VERSION ""

NS_ :

BS_:

BU_: EBOOST_CE TRCM_CE CGM_CE EPS_JR_CE MSB1_CE MSB2_CE ARS_CE SDM_CE EBCM_OBD_CE HCP_T_CE LCMS_CE APA_CE HCP_CE EOCM_F_CE MCP_C_CE MCP_B_CE MCP_A_CE FCM_CE ICCM_CE Dummy_CE TestTool_CE ACC_CE RDCM_CE EBCM_CE SADS_CE IMU_CE SAS_CE EPS_CE

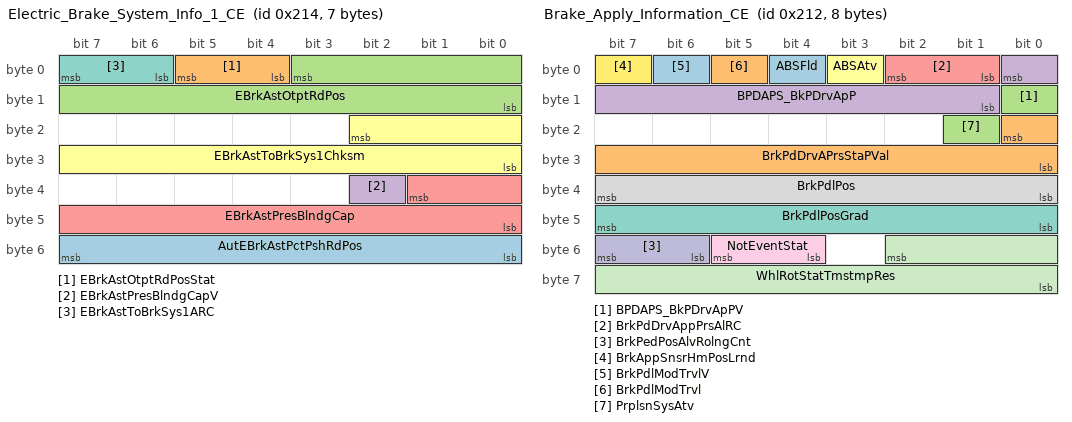
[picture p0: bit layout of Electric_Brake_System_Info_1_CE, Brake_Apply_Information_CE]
BO_ 532 Electric_Brake_System_Info_1_CE: 7 EBOOST_CE
 SG_ AutEBrkAstPctPshRdPos : 55|8@0+ (0.392157,0) [0|100.000035] "% full"  EBCM_OBD_CE,EBCM_CE
 SG_ EBrkAstOtptRdPosStat : 5|2@0+ (1,0) [0|3] ""  EBCM_OBD_CE,EBCM_CE
 SG_ EBrkAstOtptRdPos : 3|12@0+ (0.015625,-5) [-5|58.984375] "mm"  EBCM_OBD_CE,EBCM_CE
 SG_ EBrkAstPresBlndgCapV : 34|1@0+ (1,0) [0|1] ""  EBCM_OBD_CE,EBCM_CE
 SG_ EBrkAstPresBlndgCap : 33|10@0+ (0.25,0) [0|255.75] "bar"  EBCM_OBD_CE,EBCM_CE
 SG_ EBrkAstToBrkSys1Chksm : 18|11@0+ (1,0) [0|2047] ""  EBCM_OBD_CE,EBCM_CE
 SG_ EBrkAstToBrkSys1ARC : 7|2@0+ (1,0) [0|3] ""  EBCM_OBD_CE,EBCM_CE

BO_ 530 Brake_Apply_Information_CE: 8 EBCM_CE
 SG_ ABSFld : 4|1@0+ (1,0) [0|1] ""  SDM_CE,EPS_JR_CE
 SG_ BrkPdDrvAPrsStaPVal : 16|9@0+ (1,0) [0|511] ""  SADS_CE,MSB1_CE,MSB2_CE
 SG_ BPDAPS_BkPDrvApPV : 8|1@0+ (1,0) [0|1] ""  SADS_CE,MSB1_CE,MSB2_CE
 SG_ BPDAPS_BkPDrvApP : 0|8@0+ (75,0) [0|19125] "kPa"  SADS_CE,MSB1_CE,MSB2_CE
 SG_ BrkPdDrvAppPrsAlRC : 2|2@0+ (1,0) [0|3] ""  SADS_CE,MSB1_CE,MSB2_CE
 SG_ ABSAtv : 3|1@0+ (1,0) [0|1] ""  RDCM_CE,SDM_CE,MSB1_CE,MSB2_CE,EPS_JR_CE,EPS_CE
 SG_ BrkPdlPosGrad : 47|8@0- (40,0) [-5120|5080] "%/s"  EPS_JR_CE,MSB1_CE,MSB2_CE
 SG_ BrkPdlPos : 39|8@0+ (0.392157,0) [0|100.000035] "% full"  EPS_JR_CE,MSB1_CE,MSB2_CE
 SG_ NotEventStat : 53|2@0+ (1,0) [0|3] ""  EPS_JR_CE
 SG_ BrkPedPosAlvRolngCnt : 55|2@0+ (1,0) [0|3] ""  EPS_JR_CE
 SG_ WhlRotStatTmstmpRes : 50|11@0+ (0.002,0) [0|4.094] "uSec"  ARS_CE,APA_CE,RDCM_CE,EPS_JR_CE,EBOOST_CE
 SG_ BrkAppSnsrHmPosLrnd : 7|1@0+ (1,0) [0|1] ""  EPS_JR_CE
 SG_ BrkPdlModTrvlV : 6|1@0+ (1,0) [0|1] ""  EPS_JR_CE,MSB1_CE,MSB2_CE
 SG_ BrkPdlModTrvl : 5|1@0+ (1,0) [0|1] ""  EPS_JR_CE,MSB1_CE,MSB2_CE
 SG_ PrplsnSysAtv : 17|1@0+ (1,0) [0|1] ""  EBOOST_CE

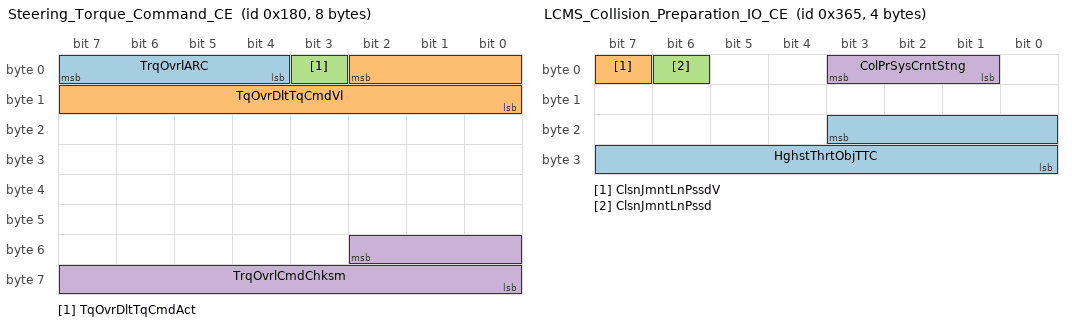
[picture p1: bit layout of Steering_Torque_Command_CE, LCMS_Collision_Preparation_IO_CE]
BO_ 384 Steering_Torque_Command_CE: 8 EBCM_CE
 SG_ TrqOvrlARC : 7|4@0+ (1,0) [0|15] "counts"  EPS_CE,EPS_JR_CE
 SG_ TqOvrDltTqCmdVl : 2|11@0- (0.01,0) [-10.24|10.23] "Nm"  EPS_CE,EPS_JR_CE
 SG_ TqOvrDltTqCmdAct : 3|1@0+ (1,0) [0|1] ""  EPS_CE,EPS_JR_CE
 SG_ TrqOvrlCmdChksm : 50|11@0+ (1,0) [0|2047] ""  EPS_CE,EPS_JR_CE

BO_ 869 LCMS_Collision_Preparation_IO_CE: 4 ACC_CE
 SG_ HghstThrtObjTTC : 19|12@0+ (2,0) [0|8190] "ms"  MSB1_CE,MSB2_CE
 SG_ ClsnJmntLnPssdV : 7|1@0+ (1,0) [0|1] ""  MSB1_CE,MSB2_CE
 SG_ ClsnJmntLnPssd : 6|1@0+ (1,0) [0|1] ""  MSB1_CE,MSB2_CE
 SG_ ColPrSysCrntStng : 3|3@0+ (1,0) [0|7] ""  MSB1_CE,MSB2_CE

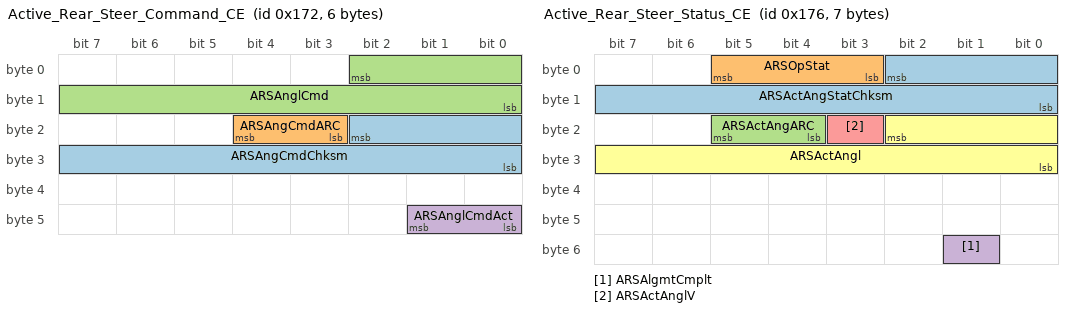
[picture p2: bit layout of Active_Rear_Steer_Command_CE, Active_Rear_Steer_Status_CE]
BO_ 370 Active_Rear_Steer_Command_CE: 6 EBCM_CE
 SG_ ARSAngCmdChksm : 18|11@0+ (1,0) [0|2047] ""  ARS_CE
 SG_ ARSAngCmdARC : 20|2@0+ (1,0) [0|3] ""  ARS_CE
 SG_ ARSAnglCmd : 2|11@0- (0.01,0) [-10.24|10.23] "deg"  ARS_CE
 SG_ ARSAnglCmdAct : 41|2@0+ (1,0) [0|3] ""  ARS_CE

BO_ 374 Active_Rear_Steer_Status_CE: 7 ARS_CE
 SG_ ARSActAngStatChksm : 2|11@0+ (1,0) [0|2047] ""  EOCM_F_CE,MSB2_CE,MSB1_CE,APA_CE,EBCM_OBD_CE,EBCM_CE
 SG_ ARSOpStat : 5|3@0+ (1,0) [0|7] ""  EOCM_F_CE,MSB2_CE,MSB1_CE,APA_CE,EBCM_OBD_CE,EBCM_CE
 SG_ ARSActAngARC : 21|2@0+ (1,0) [0|3] ""  MSB1_CE,EOCM_F_CE,MSB2_CE,APA_CE,EBCM_OBD_CE,EBCM_CE
 SG_ ARSAlgmtCmplt : 49|1@0+ (1,0) [0|1] ""  EOCM_F_CE,MSB2_CE,MSB1_CE,APA_CE,EBCM_OBD_CE,EBCM_CE
 SG_ ARSActAnglV : 19|1@0+ (1,0) [0|1] ""  MSB1_CE,EOCM_F_CE,MSB2_CE,APA_CE,EBCM_OBD_CE,EBCM_CE
 SG_ ARSActAngl : 18|11@0- (0.01,0) [-10.24|10.23] "deg"  EOCM_F_CE,MSB2_CE,MSB1_CE,APA_CE,EBCM_OBD_CE,EBCM_CE

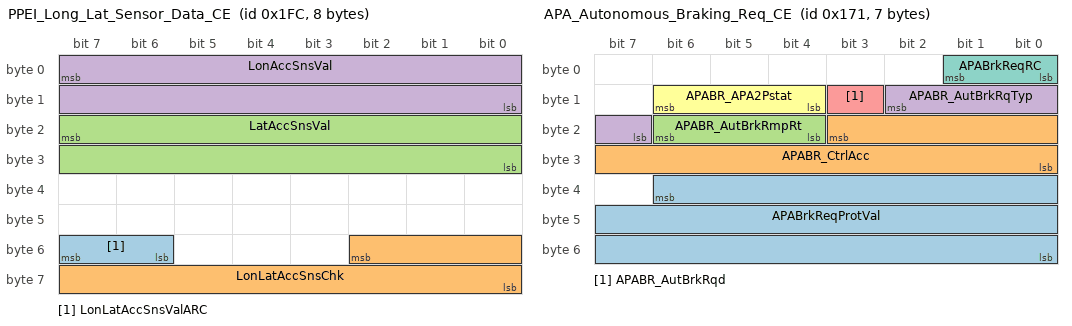
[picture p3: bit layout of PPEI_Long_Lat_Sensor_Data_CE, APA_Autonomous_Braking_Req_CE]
BO_ 508 PPEI_Long_Lat_Sensor_Data_CE: 8 IMU_CE
 SG_ LonLatAccSnsValARC : 55|2@0+ (1,0) [0|3] ""  EBCM_OBD_CE,EBCM_CE
 SG_ LonLatAccSnsChk : 50|11@0+ (1,0) [0|2047] ""  EBCM_OBD_CE,EBCM_CE
 SG_ LatAccSnsVal : 23|16@0- (0.00012207,0) [-3.99998976|3.99986769] "g's"  EBCM_OBD_CE,EBCM_CE
 SG_ LonAccSnsVal : 7|16@0- (0.00012207,0) [-3.99998976|3.99986769] "g's"  EBCM_OBD_CE,EBCM_CE

BO_ 2029 USDT_Resp_From_OBD_Device5_CE: 8 EBCM_OBD_CE
 SG_ DgnInf : 7|64@0+ (1,0) [0|1.84467440737096E+019] ""  TestTool_CE

BO_ 1517 UUDT_Resp_From_OBD_Device5_CE: 8 EBCM_OBD_CE
 SG_ DgnInf : 7|64@0+ (1,0) [0|1.84467440737096E+019] ""  TestTool_CE

BO_ 369 APA_Autonomous_Braking_Req_CE: 7 APA_CE
 SG_ APABrkReqProtVal : 38|23@0+ (1,0) [0|8388607] ""  EBCM_OBD_CE,EBCM_CE
 SG_ APABR_CtrlAcc : 19|12@0- (0.01,0) [-20.48|20.47] "m/s^2"  EBCM_OBD_CE,EBCM_CE
 SG_ APABR_AutBrkRmpRt : 22|3@0+ (1,0) [0|7] ""  EBCM_OBD_CE,EBCM_CE
 SG_ APABR_AutBrkRqTyp : 10|4@0+ (1,0) [0|15] ""  EBCM_OBD_CE,EBCM_CE
 SG_ APABR_AutBrkRqd : 11|1@0+ (1,0) [0|1] ""  EBCM_OBD_CE,EBCM_CE
 SG_ APABR_APA2Pstat : 14|3@0+ (1,0) [0|7] ""  EBCM_OBD_CE,EBCM_CE
 SG_ APABrkReqRC : 1|2@0+ (1,0) [0|3] ""  EBCM_OBD_CE,EBCM_CE

BO_ 2021 USDT_Req_to_OBD_Device5_CE: 8 TestTool_CE
 SG_ DgnInf : 7|64@0+ (1,0) [0|1.84467440737096E+019] ""  EBCM_OBD_CE

BO_ 562 Axle_Torque_Imm_Capacity_CE: 4 HCP_CE
 SG_ AxlTrqMinImTrqCap : 22|15@0+ (2,-22534) [-22534|43000] "Nm"  EBCM_OBD_CE,EBCM_CE
 SG_ AxlTrqMaxImTrqCap : 6|15@0+ (2,-22534) [-22534|43000] "Nm"  EBCM_OBD_CE,EBCM_CE

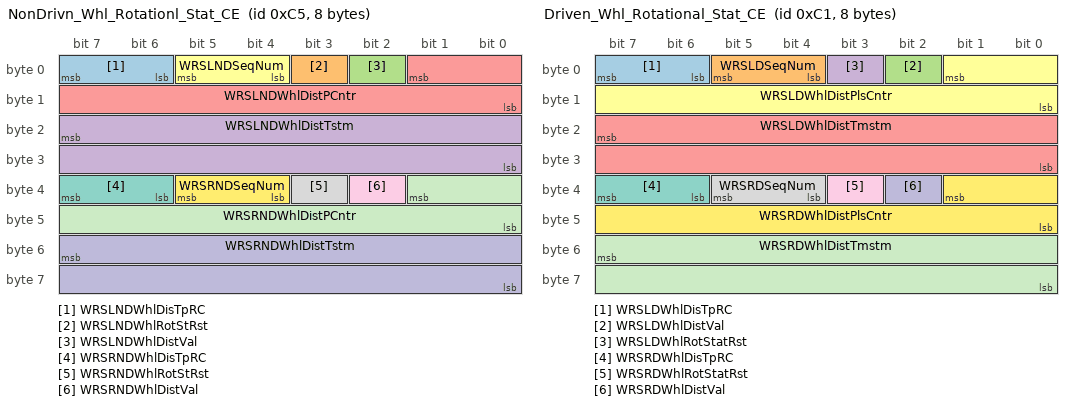
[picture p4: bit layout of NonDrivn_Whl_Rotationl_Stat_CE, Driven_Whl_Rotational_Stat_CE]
BO_ 197 NonDrivn_Whl_Rotationl_Stat_CE: 8 EBCM_CE
 SG_ WRSLNDWhlDisTpRC : 7|2@0+ (1,0) [0|3] "counts"  HCP_T_CE,HCP_CE,ICCM_CE,EPS_JR_CE,RDCM_CE,SDM_CE,ARS_CE,EOCM_F_CE,APA_CE
 SG_ WRSLNDWhlRotStRst : 3|1@0+ (1,0) [0|1] ""  HCP_T_CE,HCP_CE,ICCM_CE,EPS_JR_CE,RDCM_CE,SDM_CE,ARS_CE,EOCM_F_CE,APA_CE
 SG_ WRSLNDWhlDistVal : 2|1@0+ (1,0) [0|1] ""  HCP_T_CE,HCP_CE,ICCM_CE,EPS_JR_CE,RDCM_CE,SDM_CE,ARS_CE,EOCM_F_CE,APA_CE
 SG_ WRSLNDWhlDistTstm : 23|16@0+ (1,0) [0|65535] "counts"  HCP_T_CE,HCP_CE,ICCM_CE,EPS_JR_CE,RDCM_CE,SDM_CE,ARS_CE,EOCM_F_CE,APA_CE
 SG_ WRSLNDWhlDistPCntr : 1|10@0+ (1,0) [0|1023] "counts"  HCP_T_CE,HCP_CE,ICCM_CE,EPS_JR_CE,RDCM_CE,SDM_CE,ARS_CE,EOCM_F_CE,APA_CE
 SG_ WRSLNDSeqNum : 5|2@0+ (1,0) [0|3] "counts"  HCP_T_CE,HCP_CE,ICCM_CE,EPS_JR_CE,RDCM_CE,SDM_CE,ARS_CE,EOCM_F_CE,APA_CE
 SG_ WRSRNDWhlDisTpRC : 39|2@0+ (1,0) [0|3] "counts"  HCP_T_CE,HCP_CE,ICCM_CE,EPS_JR_CE,RDCM_CE,SDM_CE,ARS_CE,EOCM_F_CE,APA_CE
 SG_ WRSRNDWhlRotStRst : 35|1@0+ (1,0) [0|1] ""  HCP_T_CE,HCP_CE,ICCM_CE,EPS_JR_CE,RDCM_CE,SDM_CE,ARS_CE,EOCM_F_CE,APA_CE
 SG_ WRSRNDWhlDistVal : 34|1@0+ (1,0) [0|1] ""  HCP_T_CE,HCP_CE,ICCM_CE,EPS_JR_CE,RDCM_CE,SDM_CE,ARS_CE,EOCM_F_CE,APA_CE
 SG_ WRSRNDWhlDistTstm : 55|16@0+ (1,0) [0|65535] "counts"  HCP_T_CE,HCP_CE,ICCM_CE,EPS_JR_CE,RDCM_CE,SDM_CE,ARS_CE,EOCM_F_CE,APA_CE
 SG_ WRSRNDWhlDistPCntr : 33|10@0+ (1,0) [0|1023] "counts"  HCP_T_CE,HCP_CE,ICCM_CE,EPS_JR_CE,RDCM_CE,SDM_CE,ARS_CE,EOCM_F_CE,APA_CE
 SG_ WRSRNDSeqNum : 37|2@0+ (1,0) [0|3] "counts"  HCP_T_CE,HCP_CE,ICCM_CE,EPS_JR_CE,RDCM_CE,SDM_CE,ARS_CE,EOCM_F_CE,APA_CE

BO_ 193 Driven_Whl_Rotational_Stat_CE: 8 EBCM_CE
 SG_ WRSLDWhlDisTpRC : 7|2@0+ (1,0) [0|3] "counts"  TRCM_CE,HCP_T_CE,HCP_CE,ICCM_CE,EPS_JR_CE,RDCM_CE,SDM_CE,ARS_CE,EOCM_F_CE,APA_CE
 SG_ WRSLDSeqNum : 5|2@0+ (1,0) [0|3] "counts"  TRCM_CE,HCP_T_CE,HCP_CE,ICCM_CE,EPS_JR_CE,RDCM_CE,SDM_CE,ARS_CE,EOCM_F_CE,APA_CE
 SG_ WRSLDWhlDistVal : 2|1@0+ (1,0) [0|1] ""  TRCM_CE,HCP_T_CE,HCP_CE,ICCM_CE,EPS_JR_CE,RDCM_CE,SDM_CE,ARS_CE,EOCM_F_CE,APA_CE
 SG_ WRSLDWhlRotStatRst : 3|1@0+ (1,0) [0|1] ""  TRCM_CE,HCP_T_CE,HCP_CE,ICCM_CE,EPS_JR_CE,RDCM_CE,SDM_CE,ARS_CE,EOCM_F_CE,APA_CE
 SG_ WRSLDWhlDistTmstm : 23|16@0+ (1,0) [0|65535] "counts"  TRCM_CE,HCP_T_CE,HCP_CE,ICCM_CE,EPS_JR_CE,RDCM_CE,SDM_CE,ARS_CE,EOCM_F_CE,APA_CE
 SG_ WRSLDWhlDistPlsCntr : 1|10@0+ (1,0) [0|1023] "counts"  TRCM_CE,HCP_T_CE,HCP_CE,ICCM_CE,EPS_JR_CE,RDCM_CE,SDM_CE,ARS_CE,EOCM_F_CE,APA_CE
 SG_ WRSRDWhlDisTpRC : 39|2@0+ (1,0) [0|3] "counts"  TRCM_CE,HCP_T_CE,HCP_CE,ICCM_CE,EPS_JR_CE,RDCM_CE,SDM_CE,ARS_CE,EOCM_F_CE,APA_CE
 SG_ WRSRDSeqNum : 37|2@0+ (1,0) [0|3] "counts"  TRCM_CE,HCP_T_CE,HCP_CE,ICCM_CE,EPS_JR_CE,RDCM_CE,SDM_CE,ARS_CE,EOCM_F_CE,APA_CE
 SG_ WRSRDWhlRotStatRst : 35|1@0+ (1,0) [0|1] ""  TRCM_CE,HCP_T_CE,HCP_CE,ICCM_CE,EPS_JR_CE,RDCM_CE,SDM_CE,ARS_CE,EOCM_F_CE,APA_CE
 SG_ WRSRDWhlDistVal : 34|1@0+ (1,0) [0|1] ""  TRCM_CE,HCP_T_CE,HCP_CE,ICCM_CE,EPS_JR_CE,RDCM_CE,SDM_CE,ARS_CE,EOCM_F_CE,APA_CE
 SG_ WRSRDWhlDistTmstm : 55|16@0+ (1,0) [0|65535] "counts"  TRCM_CE,HCP_T_CE,HCP_CE,ICCM_CE,EPS_JR_CE,RDCM_CE,SDM_CE,ARS_CE,EOCM_F_CE,APA_CE
 SG_ WRSRDWhlDistPlsCntr : 33|10@0+ (1,0) [0|1023] "counts"  TRCM_CE,HCP_T_CE,HCP_CE,ICCM_CE,EPS_JR_CE,RDCM_CE,SDM_CE,ARS_CE,EOCM_F_CE,APA_CE

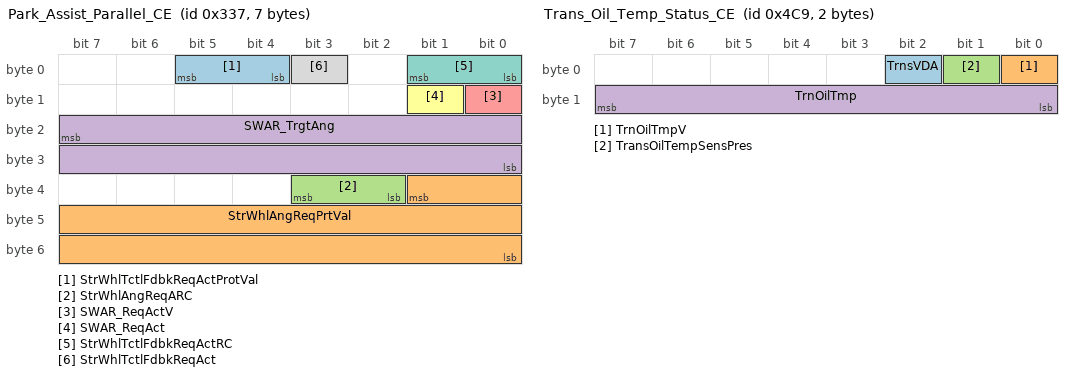
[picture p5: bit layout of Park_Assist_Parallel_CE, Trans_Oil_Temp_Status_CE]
BO_ 823 Park_Assist_Parallel_CE: 7 APA_CE
 SG_ StrWhlTctlFdbkReqActProtVal : 5|2@0+ (1,0) [0|3] ""  EPS_JR_CE,EPS_CE
 SG_ StrWhlAngReqPrtVal : 33|18@0+ (1,0) [0|262143] ""  EPS_JR_CE,EPS_CE
 SG_ StrWhlAngReqARC : 35|2@0+ (1,0) [0|3] ""  EPS_JR_CE,EPS_CE
 SG_ SWAR_TrgtAng : 23|16@0- (0.0625,0) [-2048|2047.9375] "Degree"  EPS_JR_CE,EPS_CE
 SG_ SWAR_ReqActV : 8|1@0+ (1,0) [0|1] ""  EPS_JR_CE,EPS_CE
 SG_ SWAR_ReqAct : 9|1@0+ (1,0) [0|1] ""  EPS_JR_CE,EPS_CE
 SG_ StrWhlTctlFdbkReqActRC : 1|2@0+ (1,0) [0|3] ""  EPS_CE,EPS_JR_CE
 SG_ StrWhlTctlFdbkReqAct : 3|1@0+ (1,0) [0|1] ""  EPS_CE,EPS_JR_CE

BO_ 1225 Trans_Oil_Temp_Status_CE: 2 ICCM_CE
 SG_ TrnsVDA : 2|1@0+ (1,0) [0|1] ""  RDCM_CE
 SG_ TrnOilTmpV : 0|1@0+ (1,0) [0|1] ""  RDCM_CE
 SG_ TransOilTempSensPres : 1|1@0+ (1,0) [0|1] ""  RDCM_CE
 SG_ TrnOilTmp : 15|8@0+ (1,-40) [-40|215] "deg C"  RDCM_CE

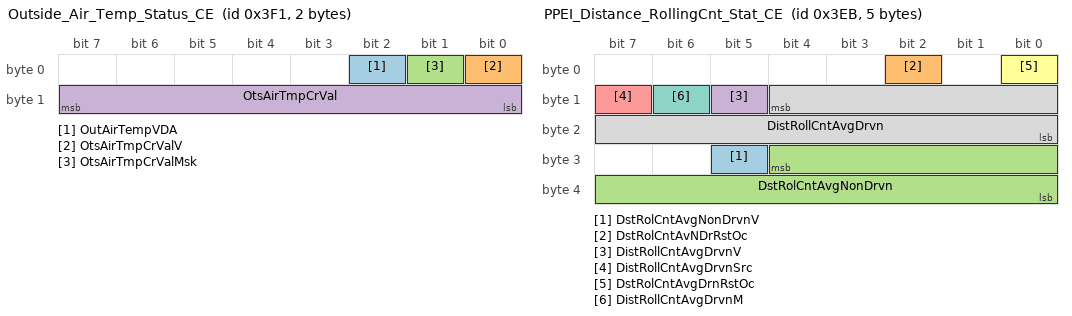
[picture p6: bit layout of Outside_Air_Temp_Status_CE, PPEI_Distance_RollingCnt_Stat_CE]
BO_ 1009 Outside_Air_Temp_Status_CE: 2 ICCM_CE
 SG_ OutAirTempVDA : 2|1@0+ (1,0) [0|1] ""  RDCM_CE
 SG_ OtsAirTmpCrValV : 0|1@0+ (1,0) [0|1] ""  RDCM_CE
 SG_ OtsAirTmpCrValMsk : 1|1@0+ (1,0) [0|1] ""  RDCM_CE
 SG_ OtsAirTmpCrVal : 15|8@0+ (0.5,-40) [-40|87.5] "deg C"  RDCM_CE

BO_ 536 PPEI_Vehicle_Speed_Status_1_CE: 6 ICCM_CE
 SG_ VehOdoV : 8|1@0+ (1,0) [0|1] ""  RDCM_CE
 SG_ VehOdo : 23|32@0+ (0.015625,0) [0|67108863.984375] "km"  RDCM_CE

BO_ 1003 PPEI_Distance_RollingCnt_Stat_CE: 5 EBCM_CE
 SG_ DstRolCntAvgNonDrvnV : 29|1@0+ (1,0) [0|1] ""  EPS_JR_CE
 SG_ DstRolCntAvNDrRstOc : 2|1@0+ (1,0) [0|1] ""  EPS_JR_CE
 SG_ DstRolCntAvgNonDrvn : 28|13@0+ (0.125,0) [0|1023.875] "m"  EPS_JR_CE
 SG_ DistRollCntAvgDrvnV : 13|1@0+ (1,0) [0|1] ""  EPS_JR_CE
 SG_ DistRollCntAvgDrvnSrc : 15|1@0+ (1,0) [0|1] ""  EPS_JR_CE
 SG_ DstRolCntAvgDrnRstOc : 0|1@0+ (1,0) [0|1] ""  EPS_JR_CE
 SG_ DistRollCntAvgDrvnM : 14|1@0+ (1,0) [0|1] ""  EPS_JR_CE
 SG_ DistRollCntAvgDrvn : 12|13@0+ (0.125,0) [0|1023.875] "m"  EPS_JR_CE

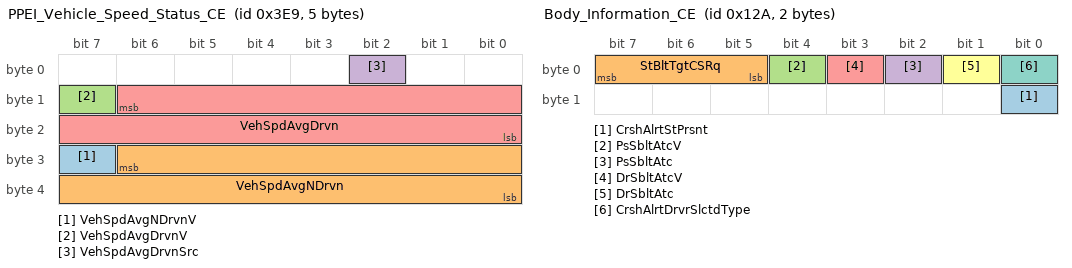
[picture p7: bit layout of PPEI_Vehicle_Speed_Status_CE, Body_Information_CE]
BO_ 1001 PPEI_Vehicle_Speed_Status_CE: 5 EBCM_CE
 SG_ VehSpdAvgNDrvnV : 31|1@0+ (1,0) [0|1] ""  ARS_CE,SDM_CE,FCM_CE,RDCM_CE,EPS_JR_CE
 SG_ VehSpdAvgNDrvn : 30|15@0+ (0.015625,0) [0|511.984375] "km / h"  ARS_CE,SDM_CE,FCM_CE,RDCM_CE,EPS_JR_CE
 SG_ VehSpdAvgDrvnV : 15|1@0+ (1,0) [0|1] ""  ARS_CE,SDM_CE,FCM_CE,EPS_JR_CE,EPS_CE
 SG_ VehSpdAvgDrvnSrc : 2|1@0+ (1,0) [0|1] ""  ARS_CE,EPS_JR_CE,EPS_CE
 SG_ VehSpdAvgDrvn : 14|15@0+ (0.015625,0) [0|511.984375] "km / h"  ARS_CE,SDM_CE,FCM_CE,EPS_JR_CE,EPS_CE

BO_ 298 Body_Information_CE: 2 EBCM_CE
 SG_ CrshAlrtStPrsnt : 8|1@0+ (1,0) [0|1] ""  MSB1_CE,MSB2_CE
 SG_ StBltTgtCSRq : 7|3@0+ (1,0) [0|7] ""  MSB1_CE,MSB2_CE
 SG_ PsSbltAtcV : 4|1@0+ (1,0) [0|1] ""  MSB1_CE,MSB2_CE
 SG_ PsSbltAtc : 2|1@0+ (1,0) [0|1] ""  MSB1_CE,MSB2_CE
 SG_ DrSbltAtcV : 3|1@0+ (1,0) [0|1] ""  MSB1_CE,MSB2_CE
 SG_ DrSbltAtc : 1|1@0+ (1,0) [0|1] ""  MSB1_CE,MSB2_CE
 SG_ CrshAlrtDrvrSlctdType : 0|1@0+ (1,0) [0|1] ""  MSB1_CE,MSB2_CE

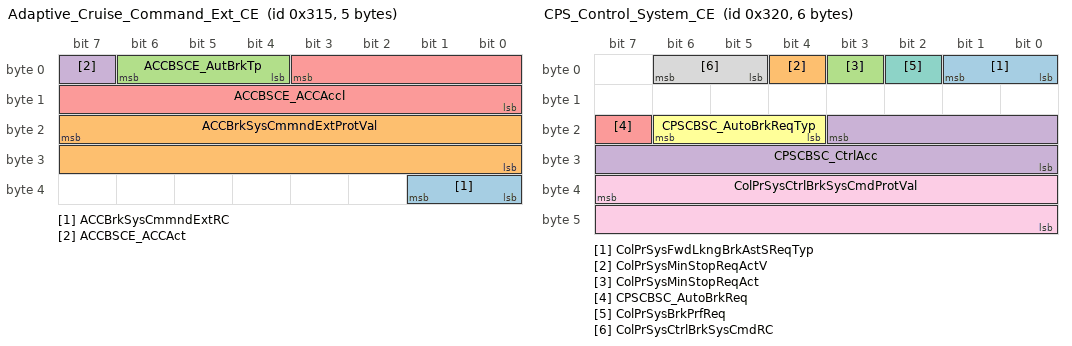
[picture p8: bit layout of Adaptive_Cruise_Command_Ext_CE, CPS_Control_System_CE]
BO_ 789 Adaptive_Cruise_Command_Ext_CE: 5 ACC_CE
 SG_ ACCBrkSysCmmndExtRC : 33|2@0+ (1,0) [0|3] ""  EBCM_OBD_CE,EBCM_CE
 SG_ ACCBrkSysCmmndExtProtVal : 23|16@0+ (1,0) [0|65535] ""  EBCM_OBD_CE,EBCM_CE
 SG_ ACCBSCE_AutBrkTp : 6|3@0+ (1,0) [0|7] ""  SADS_CE,EBCM_OBD_CE,EBCM_CE
 SG_ ACCBSCE_ACCAct : 7|1@0+ (1,0) [0|1] ""  SADS_CE,EBCM_OBD_CE,EBCM_CE
 SG_ ACCBSCE_ACCAccl : 3|12@0- (0.01,0) [-20.48|20.47] "m/s^2"  SADS_CE,EBCM_OBD_CE,EBCM_CE

BO_ 800 CPS_Control_System_CE: 6 ACC_CE
 SG_ ColPrSysFwdLkngBrkAstSReqTyp : 1|2@0+ (1,0) [0|3] ""  EOCM_F_CE,EBCM_OBD_CE,EBCM_CE
 SG_ ColPrSysMinStopReqActV : 4|1@0+ (1,0) [0|1] ""  EBCM_OBD_CE,EBCM_CE,EOCM_F_CE
 SG_ ColPrSysMinStopReqAct : 3|1@0+ (1,0) [0|1] ""  EOCM_F_CE,EBCM_OBD_CE,EBCM_CE
 SG_ CPSCBSC_CtrlAcc : 19|12@0- (0.01,0) [-20.48|20.47] "m/s^2"  EOCM_F_CE,EBCM_OBD_CE,EBCM_CE
 SG_ CPSCBSC_AutoBrkReq : 23|1@0+ (1,0) [0|1] ""  EOCM_F_CE,EBCM_OBD_CE,EBCM_CE
 SG_ CPSCBSC_AutoBrkReqTyp : 22|3@0+ (1,0) [0|7] ""  EOCM_F_CE,EBCM_OBD_CE,EBCM_CE
 SG_ ColPrSysBrkPrfReq : 2|1@0+ (1,0) [0|1] ""  EOCM_F_CE,EBCM_OBD_CE,EBCM_CE
 SG_ ColPrSysCtrlBrkSysCmdRC : 6|2@0+ (1,0) [0|3] ""  EOCM_F_CE,EBCM_OBD_CE,EBCM_CE
 SG_ ColPrSysCtrlBrkSysCmdProtVal : 39|16@0+ (1,0) [0|65535] ""  EOCM_F_CE,EBCM_OBD_CE,EBCM_CE

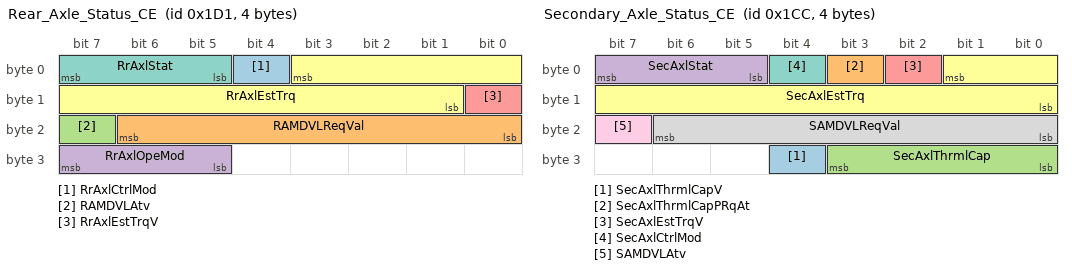
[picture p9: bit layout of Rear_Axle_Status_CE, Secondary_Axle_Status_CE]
BO_ 465 Rear_Axle_Status_CE: 4 RDCM_CE
 SG_ RrAxlCtrlMod : 4|1@0+ (1,0) [0|1] ""  EBCM_OBD_CE,EBCM_CE
 SG_ RAMDVLReqVal : 22|7@0+ (2,0) [0|254] "rpm"  EBCM_OBD_CE,EBCM_CE
 SG_ RAMDVLAtv : 23|1@0+ (1,0) [0|1] ""  EBCM_OBD_CE,EBCM_CE
 SG_ RrAxlOpeMod : 31|3@0+ (1,0) [0|7] ""  EBCM_OBD_CE,EBCM_CE
 SG_ RrAxlEstTrqV : 8|1@0+ (1,0) [0|1] ""  EBCM_OBD_CE,EBCM_CE
 SG_ RrAxlEstTrq : 3|11@0- (5,0) [-5120|5115] "Nm"  EBCM_OBD_CE,EBCM_CE
 SG_ RrAxlStat : 7|3@0+ (1,0) [0|7] ""  EBCM_OBD_CE,EBCM_CE

BO_ 460 Secondary_Axle_Status_CE: 4 RDCM_CE
 SG_ SecAxlThrmlCapV : 28|1@0+ (1,0) [0|1] ""  EBCM_OBD_CE,EBCM_CE
 SG_ SecAxlThrmlCapPRqAt : 3|1@0+ (1,0) [0|1] ""  EBCM_OBD_CE,EBCM_CE
 SG_ SecAxlThrmlCap : 27|4@0+ (6.7,0) [0|100.5] "%"  EBCM_OBD_CE,EBCM_CE
 SG_ SecAxlStat : 7|3@0+ (1,0) [0|7] ""  EBCM_OBD_CE,EBCM_CE
 SG_ SecAxlEstTrqV : 2|1@0+ (1,0) [0|1] ""  EBCM_OBD_CE,EBCM_CE
 SG_ SecAxlEstTrq : 1|10@0+ (10,0) [0|10230] "Nm"  EBCM_OBD_CE,EBCM_CE
 SG_ SecAxlCtrlMod : 4|1@0+ (1,0) [0|1] ""  EBCM_OBD_CE,EBCM_CE
 SG_ SAMDVLReqVal : 22|7@0+ (2,0) [0|254] ""  EBCM_OBD_CE,EBCM_CE
 SG_ SAMDVLAtv : 23|1@0+ (1,0) [0|1] ""  EBCM_OBD_CE,EBCM_CE

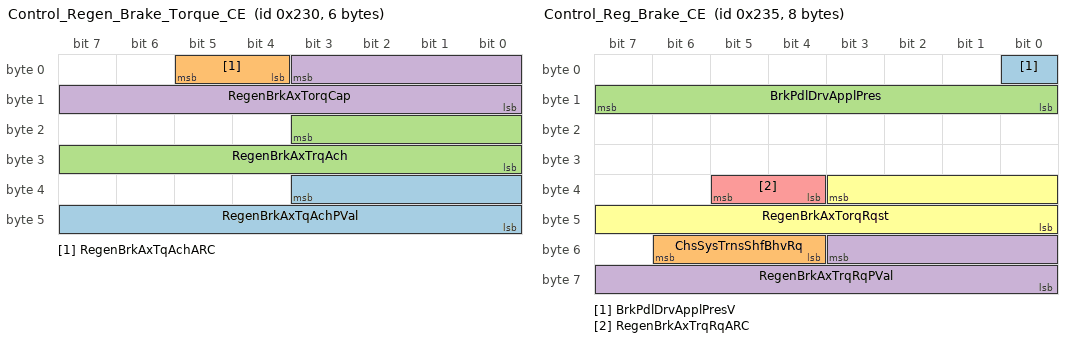
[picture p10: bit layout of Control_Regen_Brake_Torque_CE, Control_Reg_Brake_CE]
BO_ 560 Control_Regen_Brake_Torque_CE: 6 HCP_CE
 SG_ RegenBrkAxTqAchPVal : 35|12@0+ (1,0) [0|4095] ""  EBCM_OBD_CE,EBCM_CE
 SG_ RegenBrkAxTqAchARC : 5|2@0+ (1,0) [0|3] ""  EBCM_OBD_CE,EBCM_CE
 SG_ RegenBrkAxTrqAch : 19|12@0+ (2,0) [0|8190] "Nm"  EBCM_OBD_CE,EBCM_CE
 SG_ RegenBrkAxTorqCap : 3|12@0+ (2,0) [0|8190] "Nm"  EBCM_OBD_CE,EBCM_CE

BO_ 565 Control_Reg_Brake_CE: 8 EBCM_CE
 SG_ BrkPdlDrvApplPresV : 0|1@0+ (1,0) [0|1] ""  EPS_JR_CE
 SG_ ChsSysTrnsShfBhvRq : 54|3@0+ (1,0) [0|7] ""  HCP_T_CE,HCP_CE
 SG_ BrkPdlDrvApplPres : 15|8@0+ (75,0) [0|19125] "kPa"  EPS_JR_CE
 SG_ RegenBrkAxTrqRqPVal : 51|12@0+ (1,0) [0|4095] ""  HCP_T_CE,HCP_CE
 SG_ RegenBrkAxTrqRqARC : 37|2@0+ (1,0) [0|3] ""  HCP_T_CE,HCP_CE
 SG_ RegenBrkAxTorqRqst : 35|12@0+ (2,0) [0|8190] "Nm"  HCP_T_CE,HCP_CE

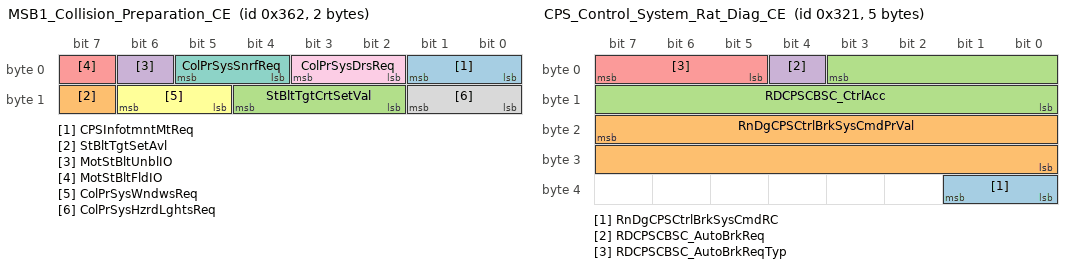
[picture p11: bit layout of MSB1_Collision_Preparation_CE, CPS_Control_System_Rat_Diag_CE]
BO_ 866 MSB1_Collision_Preparation_CE: 2 MSB1_CE
 SG_ CPSInfotmntMtReq : 1|2@0+ (1,0) [0|3] ""  EBCM_OBD_CE,EBCM_CE
 SG_ StBltTgtSetAvl : 15|1@0+ (1,0) [0|1] ""  EBCM_OBD_CE,EBCM_CE
 SG_ StBltTgtCrtSetVal : 12|3@0+ (1,0) [0|7] ""  EBCM_OBD_CE,EBCM_CE
 SG_ MotStBltUnblIO : 6|1@0+ (1,0) [0|1] ""  EBCM_OBD_CE,EBCM_CE
 SG_ MotStBltFldIO : 7|1@0+ (1,0) [0|1] ""  EBCM_OBD_CE,EBCM_CE
 SG_ ColPrSysWndwsReq : 14|2@0+ (1,0) [0|3] ""  EBCM_OBD_CE,EBCM_CE
 SG_ ColPrSysSnrfReq : 5|2@0+ (1,0) [0|3] ""  EBCM_OBD_CE,EBCM_CE
 SG_ ColPrSysHzrdLghtsReq : 9|2@0+ (1,0) [0|3] ""  EBCM_OBD_CE,EBCM_CE
 SG_ ColPrSysDrsReq : 3|2@0+ (1,0) [0|3] ""  EBCM_OBD_CE,EBCM_CE

BO_ 801 CPS_Control_System_Rat_Diag_CE: 5 ACC_CE
 SG_ RnDgCPSCtrlBrkSysCmdRC : 33|2@0+ (1,0) [0|3] ""  EBCM_OBD_CE,EBCM_CE
 SG_ RnDgCPSCtrlBrkSysCmdPrVal : 23|16@0+ (1,0) [0|65535] ""  EBCM_OBD_CE,EBCM_CE
 SG_ RDCPSCBSC_CtrlAcc : 3|12@0- (0.01,0) [-20.48|20.47] "m/s^2"  EBCM_OBD_CE,EBCM_CE
 SG_ RDCPSCBSC_AutoBrkReq : 4|1@0+ (1,0) [0|1] ""  EBCM_OBD_CE,EBCM_CE
 SG_ RDCPSCBSC_AutoBrkReqTyp : 7|3@0+ (1,0) [0|7] ""  EBCM_OBD_CE,EBCM_CE

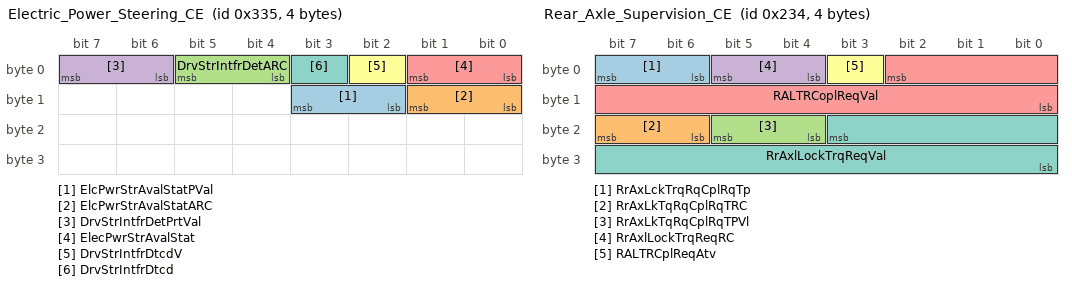
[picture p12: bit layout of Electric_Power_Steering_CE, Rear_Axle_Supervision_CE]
BO_ 821 Electric_Power_Steering_CE: 4 EPS_CE
 SG_ ElcPwrStrAvalStatPVal : 11|2@0+ (1,0) [0|3] ""  APA_CE
 SG_ ElcPwrStrAvalStatARC : 9|2@0+ (1,0) [0|3] ""  APA_CE
 SG_ DrvStrIntfrDetARC : 5|2@0+ (1,0) [0|3] ""  APA_CE
 SG_ DrvStrIntfrDetPrtVal : 7|2@0+ (1,0) [0|3] ""  APA_CE
 SG_ ElecPwrStrAvalStat : 1|2@0+ (1,0) [0|3] ""  APA_CE
 SG_ DrvStrIntfrDtcdV : 2|1@0+ (1,0) [0|1] ""  APA_CE
 SG_ DrvStrIntfrDtcd : 3|1@0+ (1,0) [0|1] ""  APA_CE

BO_ 564 Rear_Axle_Supervision_CE: 4 EBCM_CE
 SG_ RrAxLckTrqRqCplRqTp : 7|2@0+ (1,0) [0|3] ""  ICCM_CE,RDCM_CE
 SG_ RrAxLkTqRqCplRqTRC : 23|2@0+ (1,0) [0|3] ""  ICCM_CE,RDCM_CE
 SG_ RrAxLkTqRqCplRqTPVl : 21|2@0+ (1,0) [0|3] ""  ICCM_CE,RDCM_CE
 SG_ RrAxlLockTrqReqRC : 5|2@0+ (1,0) [0|3] ""  ICCM_CE,RDCM_CE
 SG_ RALTRCoplReqVal : 2|11@0+ (5,-5120) [-5120|5115] ""  ICCM_CE,RDCM_CE
 SG_ RALTRCplReqAtv : 3|1@0+ (1,0) [0|1] ""  ICCM_CE,RDCM_CE
 SG_ RrAxlLockTrqReqVal : 19|12@0+ (1,0) [0|4095] ""  ICCM_CE,RDCM_CE

BO_ 2015 USDT_OBD_Functional_Request_CE: 8 TestTool_CE
 SG_ DgnInf : 7|64@0+ (1,0) [0|1.84467440737096E+019] ""  HCP_T_CE,HCP_CE

BO_ 2025 USDT_Resp_From_HCP_CE: 8 HCP_CE
 SG_ DgnInf : 7|64@0+ (1,0) [0|1.84467440737096E+019] ""  TestTool_CE

BO_ 1513 UUDT_Resp_From_HCP_CE: 8 HCP_CE
 SG_ DgnInf : 7|64@0+ (1,0) [0|1.84467440737096E+019] ""  TestTool_CE

BO_ 2017 USDT_Req_to_HCP_CE: 8 TestTool_CE
 SG_ DgnInf : 7|64@0+ (1,0) [0|1.84467440737096E+019] ""  HCP_T_CE,HCP_CE

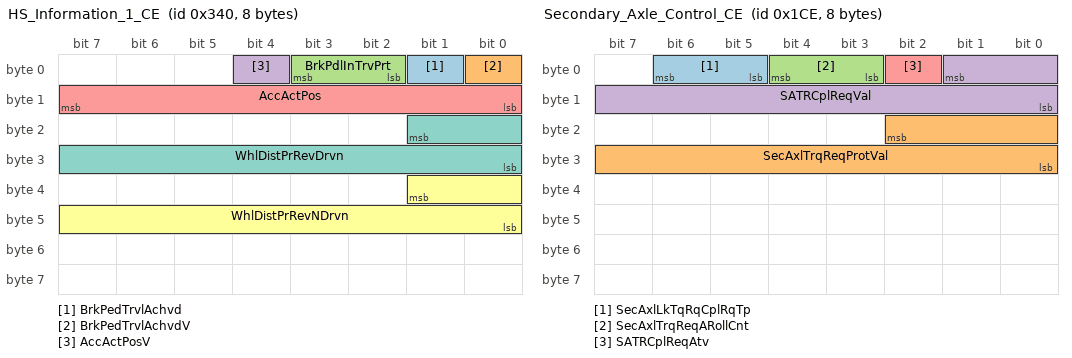
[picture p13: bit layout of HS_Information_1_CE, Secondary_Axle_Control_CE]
BO_ 832 HS_Information_1_CE: 8 EBCM_CE
 SG_ BrkPedTrvlAchvd : 1|1@0+ (1,0) [0|1] ""  SDM_CE,MSB1_CE,MSB2_CE,EPS_JR_CE
 SG_ BrkPedTrvlAchvdV : 0|1@0+ (1,0) [0|1] ""  SDM_CE,MSB1_CE,MSB2_CE,EPS_JR_CE
 SG_ BrkPdlInTrvPrt : 3|2@0+ (1,0) [0|3] ""  EPS_JR_CE
 SG_ AccActPosV : 4|1@0+ (1,0) [0|1] ""  FCM_CE,MSB1_CE,MSB2_CE
 SG_ AccActPos : 15|8@0+ (0.392157,0) [0|100.000035] "%"  FCM_CE,MSB1_CE,MSB2_CE
 SG_ WhlDistPrRevNDrvn : 33|10@0+ (3,800) [800|3869] "mm"  ARS_CE,EPS_CE,EPS_JR_CE,SDM_CE,APA_CE
 SG_ WhlDistPrRevDrvn : 17|10@0+ (3,800) [800|3869] "mm"  ARS_CE,EPS_JR_CE,EPS_CE,SDM_CE,APA_CE

BO_ 462 Secondary_Axle_Control_CE: 8 EBCM_CE
 SG_ SecAxlLkTqRqCplRqTp : 6|2@0+ (1,0) [0|3] ""  RDCM_CE
 SG_ SecAxlTrqReqProtVal : 18|11@0+ (1,0) [0|2047] "Counts"  RDCM_CE
 SG_ SecAxlTrqReqARollCnt : 4|2@0+ (1,0) [0|3] "Counts"  RDCM_CE
 SG_ SATRCplReqVal : 1|10@0+ (10,0) [0|10230] "Nm"  RDCM_CE
 SG_ SATRCplReqAtv : 2|1@0+ (1,0) [0|1] ""  RDCM_CE

BO_TX_BU_ 530 : EBCM_OBD_CE,EBCM_CE;
BO_TX_BU_ 384 : EBCM_OBD_CE,EBCM_CE;
BO_TX_BU_ 869 : EOCM_F_CE,ACC_CE;
BO_TX_BU_ 370 : EBCM_OBD_CE,EBCM_CE;
BO_TX_BU_ 508 : SDM_CE,IMU_CE;
BO_TX_BU_ 562 : HCP_T_CE,HCP_CE;
BO_TX_BU_ 197 : EBCM_OBD_CE,EBCM_CE;
BO_TX_BU_ 193 : EBCM_OBD_CE,EBCM_CE;
BO_TX_BU_ 1003 : EBCM_OBD_CE,EBCM_CE;
BO_TX_BU_ 1001 : EBCM_OBD_CE,EBCM_CE;
BO_TX_BU_ 298 : EBCM_OBD_CE,EBCM_CE;
BO_TX_BU_ 789 : EOCM_F_CE,ACC_CE;
BO_TX_BU_ 800 : FCM_CE,EOCM_F_CE,ACC_CE;
BO_TX_BU_ 465 : ICCM_CE,RDCM_CE;
BO_TX_BU_ 560 : HCP_T_CE,HCP_CE;
BO_TX_BU_ 565 : EBCM_OBD_CE,EBCM_CE;
BO_TX_BU_ 801 : FCM_CE,EOCM_F_CE,ACC_CE;
BO_TX_BU_ 821 : EPS_JR_CE,EPS_CE;
BO_TX_BU_ 564 : EBCM_OBD_CE,EBCM_CE;
BO_TX_BU_ 2025 : HCP_T_CE,HCP_CE;
BO_TX_BU_ 1513 : HCP_T_CE,HCP_CE;
BO_TX_BU_ 832 : EBCM_OBD_CE,EBCM_CE;
BO_TX_BU_ 462 : EBCM_OBD_CE,EBCM_CE;
CM_ SG_ 530 BrkPdlModTrvlV "Indicates that the brake pedal position has passed a threshold for brake torque management and some 2 channel Vehicle Dynamics Control systems.";
CM_ SG_ 530 BrkPdlModTrvl "Indicates that the brake pedal position has passed a threshold for brake torque management and some 2 channel Vehicle Dynamics Control systems.";
CM_ BO_ 197 "Application Is Tx ing this frame at the rate of 10 ms";
CM_ BO_ 193 "Application Is Tx ing this frame at the rate of 10 ms";
CM_ BO_ 789 "Note that the ACC algorithm will transmit this message at a 50 ms periodic rate and the EOCM algorithm will transmit this message at a 40 ms periodic rate";
CM_ BO_ 800 "Note that the ACC algorithm will transmit this message at a 50 ms periodic rate and the EOCM algorithm will transmit this message at a 40 ms periodic rate";
CM_ BO_ 465 "ICCM (inhouse) will be transmitting at 25 ms due to the PT handler";
CM_ BO_ 801 "Note that the ACC algorithm will transmit this message at a 50 ms periodic rate and the EOCM algorithm will transmit this message at a 40 ms periodic rate";
BA_DEF_ SG_  "VNSigSLHS_VNReq" ENUM  "No","Yes";
BA_DEF_ SG_  "VNSigSLHSSharedDiagnostic" ENUM  "No","Yes";
BA_DEF_ SG_  "SignalType" STRING ;
BA_DEF_ SG_  "PacketOrder" INT 0 65535;
BA_DEF_ SG_  "SignalLongName" STRING ;
BA_DEF_ SG_  "GenSigStartValue" INT 0 65535;
BA_DEF_ SG_  "VNSigAllNodes" ENUM  "No","Yes";
BA_DEF_ SG_  "GenSigDeltaValue" INT 0 0;
BA_DEF_ SG_  "GenSigSendType" ENUM  "not used","not used","not used","not used","not used","not used","not used","NoSigSendType","not used","not used","OnAnyChange","OnChangeIfActive","OnDelta";
BA_DEF_ SG_  "GenSigSendOnInit" ENUM  "Not Initialized","Application","Handler";
BA_DEF_ BO_  "AppGenMsgCycleTime" INT 0 0;
BA_DEF_ BO_  "GenMsgILSupport" ENUM  "No","Yes";
BA_DEF_ BO_  "TpApplType" STRING ;
BA_DEF_ BO_  "Prio" INT 0 7;
BA_DEF_ BO_  "MessageSubnet" ENUM  "LS","MS","HS","CE","PE","HV","FO","S1","HE","LE","HE2";
BA_DEF_ BO_  "GenMsgMandatoryToSupervision" ENUM  "No","Yes";
BA_DEF_ BO_  "DiagState" ENUM  "No","Yes";
BA_DEF_ BO_  "GenMsgDelayTime" INT 0 100000;
BA_DEF_ BO_  "GenMsgCycleTime" INT 0 100000;
BA_DEF_ BO_  "GenMsgSendType" ENUM  "cyclicX","spontanX","cyclicIfActiveX","spontanWithDelay","cyclicAndSpontanX","cyclicAndSpontanWithDelay","spontanWithRepitition","cyclicIfActiveAndSpontanWD";
BA_DEF_ BO_  "DiagResponse" ENUM  "No","Yes";
BA_DEF_ BO_  "DiagRequest" ENUM  "No","Yes";
BA_DEF_ BO_  "NmMessage" ENUM  "No","Yes";
BA_DEF_REL_ BU_SG_REL_  "GenSigSuprvRespComment" STRING ;
BA_DEF_REL_ BU_SG_REL_  "GenSigVBitResp" ENUM  "No","Yes";
BA_DEF_REL_ BU_SG_REL_  "GenSigVBitRespComment" STRING ;
BA_DEF_REL_ BU_SG_REL_  "GenSigVDAFailComment" STRING ;
BA_DEF_REL_ BU_SG_REL_  "GenSigVDAFailResp" ENUM  "No","Yes";
BA_DEF_REL_ BU_SG_REL_  "GenSigRxStartValue" STRING ;
BA_DEF_REL_ BU_SG_REL_  "GenSigSuprvResp" ENUM  "None","Notify App","Substitute Default";
BA_DEF_REL_ BU_SG_REL_  "GenSigTimeoutMsg" HEX -2147483648 268435455;
BA_DEF_REL_ BU_SG_REL_  "GenSigTimeoutTime" INT 0 15000;
BA_DEF_DEF_  "VNSigSLHS_VNReq" "No";
BA_DEF_DEF_  "VNSigSLHSSharedDiagnostic" "No";
BA_DEF_DEF_  "SignalType" "";
BA_DEF_DEF_  "PacketOrder" 0;
BA_DEF_DEF_  "SignalLongName" "";
BA_DEF_DEF_  "GenSigStartValue" 0;
BA_DEF_DEF_  "VNSigAllNodes" "No";
BA_DEF_DEF_  "GenSigDeltaValue" 0;
BA_DEF_DEF_  "GenSigSendType" "NoSigSendType";
BA_DEF_DEF_  "GenSigSendOnInit" "Not Initialized";
BA_DEF_DEF_  "AppGenMsgCycleTime" 0;
BA_DEF_DEF_  "GenMsgILSupport" "Yes";
BA_DEF_DEF_  "TpApplType" "";
BA_DEF_DEF_  "Prio" 4;
BA_DEF_DEF_  "MessageSubnet" "FO";
BA_DEF_DEF_  "GenMsgMandatoryToSupervision" "No";
BA_DEF_DEF_  "DiagState" "No";
BA_DEF_DEF_  "GenMsgDelayTime" 0;
BA_DEF_DEF_  "GenMsgCycleTime" 0;
BA_DEF_DEF_  "GenMsgSendType" "spontanX";
BA_DEF_DEF_  "DiagResponse" "No";
BA_DEF_DEF_  "DiagRequest" "No";
BA_DEF_DEF_  "NmMessage" "No";
BA_DEF_DEF_REL_ "GenSigSuprvRespComment" "";
BA_DEF_DEF_REL_ "GenSigVBitResp" "No";
BA_DEF_DEF_REL_ "GenSigVBitRespComment" "";
BA_DEF_DEF_REL_ "GenSigVDAFailComment" "";
BA_DEF_DEF_REL_ "GenSigVDAFailResp" "No";
BA_DEF_DEF_REL_ "GenSigRxStartValue" "";
BA_DEF_DEF_REL_ "GenSigSuprvResp" "None";
BA_DEF_DEF_REL_ "GenSigTimeoutMsg" 0;
BA_DEF_DEF_REL_ "GenSigTimeoutTime" 0;
BA_ "Prio" BO_ 532 0;
BA_ "MessageSubnet" BO_ 532 3;
BA_ "GenMsgCycleTime" BO_ 532 10;
BA_ "GenMsgSendType" BO_ 532 0;
BA_ "Prio" BO_ 530 0;
BA_ "MessageSubnet" BO_ 530 3;
BA_ "GenMsgCycleTime" BO_ 530 25;
BA_ "GenMsgSendType" BO_ 530 0;
BA_ "Prio" BO_ 384 0;
BA_ "MessageSubnet" BO_ 384 3;
BA_ "GenMsgCycleTime" BO_ 384 20;
BA_ "GenMsgSendType" BO_ 384 0;
BA_ "Prio" BO_ 869 0;
BA_ "MessageSubnet" BO_ 869 3;
BA_ "GenMsgCycleTime" BO_ 869 50;
BA_ "GenMsgSendType" BO_ 869 0;
BA_ "Prio" BO_ 370 0;
BA_ "MessageSubnet" BO_ 370 3;
BA_ "GenMsgCycleTime" BO_ 370 10;
BA_ "GenMsgSendType" BO_ 370 0;
BA_ "Prio" BO_ 374 0;
BA_ "MessageSubnet" BO_ 374 3;
BA_ "GenMsgCycleTime" BO_ 374 10;
BA_ "GenMsgSendType" BO_ 374 0;
BA_ "Prio" BO_ 508 0;
BA_ "MessageSubnet" BO_ 508 3;
BA_ "GenMsgCycleTime" BO_ 508 50;
BA_ "GenMsgSendType" BO_ 508 0;
BA_ "Prio" BO_ 2029 0;
BA_ "MessageSubnet" BO_ 2029 3;
BA_ "DiagResponse" BO_ 2029 1;
BA_ "GenMsgILSupport" BO_ 1517 0;
BA_ "TpApplType" BO_ 1517 "DiagUUDTResponse";
BA_ "Prio" BO_ 1517 0;
BA_ "MessageSubnet" BO_ 1517 3;
BA_ "AppGenMsgCycleTime" BO_ 369 100;
BA_ "Prio" BO_ 369 0;
BA_ "MessageSubnet" BO_ 369 3;
BA_ "Prio" BO_ 2021 0;
BA_ "MessageSubnet" BO_ 2021 3;
BA_ "DiagRequest" BO_ 2021 1;
BA_ "Prio" BO_ 562 0;
BA_ "MessageSubnet" BO_ 562 3;
BA_ "GenMsgCycleTime" BO_ 562 25;
BA_ "GenMsgSendType" BO_ 562 0;
BA_ "AppGenMsgCycleTime" BO_ 197 10;
BA_ "Prio" BO_ 197 0;
BA_ "MessageSubnet" BO_ 197 3;
BA_ "AppGenMsgCycleTime" BO_ 193 10;
BA_ "Prio" BO_ 193 0;
BA_ "MessageSubnet" BO_ 193 3;
BA_ "Prio" BO_ 823 0;
BA_ "MessageSubnet" BO_ 823 3;
BA_ "GenMsgCycleTime" BO_ 823 20;
BA_ "GenMsgSendType" BO_ 823 0;
BA_ "Prio" BO_ 1225 0;
BA_ "MessageSubnet" BO_ 1225 3;
BA_ "GenMsgCycleTime" BO_ 1225 500;
BA_ "GenMsgSendType" BO_ 1225 0;
BA_ "Prio" BO_ 1009 0;
BA_ "MessageSubnet" BO_ 1009 3;
BA_ "GenMsgCycleTime" BO_ 1009 250;
BA_ "GenMsgSendType" BO_ 1009 0;
BA_ "Prio" BO_ 536 0;
BA_ "MessageSubnet" BO_ 536 3;
BA_ "GenMsgCycleTime" BO_ 536 5000;
BA_ "GenMsgSendType" BO_ 536 0;
BA_ "Prio" BO_ 1003 0;
BA_ "MessageSubnet" BO_ 1003 3;
BA_ "GenMsgCycleTime" BO_ 1003 100;
BA_ "GenMsgSendType" BO_ 1003 0;
BA_ "Prio" BO_ 1001 0;
BA_ "MessageSubnet" BO_ 1001 3;
BA_ "GenMsgCycleTime" BO_ 1001 100;
BA_ "GenMsgSendType" BO_ 1001 0;
BA_ "Prio" BO_ 298 0;
BA_ "MessageSubnet" BO_ 298 3;
BA_ "GenMsgCycleTime" BO_ 298 100;
BA_ "GenMsgSendType" BO_ 298 0;
BA_ "AppGenMsgCycleTime" BO_ 789 40;
BA_ "Prio" BO_ 789 0;
BA_ "MessageSubnet" BO_ 789 3;
BA_ "AppGenMsgCycleTime" BO_ 800 40;
BA_ "Prio" BO_ 800 0;
BA_ "MessageSubnet" BO_ 800 3;
BA_ "Prio" BO_ 465 0;
BA_ "MessageSubnet" BO_ 465 3;
BA_ "GenMsgCycleTime" BO_ 465 20;
BA_ "GenMsgSendType" BO_ 465 0;
BA_ "Prio" BO_ 460 0;
BA_ "MessageSubnet" BO_ 460 3;
BA_ "GenMsgCycleTime" BO_ 460 20;
BA_ "GenMsgSendType" BO_ 460 0;
BA_ "Prio" BO_ 560 0;
BA_ "MessageSubnet" BO_ 560 3;
BA_ "GenMsgCycleTime" BO_ 560 12;
BA_ "GenMsgSendType" BO_ 560 0;
BA_ "Prio" BO_ 565 0;
BA_ "MessageSubnet" BO_ 565 3;
BA_ "GenMsgCycleTime" BO_ 565 10;
BA_ "GenMsgSendType" BO_ 565 0;
BA_ "Prio" BO_ 866 0;
BA_ "MessageSubnet" BO_ 866 3;
BA_ "GenMsgCycleTime" BO_ 866 50;
BA_ "GenMsgSendType" BO_ 866 0;
BA_ "AppGenMsgCycleTime" BO_ 801 40;
BA_ "Prio" BO_ 801 0;
BA_ "MessageSubnet" BO_ 801 3;
BA_ "Prio" BO_ 821 0;
BA_ "MessageSubnet" BO_ 821 3;
BA_ "GenMsgCycleTime" BO_ 821 20;
BA_ "GenMsgSendType" BO_ 821 0;
BA_ "Prio" BO_ 564 0;
BA_ "MessageSubnet" BO_ 564 3;
BA_ "GenMsgCycleTime" BO_ 564 20;
BA_ "GenMsgSendType" BO_ 564 0;
BA_ "GenMsgILSupport" BO_ 2015 0;
BA_ "Prio" BO_ 2015 0;
BA_ "MessageSubnet" BO_ 2015 3;
BA_ "Prio" BO_ 2025 0;
BA_ "MessageSubnet" BO_ 2025 3;
BA_ "DiagResponse" BO_ 2025 1;
BA_ "GenMsgILSupport" BO_ 1513 0;
BA_ "TpApplType" BO_ 1513 "DiagUUDTResponse";
BA_ "Prio" BO_ 1513 0;
BA_ "MessageSubnet" BO_ 1513 3;
BA_ "Prio" BO_ 2017 0;
BA_ "MessageSubnet" BO_ 2017 3;
BA_ "DiagRequest" BO_ 2017 1;
BA_ "Prio" BO_ 832 0;
BA_ "MessageSubnet" BO_ 832 3;
BA_ "GenMsgCycleTime" BO_ 832 100;
BA_ "GenMsgSendType" BO_ 832 0;
BA_ "Prio" BO_ 462 0;
BA_ "MessageSubnet" BO_ 462 3;
BA_ "GenMsgCycleTime" BO_ 462 20;
BA_ "GenMsgSendType" BO_ 462 0;
BA_ "SignalType" SG_ 532 AutEBrkAstPctPshRdPos "UNM";
BA_ "SignalLongName" SG_ 532 AutEBrkAstPctPshRdPos "Autonomous EbrakeAssist Percent of Push Rod Position";
BA_ "VNSigAllNodes" SG_ 532 AutEBrkAstPctPshRdPos 1;
BA_ "SignalType" SG_ 532 EBrkAstOtptRdPosStat "ENM";
BA_ "SignalLongName" SG_ 532 EBrkAstOtptRdPosStat "EBrakeAssist Output Rod Position Status";
BA_ "VNSigAllNodes" SG_ 532 EBrkAstOtptRdPosStat 1;
BA_ "SignalType" SG_ 532 EBrkAstOtptRdPos "UNM";
BA_ "SignalLongName" SG_ 532 EBrkAstOtptRdPos "EBrakeAssist Output Rod Position";
BA_ "VNSigAllNodes" SG_ 532 EBrkAstOtptRdPos 1;
BA_ "SignalType" SG_ 532 EBrkAstPresBlndgCapV "ENM";
BA_ "SignalLongName" SG_ 532 EBrkAstPresBlndgCapV "EBrakeAssist Pressure Blending Capacity Validity";
BA_ "VNSigAllNodes" SG_ 532 EBrkAstPresBlndgCapV 1;
BA_ "SignalType" SG_ 532 EBrkAstPresBlndgCap "UNM";
BA_ "SignalLongName" SG_ 532 EBrkAstPresBlndgCap "EBrakeAssist Pressure Blending Capacity";
BA_ "VNSigAllNodes" SG_ 532 EBrkAstPresBlndgCap 1;
BA_ "SignalType" SG_ 532 EBrkAstToBrkSys1Chksm "UNM";
BA_ "SignalLongName" SG_ 532 EBrkAstToBrkSys1Chksm "EBrakeAssist to Brake System 1 Checksum";
BA_ "VNSigAllNodes" SG_ 532 EBrkAstToBrkSys1Chksm 1;
BA_ "SignalType" SG_ 532 EBrkAstToBrkSys1ARC "UNM";
BA_ "SignalLongName" SG_ 532 EBrkAstToBrkSys1ARC "EBrakeAssist to Brake System 1 Alive Rolling Count";
BA_ "VNSigAllNodes" SG_ 532 EBrkAstToBrkSys1ARC 1;
BA_ "SignalType" SG_ 530 ABSFld "BLN";
BA_ "SignalLongName" SG_ 530 ABSFld "Antilock Brake System Failed";
BA_ "VNSigAllNodes" SG_ 530 ABSFld 1;
BA_ "SignalType" SG_ 530 BrkPdDrvAPrsStaPVal "UNM";
BA_ "SignalLongName" SG_ 530 BrkPdDrvAPrsStaPVal "Brake Pedal Driver Applied Pressure Status Protection Value";
BA_ "VNSigAllNodes" SG_ 530 BrkPdDrvAPrsStaPVal 1;
BA_ "SignalType" SG_ 530 BPDAPS_BkPDrvApPV "ENM";
BA_ "PacketOrder" SG_ 530 BPDAPS_BkPDrvApPV 2;
BA_ "SignalLongName" SG_ 530 BPDAPS_BkPDrvApPV "Brake Pedal Driver Applied Pressure Status : Brake Pedal Driver Applied Pressure Validity";
BA_ "VNSigAllNodes" SG_ 530 BPDAPS_BkPDrvApPV 1;
BA_ "SignalType" SG_ 530 BPDAPS_BkPDrvApP "UNM";
BA_ "PacketOrder" SG_ 530 BPDAPS_BkPDrvApP 1;
BA_ "SignalLongName" SG_ 530 BPDAPS_BkPDrvApP "Brake Pedal Driver Applied Pressure Status : Brake Pedal Driver Applied Pressure";
BA_ "VNSigAllNodes" SG_ 530 BPDAPS_BkPDrvApP 1;
BA_ "SignalType" SG_ 530 BrkPdDrvAppPrsAlRC "UNM";
BA_ "SignalLongName" SG_ 530 BrkPdDrvAppPrsAlRC "Brake Pedal Driver Applied Pressure Alive Rolling Count";
BA_ "VNSigAllNodes" SG_ 530 BrkPdDrvAppPrsAlRC 1;
BA_ "SignalType" SG_ 530 ABSAtv "BLN";
BA_ "SignalLongName" SG_ 530 ABSAtv "Antilock Brake System Active";
BA_ "VNSigAllNodes" SG_ 530 ABSAtv 1;
BA_ "SignalType" SG_ 530 BrkPdlPosGrad "SNM";
BA_ "SignalLongName" SG_ 530 BrkPdlPosGrad "Brake Pedal Position Gradient";
BA_ "VNSigAllNodes" SG_ 530 BrkPdlPosGrad 1;
BA_ "SignalType" SG_ 530 BrkPdlPos "UNM";
BA_ "SignalLongName" SG_ 530 BrkPdlPos "Brake Pedal Position";
BA_ "VNSigAllNodes" SG_ 530 BrkPdlPos 1;
BA_ "SignalType" SG_ 530 NotEventStat "ENM";
BA_ "SignalLongName" SG_ 530 NotEventStat "Notification Event Status";
BA_ "VNSigAllNodes" SG_ 530 NotEventStat 1;
BA_ "SignalType" SG_ 530 BrkPedPosAlvRolngCnt "UNM";
BA_ "SignalLongName" SG_ 530 BrkPedPosAlvRolngCnt "Brake Pedal Position Alive Rolling Count";
BA_ "VNSigAllNodes" SG_ 530 BrkPedPosAlvRolngCnt 1;
BA_ "SignalType" SG_ 530 WhlRotStatTmstmpRes "UNM";
BA_ "SignalLongName" SG_ 530 WhlRotStatTmstmpRes "Wheel Rotational Status Timestamp Resolution";
BA_ "VNSigAllNodes" SG_ 530 WhlRotStatTmstmpRes 1;
BA_ "SignalType" SG_ 530 BrkAppSnsrHmPosLrnd "BLN";
BA_ "SignalLongName" SG_ 530 BrkAppSnsrHmPosLrnd "Brake Apply Sensor Home Position Learned";
BA_ "VNSigAllNodes" SG_ 530 BrkAppSnsrHmPosLrnd 1;
BA_ "SignalType" SG_ 530 BrkPdlModTrvlV "ENM";
BA_ "SignalLongName" SG_ 530 BrkPdlModTrvlV "Brake Pedal Moderate Travel Achieved Validity";
BA_ "VNSigAllNodes" SG_ 530 BrkPdlModTrvlV 1;
BA_ "SignalType" SG_ 530 BrkPdlModTrvl "BLN";
BA_ "SignalLongName" SG_ 530 BrkPdlModTrvl "Brake Pedal Moderate Travel Achieved";
BA_ "VNSigAllNodes" SG_ 530 BrkPdlModTrvl 1;
BA_ "SignalType" SG_ 530 PrplsnSysAtv "BLN";
BA_ "SignalLongName" SG_ 530 PrplsnSysAtv "Propulsion System Active";
BA_ "VNSigAllNodes" SG_ 530 PrplsnSysAtv 1;
BA_ "SignalType" SG_ 384 TrqOvrlARC "UNM";
BA_ "SignalLongName" SG_ 384 TrqOvrlARC "Torque Overlay Alive Rolling Count";
BA_ "VNSigAllNodes" SG_ 384 TrqOvrlARC 1;
BA_ "SignalType" SG_ 384 TqOvrDltTqCmdVl "SNM";
BA_ "SignalLongName" SG_ 384 TqOvrDltTqCmdVl "Torque Overlay Delta Torque Command Value";
BA_ "VNSigAllNodes" SG_ 384 TqOvrDltTqCmdVl 1;
BA_ "SignalType" SG_ 384 TqOvrDltTqCmdAct "ENM";
BA_ "SignalLongName" SG_ 384 TqOvrDltTqCmdAct "Torque Overlay Delta Torque Command Active";
BA_ "VNSigAllNodes" SG_ 384 TqOvrDltTqCmdAct 1;
BA_ "SignalType" SG_ 384 TrqOvrlCmdChksm "UNM";
BA_ "SignalLongName" SG_ 384 TrqOvrlCmdChksm "Torque Overlay Command Checksum";
BA_ "VNSigAllNodes" SG_ 384 TrqOvrlCmdChksm 1;
BA_ "SignalType" SG_ 869 HghstThrtObjTTC "UNM";
BA_ "SignalLongName" SG_ 869 HghstThrtObjTTC "Highest Threat Object Time-to-Collision";
BA_ "VNSigAllNodes" SG_ 869 HghstThrtObjTTC 1;
BA_ "SignalType" SG_ 869 ClsnJmntLnPssdV "ENM";
BA_ "SignalLongName" SG_ 869 ClsnJmntLnPssdV "Collision Judgement Line Passed Validity";
BA_ "VNSigAllNodes" SG_ 869 ClsnJmntLnPssdV 1;
BA_ "SignalType" SG_ 869 ClsnJmntLnPssd "BLN";
BA_ "SignalLongName" SG_ 869 ClsnJmntLnPssd "Collision Judgement Line Passed";
BA_ "VNSigAllNodes" SG_ 869 ClsnJmntLnPssd 1;
BA_ "SignalType" SG_ 869 ColPrSysCrntStng "ENM";
BA_ "SignalLongName" SG_ 869 ColPrSysCrntStng "Collision Preparation System Current Setting Value";
BA_ "VNSigAllNodes" SG_ 869 ColPrSysCrntStng 1;
BA_ "SignalType" SG_ 370 ARSAngCmdChksm "UNM";
BA_ "SignalLongName" SG_ 370 ARSAngCmdChksm "Active Rear Steering Angle Command Checksum";
BA_ "VNSigAllNodes" SG_ 370 ARSAngCmdChksm 1;
BA_ "SignalType" SG_ 370 ARSAngCmdARC "UNM";
BA_ "SignalLongName" SG_ 370 ARSAngCmdARC "Active Rear Steer Angle Command Alive Rolling Count";
BA_ "VNSigAllNodes" SG_ 370 ARSAngCmdARC 1;
BA_ "SignalType" SG_ 370 ARSAnglCmd "SNM";
BA_ "SignalLongName" SG_ 370 ARSAnglCmd "Active Rear Steer Angle Command";
BA_ "VNSigAllNodes" SG_ 370 ARSAnglCmd 1;
BA_ "SignalType" SG_ 370 ARSAnglCmdAct "ENM";
BA_ "SignalLongName" SG_ 370 ARSAnglCmdAct "Active Rear Steer Angle Command Active";
BA_ "VNSigAllNodes" SG_ 370 ARSAnglCmdAct 1;
BA_ "SignalType" SG_ 374 ARSActAngStatChksm "UNM";
BA_ "SignalLongName" SG_ 374 ARSActAngStatChksm "Active Rear Steer Actual Angle Status Checksum";
BA_ "VNSigAllNodes" SG_ 374 ARSActAngStatChksm 1;
BA_ "SignalType" SG_ 374 ARSOpStat "ENM";
BA_ "SignalLongName" SG_ 374 ARSOpStat "Active Rear Steer Operational Status";
BA_ "VNSigAllNodes" SG_ 374 ARSOpStat 1;
BA_ "SignalType" SG_ 374 ARSActAngARC "UNM";
BA_ "SignalLongName" SG_ 374 ARSActAngARC "Active Rear Steer Actual Angle Alive Rolling Count";
BA_ "VNSigAllNodes" SG_ 374 ARSActAngARC 1;
BA_ "SignalType" SG_ 374 ARSAlgmtCmplt "BLN";
BA_ "SignalLongName" SG_ 374 ARSAlgmtCmplt "Active Rear Steer Alignment Complete";
BA_ "VNSigAllNodes" SG_ 374 ARSAlgmtCmplt 1;
BA_ "SignalType" SG_ 374 ARSActAnglV "ENM";
BA_ "SignalLongName" SG_ 374 ARSActAnglV "Active Rear Steer Actual Angle Validity";
BA_ "VNSigAllNodes" SG_ 374 ARSActAnglV 1;
BA_ "SignalType" SG_ 374 ARSActAngl "SNM";
BA_ "SignalLongName" SG_ 374 ARSActAngl "Active Rear Steer Actual Angle";
BA_ "VNSigAllNodes" SG_ 374 ARSActAngl 1;
BA_ "SignalType" SG_ 508 LonLatAccSnsValARC "UNM";
BA_ "SignalLongName" SG_ 508 LonLatAccSnsValARC "Longitudinal/Lateral Acceleration Sensor Value Alive Rolling Count";
BA_ "VNSigAllNodes" SG_ 508 LonLatAccSnsValARC 1;
BA_ "SignalType" SG_ 508 LonLatAccSnsChk "UNM";
BA_ "SignalLongName" SG_ 508 LonLatAccSnsChk "Longitudinal/Lateral Acceleration Sensor Checksum";
BA_ "VNSigAllNodes" SG_ 508 LonLatAccSnsChk 1;
BA_ "SignalType" SG_ 508 LatAccSnsVal "SNM";
BA_ "SignalLongName" SG_ 508 LatAccSnsVal "Lateral Acceleration Sensor Value";
BA_ "VNSigAllNodes" SG_ 508 LatAccSnsVal 1;
BA_ "SignalType" SG_ 508 LonAccSnsVal "SNM";
BA_ "SignalLongName" SG_ 508 LonAccSnsVal "Longitudinal Acceleration Sensor Value";
BA_ "VNSigAllNodes" SG_ 508 LonAccSnsVal 1;
BA_ "VNSigSLHSSharedDiagnostic" SG_ 2029 DgnInf 1;
BA_ "SignalType" SG_ 2029 DgnInf "UNM";
BA_ "SignalLongName" SG_ 2029 DgnInf "Diagnostic Information";
BA_ "VNSigAllNodes" SG_ 2029 DgnInf 1;
BA_ "VNSigSLHSSharedDiagnostic" SG_ 1517 DgnInf 1;
BA_ "SignalType" SG_ 1517 DgnInf "UNM";
BA_ "SignalLongName" SG_ 1517 DgnInf "Diagnostic Information";
BA_ "VNSigAllNodes" SG_ 1517 DgnInf 1;
BA_ "GenSigDeltaValue" SG_ 369 APABrkReqProtVal 1;
BA_ "GenSigSendType" SG_ 369 APABrkReqProtVal 12;
BA_ "SignalType" SG_ 369 APABrkReqProtVal "UNM";
BA_ "SignalLongName" SG_ 369 APABrkReqProtVal "Automatic Park Assist Braking Request Protection Value";
BA_ "VNSigAllNodes" SG_ 369 APABrkReqProtVal 1;
BA_ "GenSigDeltaValue" SG_ 369 APABR_CtrlAcc 10;
BA_ "GenSigSendType" SG_ 369 APABR_CtrlAcc 12;
BA_ "SignalType" SG_ 369 APABR_CtrlAcc "SNM";
BA_ "PacketOrder" SG_ 369 APABR_CtrlAcc 5;
BA_ "SignalLongName" SG_ 369 APABR_CtrlAcc "Automatic Park Assist Braking Request : Control Acceleration";
BA_ "VNSigAllNodes" SG_ 369 APABR_CtrlAcc 1;
BA_ "GenSigSendType" SG_ 369 APABR_AutBrkRmpRt 10;
BA_ "SignalType" SG_ 369 APABR_AutBrkRmpRt "ENM";
BA_ "PacketOrder" SG_ 369 APABR_AutBrkRmpRt 4;
BA_ "SignalLongName" SG_ 369 APABR_AutBrkRmpRt "Automatic Park Assist Braking Request : Automatic Braking Ramp Rate";
BA_ "VNSigAllNodes" SG_ 369 APABR_AutBrkRmpRt 1;
BA_ "GenSigSendType" SG_ 369 APABR_AutBrkRqTyp 10;
BA_ "PacketOrder" SG_ 369 APABR_AutBrkRqTyp 3;
BA_ "SignalType" SG_ 369 APABR_AutBrkRqTyp "ENM";
BA_ "SignalLongName" SG_ 369 APABR_AutBrkRqTyp "Automatic Park Assist Braking Request : Automatic Braking Request Type";
BA_ "VNSigAllNodes" SG_ 369 APABR_AutBrkRqTyp 1;
BA_ "GenSigSendType" SG_ 369 APABR_AutBrkRqd 10;
BA_ "PacketOrder" SG_ 369 APABR_AutBrkRqd 2;
BA_ "SignalType" SG_ 369 APABR_AutBrkRqd "BLN";
BA_ "SignalLongName" SG_ 369 APABR_AutBrkRqd "Automatic Park Assist Braking Request : Automatic Braking Requested";
BA_ "VNSigAllNodes" SG_ 369 APABR_AutBrkRqd 1;
BA_ "GenSigSendType" SG_ 369 APABR_APA2Pstat 10;
BA_ "PacketOrder" SG_ 369 APABR_APA2Pstat 1;
BA_ "SignalType" SG_ 369 APABR_APA2Pstat "ENM";
BA_ "SignalLongName" SG_ 369 APABR_APA2Pstat "Automatic Park Assist Braking Request : APA2P Status";
BA_ "VNSigAllNodes" SG_ 369 APABR_APA2Pstat 1;
BA_ "GenSigDeltaValue" SG_ 369 APABrkReqRC 1;
BA_ "GenSigSendType" SG_ 369 APABrkReqRC 12;
BA_ "SignalType" SG_ 369 APABrkReqRC "UNM";
BA_ "SignalLongName" SG_ 369 APABrkReqRC "Automatic Park Assist Braking Request Rolling Count";
BA_ "VNSigAllNodes" SG_ 369 APABrkReqRC 1;
BA_ "VNSigSLHSSharedDiagnostic" SG_ 2021 DgnInf 1;
BA_ "SignalType" SG_ 2021 DgnInf "UNM";
BA_ "SignalLongName" SG_ 2021 DgnInf "Diagnostic Information";
BA_ "VNSigAllNodes" SG_ 2021 DgnInf 1;
BA_ "SignalType" SG_ 562 AxlTrqMinImTrqCap "UNM";
BA_ "SignalLongName" SG_ 562 AxlTrqMinImTrqCap "Axle Torque Minimum Immediate Torque Capacity";
BA_ "VNSigAllNodes" SG_ 562 AxlTrqMinImTrqCap 1;
BA_ "SignalType" SG_ 562 AxlTrqMaxImTrqCap "UNM";
BA_ "SignalLongName" SG_ 562 AxlTrqMaxImTrqCap "Axle Torque Maximum Immediate Torque Capacity";
BA_ "VNSigAllNodes" SG_ 562 AxlTrqMaxImTrqCap 1;
BA_ "SignalType" SG_ 197 WRSLNDWhlDisTpRC "UNM";
BA_ "PacketOrder" SG_ 197 WRSLNDWhlDisTpRC 1;
BA_ "SignalLongName" SG_ 197 WRSLNDWhlDisTpRC "Wheel Rotational Status Left Non Driven : Wheel Distance Timestamp Rollover Counter";
BA_ "VNSigAllNodes" SG_ 197 WRSLNDWhlDisTpRC 1;
BA_ "SignalType" SG_ 197 WRSLNDWhlRotStRst "BLN";
BA_ "PacketOrder" SG_ 197 WRSLNDWhlRotStRst 3;
BA_ "SignalLongName" SG_ 197 WRSLNDWhlRotStRst "Wheel Rotational Status Left Non Driven : Wheel Rotational Status Reset Occurred";
BA_ "VNSigAllNodes" SG_ 197 WRSLNDWhlRotStRst 1;
BA_ "SignalType" SG_ 197 WRSLNDWhlDistVal "ENM";
BA_ "PacketOrder" SG_ 197 WRSLNDWhlDistVal 4;
BA_ "SignalLongName" SG_ 197 WRSLNDWhlDistVal "Wheel Rotational Status Left Non Driven : Wheel Distance Validity";
BA_ "VNSigAllNodes" SG_ 197 WRSLNDWhlDistVal 1;
BA_ "SignalType" SG_ 197 WRSLNDWhlDistTstm "UNM";
BA_ "PacketOrder" SG_ 197 WRSLNDWhlDistTstm 6;
BA_ "SignalLongName" SG_ 197 WRSLNDWhlDistTstm "Wheel Rotational Status Left Non Driven : Wheel Distance Timestamp";
BA_ "VNSigAllNodes" SG_ 197 WRSLNDWhlDistTstm 1;
BA_ "SignalType" SG_ 197 WRSLNDWhlDistPCntr "UNM";
BA_ "PacketOrder" SG_ 197 WRSLNDWhlDistPCntr 5;
BA_ "SignalLongName" SG_ 197 WRSLNDWhlDistPCntr "Wheel Rotational Status Left Non Driven : Wheel Distance Pulse Counter";
BA_ "VNSigAllNodes" SG_ 197 WRSLNDWhlDistPCntr 1;
BA_ "SignalType" SG_ 197 WRSLNDSeqNum "UNM";
BA_ "PacketOrder" SG_ 197 WRSLNDSeqNum 2;
BA_ "SignalLongName" SG_ 197 WRSLNDSeqNum "Wheel Rotational Status Left Non Driven : Sequence Number";
BA_ "VNSigAllNodes" SG_ 197 WRSLNDSeqNum 1;
BA_ "SignalType" SG_ 197 WRSRNDWhlDisTpRC "UNM";
BA_ "PacketOrder" SG_ 197 WRSRNDWhlDisTpRC 1;
BA_ "SignalLongName" SG_ 197 WRSRNDWhlDisTpRC "Wheel Rotational Status Right Non Driven : Wheel Distance Timestamp Rollover Counter";
BA_ "VNSigAllNodes" SG_ 197 WRSRNDWhlDisTpRC 1;
BA_ "SignalType" SG_ 197 WRSRNDWhlRotStRst "BLN";
BA_ "PacketOrder" SG_ 197 WRSRNDWhlRotStRst 3;
BA_ "SignalLongName" SG_ 197 WRSRNDWhlRotStRst "Wheel Rotational Status Right Non Driven : Wheel Rotational Status Reset Occurred";
BA_ "VNSigAllNodes" SG_ 197 WRSRNDWhlRotStRst 1;
BA_ "SignalType" SG_ 197 WRSRNDWhlDistVal "ENM";
BA_ "PacketOrder" SG_ 197 WRSRNDWhlDistVal 4;
BA_ "SignalLongName" SG_ 197 WRSRNDWhlDistVal "Wheel Rotational Status Right Non Driven : Wheel Distance Validity";
BA_ "VNSigAllNodes" SG_ 197 WRSRNDWhlDistVal 1;
BA_ "SignalType" SG_ 197 WRSRNDWhlDistTstm "UNM";
BA_ "PacketOrder" SG_ 197 WRSRNDWhlDistTstm 6;
BA_ "SignalLongName" SG_ 197 WRSRNDWhlDistTstm "Wheel Rotational Status Right Non Driven : Wheel Distance Timestamp";
BA_ "VNSigAllNodes" SG_ 197 WRSRNDWhlDistTstm 1;
BA_ "SignalType" SG_ 197 WRSRNDWhlDistPCntr "UNM";
BA_ "PacketOrder" SG_ 197 WRSRNDWhlDistPCntr 5;
BA_ "SignalLongName" SG_ 197 WRSRNDWhlDistPCntr "Wheel Rotational Status Right Non Driven : Wheel Distance Pulse Counter";
BA_ "VNSigAllNodes" SG_ 197 WRSRNDWhlDistPCntr 1;
BA_ "SignalType" SG_ 197 WRSRNDSeqNum "UNM";
BA_ "PacketOrder" SG_ 197 WRSRNDSeqNum 2;
BA_ "SignalLongName" SG_ 197 WRSRNDSeqNum "Wheel Rotational Status Right Non Driven : Sequence Number";
BA_ "VNSigAllNodes" SG_ 197 WRSRNDSeqNum 1;
BA_ "GenSigDeltaValue" SG_ 193 WRSLDWhlDisTpRC 1;
BA_ "GenSigSendType" SG_ 193 WRSLDWhlDisTpRC 12;
BA_ "SignalType" SG_ 193 WRSLDWhlDisTpRC "UNM";
BA_ "PacketOrder" SG_ 193 WRSLDWhlDisTpRC 1;
BA_ "SignalLongName" SG_ 193 WRSLDWhlDisTpRC "Wheel Rotational Status Left Driven : Wheel Distance Timestamp Rollover Counter";
BA_ "VNSigAllNodes" SG_ 193 WRSLDWhlDisTpRC 1;
BA_ "GenSigDeltaValue" SG_ 193 WRSLDSeqNum 1;
BA_ "GenSigSendType" SG_ 193 WRSLDSeqNum 12;
BA_ "SignalType" SG_ 193 WRSLDSeqNum "UNM";
BA_ "PacketOrder" SG_ 193 WRSLDSeqNum 2;
BA_ "SignalLongName" SG_ 193 WRSLDSeqNum "Wheel Rotational Status Left Driven : Sequence Number";
BA_ "VNSigAllNodes" SG_ 193 WRSLDSeqNum 1;
BA_ "GenSigSendType" SG_ 193 WRSLDWhlDistVal 10;
BA_ "SignalType" SG_ 193 WRSLDWhlDistVal "ENM";
BA_ "PacketOrder" SG_ 193 WRSLDWhlDistVal 4;
BA_ "SignalLongName" SG_ 193 WRSLDWhlDistVal "Wheel Rotational Status Left Driven : Wheel Distance Validity";
BA_ "VNSigAllNodes" SG_ 193 WRSLDWhlDistVal 1;
BA_ "GenSigSendType" SG_ 193 WRSLDWhlRotStatRst 10;
BA_ "SignalType" SG_ 193 WRSLDWhlRotStatRst "BLN";
BA_ "PacketOrder" SG_ 193 WRSLDWhlRotStatRst 3;
BA_ "SignalLongName" SG_ 193 WRSLDWhlRotStatRst "Wheel Rotational Status Left Driven : Wheel Rotational Status Reset Occurred";
BA_ "VNSigAllNodes" SG_ 193 WRSLDWhlRotStatRst 1;
BA_ "GenSigDeltaValue" SG_ 193 WRSLDWhlDistTmstm 1;
BA_ "GenSigSendType" SG_ 193 WRSLDWhlDistTmstm 12;
BA_ "SignalType" SG_ 193 WRSLDWhlDistTmstm "UNM";
BA_ "PacketOrder" SG_ 193 WRSLDWhlDistTmstm 6;
BA_ "SignalLongName" SG_ 193 WRSLDWhlDistTmstm "Wheel Rotational Status Left Driven : Wheel Distance Timestamp";
BA_ "VNSigAllNodes" SG_ 193 WRSLDWhlDistTmstm 1;
BA_ "GenSigDeltaValue" SG_ 193 WRSLDWhlDistPlsCntr 1;
BA_ "GenSigSendType" SG_ 193 WRSLDWhlDistPlsCntr 12;
BA_ "SignalType" SG_ 193 WRSLDWhlDistPlsCntr "UNM";
BA_ "PacketOrder" SG_ 193 WRSLDWhlDistPlsCntr 5;
BA_ "SignalLongName" SG_ 193 WRSLDWhlDistPlsCntr "Wheel Rotational Status Left Driven : Wheel Distance Pulse Counter";
BA_ "VNSigAllNodes" SG_ 193 WRSLDWhlDistPlsCntr 1;
BA_ "GenSigDeltaValue" SG_ 193 WRSRDWhlDisTpRC 1;
BA_ "GenSigSendType" SG_ 193 WRSRDWhlDisTpRC 12;
BA_ "SignalType" SG_ 193 WRSRDWhlDisTpRC "UNM";
BA_ "PacketOrder" SG_ 193 WRSRDWhlDisTpRC 1;
BA_ "SignalLongName" SG_ 193 WRSRDWhlDisTpRC "Wheel Rotational Status Right Driven : Wheel Distance Timestamp Rollover Counter";
BA_ "VNSigAllNodes" SG_ 193 WRSRDWhlDisTpRC 1;
BA_ "GenSigDeltaValue" SG_ 193 WRSRDSeqNum 1;
BA_ "GenSigSendType" SG_ 193 WRSRDSeqNum 12;
BA_ "SignalType" SG_ 193 WRSRDSeqNum "UNM";
BA_ "PacketOrder" SG_ 193 WRSRDSeqNum 2;
BA_ "SignalLongName" SG_ 193 WRSRDSeqNum "Wheel Rotational Status Right Driven : Sequence Number";
BA_ "VNSigAllNodes" SG_ 193 WRSRDSeqNum 1;
BA_ "GenSigSendType" SG_ 193 WRSRDWhlRotStatRst 10;
BA_ "SignalType" SG_ 193 WRSRDWhlRotStatRst "BLN";
BA_ "PacketOrder" SG_ 193 WRSRDWhlRotStatRst 3;
BA_ "SignalLongName" SG_ 193 WRSRDWhlRotStatRst "Wheel Rotational Status Right Driven : Wheel Rotational Status Reset Occurred";
BA_ "VNSigAllNodes" SG_ 193 WRSRDWhlRotStatRst 1;
BA_ "GenSigSendType" SG_ 193 WRSRDWhlDistVal 10;
BA_ "SignalType" SG_ 193 WRSRDWhlDistVal "ENM";
BA_ "PacketOrder" SG_ 193 WRSRDWhlDistVal 4;
BA_ "SignalLongName" SG_ 193 WRSRDWhlDistVal "Wheel Rotational Status Right Driven : Wheel Distance Validity";
BA_ "VNSigAllNodes" SG_ 193 WRSRDWhlDistVal 1;
BA_ "GenSigDeltaValue" SG_ 193 WRSRDWhlDistTmstm 1;
BA_ "GenSigSendType" SG_ 193 WRSRDWhlDistTmstm 12;
BA_ "SignalType" SG_ 193 WRSRDWhlDistTmstm "UNM";
BA_ "PacketOrder" SG_ 193 WRSRDWhlDistTmstm 6;
BA_ "SignalLongName" SG_ 193 WRSRDWhlDistTmstm "Wheel Rotational Status Right Driven : Wheel Distance Timestamp";
BA_ "VNSigAllNodes" SG_ 193 WRSRDWhlDistTmstm 1;
BA_ "GenSigDeltaValue" SG_ 193 WRSRDWhlDistPlsCntr 1;
BA_ "GenSigSendType" SG_ 193 WRSRDWhlDistPlsCntr 12;
BA_ "SignalType" SG_ 193 WRSRDWhlDistPlsCntr "UNM";
BA_ "PacketOrder" SG_ 193 WRSRDWhlDistPlsCntr 5;
BA_ "SignalLongName" SG_ 193 WRSRDWhlDistPlsCntr "Wheel Rotational Status Right Driven : Wheel Distance Pulse Counter";
BA_ "VNSigAllNodes" SG_ 193 WRSRDWhlDistPlsCntr 1;
BA_ "SignalType" SG_ 823 StrWhlTctlFdbkReqActProtVal "UNM";
BA_ "SignalLongName" SG_ 823 StrWhlTctlFdbkReqActProtVal "Steering Wheel Tactile Feed Back Request Active Protection Value";
BA_ "VNSigAllNodes" SG_ 823 StrWhlTctlFdbkReqActProtVal 1;
BA_ "SignalType" SG_ 823 StrWhlAngReqPrtVal "UNM";
BA_ "SignalLongName" SG_ 823 StrWhlAngReqPrtVal "Steering Wheel Angle Request Protection Value";
BA_ "VNSigAllNodes" SG_ 823 StrWhlAngReqPrtVal 1;
BA_ "SignalType" SG_ 823 StrWhlAngReqARC "UNM";
BA_ "SignalLongName" SG_ 823 StrWhlAngReqARC "Steering Wheel Angle Request Alive Rolling Count";
BA_ "VNSigAllNodes" SG_ 823 StrWhlAngReqARC 1;
BA_ "SignalType" SG_ 823 SWAR_TrgtAng "SNM";
BA_ "PacketOrder" SG_ 823 SWAR_TrgtAng 3;
BA_ "SignalLongName" SG_ 823 SWAR_TrgtAng "Steering Wheel Angle Request : Target Angle";
BA_ "VNSigAllNodes" SG_ 823 SWAR_TrgtAng 1;
BA_ "SignalType" SG_ 823 SWAR_ReqActV "ENM";
BA_ "PacketOrder" SG_ 823 SWAR_ReqActV 2;
BA_ "SignalLongName" SG_ 823 SWAR_ReqActV "Steering Wheel Angle Request : Request Active Validity";
BA_ "VNSigAllNodes" SG_ 823 SWAR_ReqActV 1;
BA_ "SignalType" SG_ 823 SWAR_ReqAct "BLN";
BA_ "PacketOrder" SG_ 823 SWAR_ReqAct 1;
BA_ "SignalLongName" SG_ 823 SWAR_ReqAct "Steering Wheel Angle Request : Request Active";
BA_ "VNSigAllNodes" SG_ 823 SWAR_ReqAct 1;
BA_ "SignalType" SG_ 823 StrWhlTctlFdbkReqActRC "UNM";
BA_ "SignalLongName" SG_ 823 StrWhlTctlFdbkReqActRC "Steering Wheel Tactile Feed Back Request Active Rolling Count";
BA_ "VNSigAllNodes" SG_ 823 StrWhlTctlFdbkReqActRC 1;
BA_ "SignalType" SG_ 823 StrWhlTctlFdbkReqAct "BLN";
BA_ "SignalLongName" SG_ 823 StrWhlTctlFdbkReqAct "Steering Wheel Tactile Feed Back Request Active";
BA_ "VNSigAllNodes" SG_ 823 StrWhlTctlFdbkReqAct 1;
BA_ "SignalType" SG_ 1225 TrnsVDA "ENM";
BA_ "SignalLongName" SG_ 1225 TrnsVDA "Transmission Virtual Device Availability";
BA_ "GenSigStartValue" SG_ 1225 TrnsVDA 1;
BA_ "VNSigAllNodes" SG_ 1225 TrnsVDA 1;
BA_ "SignalType" SG_ 1225 TrnOilTmpV "ENM";
BA_ "SignalLongName" SG_ 1225 TrnOilTmpV "Transmission Oil Temperature Validity";
BA_ "VNSigAllNodes" SG_ 1225 TrnOilTmpV 1;
BA_ "SignalType" SG_ 1225 TransOilTempSensPres "BLN";
BA_ "SignalLongName" SG_ 1225 TransOilTempSensPres "Transmission Oil Temperature Sensor Present";
BA_ "VNSigAllNodes" SG_ 1225 TransOilTempSensPres 1;
BA_ "SignalType" SG_ 1225 TrnOilTmp "UNM";
BA_ "SignalLongName" SG_ 1225 TrnOilTmp "Transmission Oil Temperature";
BA_ "VNSigAllNodes" SG_ 1225 TrnOilTmp 1;
BA_ "SignalType" SG_ 1009 OutAirTempVDA "ENM";
BA_ "SignalLongName" SG_ 1009 OutAirTempVDA "Outside Air Temperature Virtual Device Availability";
BA_ "GenSigStartValue" SG_ 1009 OutAirTempVDA 1;
BA_ "VNSigAllNodes" SG_ 1009 OutAirTempVDA 1;
BA_ "SignalType" SG_ 1009 OtsAirTmpCrValV "ENM";
BA_ "SignalLongName" SG_ 1009 OtsAirTmpCrValV "Outside Air Temperature Corrected Value Validity";
BA_ "VNSigAllNodes" SG_ 1009 OtsAirTmpCrValV 1;
BA_ "SignalType" SG_ 1009 OtsAirTmpCrValMsk "ENM";
BA_ "SignalLongName" SG_ 1009 OtsAirTmpCrValMsk "Outside Air Temperature Corrected Value Mask";
BA_ "VNSigAllNodes" SG_ 1009 OtsAirTmpCrValMsk 1;
BA_ "SignalType" SG_ 1009 OtsAirTmpCrVal "UNM";
BA_ "SignalLongName" SG_ 1009 OtsAirTmpCrVal "Outside Air Temperature Corrected Value";
BA_ "VNSigAllNodes" SG_ 1009 OtsAirTmpCrVal 1;
BA_ "SignalType" SG_ 536 VehOdoV "ENM";
BA_ "SignalLongName" SG_ 536 VehOdoV "Vehicle Odometer Validity";
BA_ "VNSigAllNodes" SG_ 536 VehOdoV 1;
BA_ "SignalType" SG_ 536 VehOdo "UNM";
BA_ "SignalLongName" SG_ 536 VehOdo "Vehicle Odometer";
BA_ "VNSigAllNodes" SG_ 536 VehOdo 1;
BA_ "SignalType" SG_ 1003 DstRolCntAvgNonDrvnV "ENM";
BA_ "SignalLongName" SG_ 1003 DstRolCntAvgNonDrvnV "Distance Rolling Count Average Non Driven Validity";
BA_ "VNSigAllNodes" SG_ 1003 DstRolCntAvgNonDrvnV 1;
BA_ "SignalType" SG_ 1003 DstRolCntAvNDrRstOc "BLN";
BA_ "SignalLongName" SG_ 1003 DstRolCntAvNDrRstOc "Distance Rolling Count Average Non Driven Reset Occurred";
BA_ "VNSigAllNodes" SG_ 1003 DstRolCntAvNDrRstOc 1;
BA_ "SignalType" SG_ 1003 DstRolCntAvgNonDrvn "UNM";
BA_ "SignalLongName" SG_ 1003 DstRolCntAvgNonDrvn "Distance Rolling Count Average Non Driven";
BA_ "VNSigAllNodes" SG_ 1003 DstRolCntAvgNonDrvn 1;
BA_ "SignalType" SG_ 1003 DistRollCntAvgDrvnV "ENM";
BA_ "SignalLongName" SG_ 1003 DistRollCntAvgDrvnV "Distance Rolling Count Average Driven Validity";
BA_ "VNSigAllNodes" SG_ 1003 DistRollCntAvgDrvnV 1;
BA_ "SignalType" SG_ 1003 DistRollCntAvgDrvnSrc "ENM";
BA_ "SignalLongName" SG_ 1003 DistRollCntAvgDrvnSrc "Distance Rolling Count Average Driven Source";
BA_ "VNSigAllNodes" SG_ 1003 DistRollCntAvgDrvnSrc 1;
BA_ "SignalType" SG_ 1003 DstRolCntAvgDrnRstOc "BLN";
BA_ "SignalLongName" SG_ 1003 DstRolCntAvgDrnRstOc "Distance Rolling Count Average Driven Reset Occurred";
BA_ "VNSigAllNodes" SG_ 1003 DstRolCntAvgDrnRstOc 1;
BA_ "SignalType" SG_ 1003 DistRollCntAvgDrvnM "ENM";
BA_ "SignalLongName" SG_ 1003 DistRollCntAvgDrvnM "Distance Rolling Count Average Driven Mask";
BA_ "VNSigAllNodes" SG_ 1003 DistRollCntAvgDrvnM 1;
BA_ "SignalType" SG_ 1003 DistRollCntAvgDrvn "UNM";
BA_ "SignalLongName" SG_ 1003 DistRollCntAvgDrvn "Distance Rolling Count Average Driven";
BA_ "VNSigAllNodes" SG_ 1003 DistRollCntAvgDrvn 1;
BA_ "SignalType" SG_ 1001 VehSpdAvgNDrvnV "ENM";
BA_ "SignalLongName" SG_ 1001 VehSpdAvgNDrvnV "Vehicle Speed Average Non Driven Validity";
BA_ "VNSigAllNodes" SG_ 1001 VehSpdAvgNDrvnV 1;
BA_ "SignalType" SG_ 1001 VehSpdAvgNDrvn "UNM";
BA_ "SignalLongName" SG_ 1001 VehSpdAvgNDrvn "Vehicle Speed Average Non Driven";
BA_ "VNSigAllNodes" SG_ 1001 VehSpdAvgNDrvn 1;
BA_ "SignalType" SG_ 1001 VehSpdAvgDrvnV "ENM";
BA_ "SignalLongName" SG_ 1001 VehSpdAvgDrvnV "Vehicle Speed Average Driven Validity";
BA_ "VNSigAllNodes" SG_ 1001 VehSpdAvgDrvnV 1;
BA_ "SignalType" SG_ 1001 VehSpdAvgDrvnSrc "ENM";
BA_ "SignalLongName" SG_ 1001 VehSpdAvgDrvnSrc "Vehicle Speed Average Driven Source";
BA_ "VNSigAllNodes" SG_ 1001 VehSpdAvgDrvnSrc 1;
BA_ "SignalType" SG_ 1001 VehSpdAvgDrvn "UNM";
BA_ "SignalLongName" SG_ 1001 VehSpdAvgDrvn "Vehicle Speed Average Driven";
BA_ "VNSigAllNodes" SG_ 1001 VehSpdAvgDrvn 1;
BA_ "SignalType" SG_ 298 CrshAlrtStPrsnt "BLN";
BA_ "SignalLongName" SG_ 298 CrshAlrtStPrsnt "Crash Alert Seat Present";
BA_ "VNSigAllNodes" SG_ 298 CrshAlrtStPrsnt 1;
BA_ "SignalType" SG_ 298 StBltTgtCSRq "ENM";
BA_ "SignalLongName" SG_ 298 StBltTgtCSRq "Seat Belt Tightening Customize Setting Request";
BA_ "VNSigAllNodes" SG_ 298 StBltTgtCSRq 1;
BA_ "SignalType" SG_ 298 PsSbltAtcV "ENM";
BA_ "SignalLongName" SG_ 298 PsSbltAtcV "Passenger Seatbelt Attached Validity";
BA_ "VNSigAllNodes" SG_ 298 PsSbltAtcV 1;
BA_ "SignalType" SG_ 298 PsSbltAtc "BLN";
BA_ "SignalLongName" SG_ 298 PsSbltAtc "Passenger Seatbelt Attached";
BA_ "VNSigAllNodes" SG_ 298 PsSbltAtc 1;
BA_ "SignalType" SG_ 298 DrSbltAtcV "ENM";
BA_ "SignalLongName" SG_ 298 DrSbltAtcV "Driver Seatbelt Attached Validity";
BA_ "VNSigAllNodes" SG_ 298 DrSbltAtcV 1;
BA_ "SignalType" SG_ 298 DrSbltAtc "BLN";
BA_ "SignalLongName" SG_ 298 DrSbltAtc "Driver Seatbelt Attached";
BA_ "VNSigAllNodes" SG_ 298 DrSbltAtc 1;
BA_ "SignalType" SG_ 298 CrshAlrtDrvrSlctdType "ENM";
BA_ "SignalLongName" SG_ 298 CrshAlrtDrvrSlctdType "Crash Alert Driver Selected Type";
BA_ "VNSigAllNodes" SG_ 298 CrshAlrtDrvrSlctdType 1;
BA_ "SignalType" SG_ 789 ACCBrkSysCmmndExtRC "UNM";
BA_ "SignalLongName" SG_ 789 ACCBrkSysCmmndExtRC "Adaptive Cruise Control Brake System Command Extended Rolling Count";
BA_ "VNSigAllNodes" SG_ 789 ACCBrkSysCmmndExtRC 1;
BA_ "SignalType" SG_ 789 ACCBrkSysCmmndExtProtVal "UNM";
BA_ "SignalLongName" SG_ 789 ACCBrkSysCmmndExtProtVal "Adaptive Cruise Control Brake System Command Extended Protection Value";
BA_ "VNSigAllNodes" SG_ 789 ACCBrkSysCmmndExtProtVal 1;
BA_ "SignalType" SG_ 789 ACCBSCE_AutBrkTp "ENM";
BA_ "PacketOrder" SG_ 789 ACCBSCE_AutBrkTp 2;
BA_ "SignalLongName" SG_ 789 ACCBSCE_AutBrkTp "Adaptive Cruise Control Brake System Command Extended : Automatic Braking Type";
BA_ "VNSigAllNodes" SG_ 789 ACCBSCE_AutBrkTp 1;
BA_ "SignalType" SG_ 789 ACCBSCE_ACCAct "BLN";
BA_ "PacketOrder" SG_ 789 ACCBSCE_ACCAct 1;
BA_ "SignalLongName" SG_ 789 ACCBSCE_ACCAct "Adaptive Cruise Control Brake System Command Extended : Adaptive Cruise Control Active";
BA_ "VNSigAllNodes" SG_ 789 ACCBSCE_ACCAct 1;
BA_ "SignalType" SG_ 789 ACCBSCE_ACCAccl "SNM";
BA_ "PacketOrder" SG_ 789 ACCBSCE_ACCAccl 3;
BA_ "SignalLongName" SG_ 789 ACCBSCE_ACCAccl "Adaptive Cruise Control Brake System Command Extended : Adaptive Cruise Control Acceleration";
BA_ "VNSigAllNodes" SG_ 789 ACCBSCE_ACCAccl 1;
BA_ "SignalType" SG_ 800 ColPrSysFwdLkngBrkAstSReqTyp "ENM";
BA_ "SignalLongName" SG_ 800 ColPrSysFwdLkngBrkAstSReqTyp "Collision Preparation System Forward Looking Brake Assist Setting Request Type";
BA_ "VNSigAllNodes" SG_ 800 ColPrSysFwdLkngBrkAstSReqTyp 1;
BA_ "SignalType" SG_ 800 ColPrSysMinStopReqActV "ENM";
BA_ "SignalLongName" SG_ 800 ColPrSysMinStopReqActV "Collision Preparation System Minimum Stop Request Active Validity";
BA_ "VNSigAllNodes" SG_ 800 ColPrSysMinStopReqActV 1;
BA_ "SignalType" SG_ 800 ColPrSysMinStopReqAct "BLN";
BA_ "SignalLongName" SG_ 800 ColPrSysMinStopReqAct "Collision Preparation System Minimum Stop Request Active";
BA_ "VNSigAllNodes" SG_ 800 ColPrSysMinStopReqAct 1;
BA_ "SignalType" SG_ 800 CPSCBSC_CtrlAcc "SNM";
BA_ "PacketOrder" SG_ 800 CPSCBSC_CtrlAcc 3;
BA_ "SignalLongName" SG_ 800 CPSCBSC_CtrlAcc "Collision Preparation System Control Brake System Command : Control Acceleration";
BA_ "VNSigAllNodes" SG_ 800 CPSCBSC_CtrlAcc 1;
BA_ "SignalType" SG_ 800 CPSCBSC_AutoBrkReq "BLN";
BA_ "PacketOrder" SG_ 800 CPSCBSC_AutoBrkReq 1;
BA_ "SignalLongName" SG_ 800 CPSCBSC_AutoBrkReq "Collision Preparation System Control Brake System Command : Automatic Braking Requested";
BA_ "VNSigAllNodes" SG_ 800 CPSCBSC_AutoBrkReq 1;
BA_ "SignalType" SG_ 800 CPSCBSC_AutoBrkReqTyp "ENM";
BA_ "PacketOrder" SG_ 800 CPSCBSC_AutoBrkReqTyp 2;
BA_ "SignalLongName" SG_ 800 CPSCBSC_AutoBrkReqTyp "Collision Preparation System Control Brake System Command : Automatic Braking Request Type";
BA_ "VNSigAllNodes" SG_ 800 CPSCBSC_AutoBrkReqTyp 1;
BA_ "SignalType" SG_ 800 ColPrSysBrkPrfReq "BLN";
BA_ "SignalLongName" SG_ 800 ColPrSysBrkPrfReq "Collision Preparation System Brake Prefill Request";
BA_ "VNSigAllNodes" SG_ 800 ColPrSysBrkPrfReq 1;
BA_ "SignalType" SG_ 800 ColPrSysCtrlBrkSysCmdRC "UNM";
BA_ "SignalLongName" SG_ 800 ColPrSysCtrlBrkSysCmdRC "Collision Preparation System Control Brake System Command Rolling Count";
BA_ "VNSigAllNodes" SG_ 800 ColPrSysCtrlBrkSysCmdRC 1;
BA_ "SignalType" SG_ 800 ColPrSysCtrlBrkSysCmdProtVal "UNM";
BA_ "SignalLongName" SG_ 800 ColPrSysCtrlBrkSysCmdProtVal "Collision Preparation System Control Brake System Command Protection Value";
BA_ "VNSigAllNodes" SG_ 800 ColPrSysCtrlBrkSysCmdProtVal 1;
BA_ "SignalType" SG_ 465 RrAxlCtrlMod "ENM";
BA_ "SignalLongName" SG_ 465 RrAxlCtrlMod "Rear Axle Control Mode";
BA_ "VNSigAllNodes" SG_ 465 RrAxlCtrlMod 1;
BA_ "SignalType" SG_ 465 RAMDVLReqVal "UNM";
BA_ "PacketOrder" SG_ 465 RAMDVLReqVal 2;
BA_ "SignalLongName" SG_ 465 RAMDVLReqVal "Rear Axle Maximum Differential Velocity Limit : Request Value";
BA_ "VNSigAllNodes" SG_ 465 RAMDVLReqVal 1;
BA_ "SignalType" SG_ 465 RAMDVLAtv "BLN";
BA_ "PacketOrder" SG_ 465 RAMDVLAtv 1;
BA_ "SignalLongName" SG_ 465 RAMDVLAtv "Rear Axle Maximum Differential Velocity Limit : Active";
BA_ "VNSigAllNodes" SG_ 465 RAMDVLAtv 1;
BA_ "SignalType" SG_ 465 RrAxlOpeMod "ENM";
BA_ "SignalLongName" SG_ 465 RrAxlOpeMod "Rear Axle Operational Mode";
BA_ "VNSigAllNodes" SG_ 465 RrAxlOpeMod 1;
BA_ "SignalType" SG_ 465 RrAxlEstTrqV "ENM";
BA_ "SignalLongName" SG_ 465 RrAxlEstTrqV "Rear Axle Estimated Torque Validity";
BA_ "VNSigAllNodes" SG_ 465 RrAxlEstTrqV 1;
BA_ "SignalType" SG_ 465 RrAxlEstTrq "SNM";
BA_ "SignalLongName" SG_ 465 RrAxlEstTrq "Rear Axle Estimated Torque";
BA_ "VNSigAllNodes" SG_ 465 RrAxlEstTrq 1;
BA_ "SignalType" SG_ 465 RrAxlStat "ENM";
BA_ "SignalLongName" SG_ 465 RrAxlStat "Rear Axle Status";
BA_ "VNSigAllNodes" SG_ 465 RrAxlStat 1;
BA_ "SignalType" SG_ 460 SecAxlThrmlCapV "ENM";
BA_ "SignalLongName" SG_ 460 SecAxlThrmlCapV "Secondary Axle Thermal Capacity Validity";
BA_ "VNSigAllNodes" SG_ 460 SecAxlThrmlCapV 1;
BA_ "SignalType" SG_ 460 SecAxlThrmlCapPRqAt "BLN";
BA_ "SignalLongName" SG_ 460 SecAxlThrmlCapPRqAt "Secondary Axle Thermal Capacity Protection Request Active";
BA_ "VNSigAllNodes" SG_ 460 SecAxlThrmlCapPRqAt 1;
BA_ "SignalType" SG_ 460 SecAxlThrmlCap "UNM";
BA_ "SignalLongName" SG_ 460 SecAxlThrmlCap "Secondary Axle Thermal Capacity";
BA_ "VNSigAllNodes" SG_ 460 SecAxlThrmlCap 1;
BA_ "SignalType" SG_ 460 SecAxlStat "ENM";
BA_ "SignalLongName" SG_ 460 SecAxlStat "Secondary Axle Status";
BA_ "VNSigAllNodes" SG_ 460 SecAxlStat 1;
BA_ "SignalType" SG_ 460 SecAxlEstTrqV "ENM";
BA_ "SignalLongName" SG_ 460 SecAxlEstTrqV "Secondary Axle Estimated Torque Validity";
BA_ "VNSigAllNodes" SG_ 460 SecAxlEstTrqV 1;
BA_ "SignalType" SG_ 460 SecAxlEstTrq "UNM";
BA_ "SignalLongName" SG_ 460 SecAxlEstTrq "Secondary Axle Estimated Torque";
BA_ "VNSigAllNodes" SG_ 460 SecAxlEstTrq 1;
BA_ "SignalType" SG_ 460 SecAxlCtrlMod "ENM";
BA_ "SignalLongName" SG_ 460 SecAxlCtrlMod "Secondary Axle Control Mode";
BA_ "VNSigAllNodes" SG_ 460 SecAxlCtrlMod 1;
BA_ "SignalType" SG_ 460 SAMDVLReqVal "UNM";
BA_ "PacketOrder" SG_ 460 SAMDVLReqVal 2;
BA_ "SignalLongName" SG_ 460 SAMDVLReqVal "Secondary Axle Maximum Differential Velocity Limit : Request Value";
BA_ "VNSigAllNodes" SG_ 460 SAMDVLReqVal 1;
BA_ "SignalType" SG_ 460 SAMDVLAtv "BLN";
BA_ "PacketOrder" SG_ 460 SAMDVLAtv 1;
BA_ "SignalLongName" SG_ 460 SAMDVLAtv "Secondary Axle Maximum Differential Velocity Limit : Active";
BA_ "VNSigAllNodes" SG_ 460 SAMDVLAtv 1;
BA_ "SignalType" SG_ 560 RegenBrkAxTqAchPVal "UNM";
BA_ "SignalLongName" SG_ 560 RegenBrkAxTqAchPVal "Regenerative Braking Axle Torque Achieved Protection Value";
BA_ "VNSigAllNodes" SG_ 560 RegenBrkAxTqAchPVal 1;
BA_ "SignalType" SG_ 560 RegenBrkAxTqAchARC "UNM";
BA_ "SignalLongName" SG_ 560 RegenBrkAxTqAchARC "Regenerative Braking Axle Torque Achieved Alive Rolling Count";
BA_ "VNSigAllNodes" SG_ 560 RegenBrkAxTqAchARC 1;
BA_ "SignalType" SG_ 560 RegenBrkAxTrqAch "UNM";
BA_ "SignalLongName" SG_ 560 RegenBrkAxTrqAch "Regenerative Braking Axle Torque Achieved";
BA_ "VNSigAllNodes" SG_ 560 RegenBrkAxTrqAch 1;
BA_ "SignalType" SG_ 560 RegenBrkAxTorqCap "UNM";
BA_ "SignalLongName" SG_ 560 RegenBrkAxTorqCap "Regenerative Braking Axle Torque Capability";
BA_ "VNSigAllNodes" SG_ 560 RegenBrkAxTorqCap 1;
BA_ "SignalType" SG_ 565 BrkPdlDrvApplPresV "ENM";
BA_ "SignalLongName" SG_ 565 BrkPdlDrvApplPresV "Brake Pedal Driver Applied Pressure Validity";
BA_ "VNSigAllNodes" SG_ 565 BrkPdlDrvApplPresV 1;
BA_ "SignalType" SG_ 565 ChsSysTrnsShfBhvRq "ENM";
BA_ "SignalLongName" SG_ 565 ChsSysTrnsShfBhvRq "Chassis System Transmission Shift Behavior Request";
BA_ "VNSigAllNodes" SG_ 565 ChsSysTrnsShfBhvRq 1;
BA_ "SignalType" SG_ 565 BrkPdlDrvApplPres "UNM";
BA_ "SignalLongName" SG_ 565 BrkPdlDrvApplPres "Brake Pedal Driver Applied Pressure";
BA_ "VNSigAllNodes" SG_ 565 BrkPdlDrvApplPres 1;
BA_ "SignalType" SG_ 565 RegenBrkAxTrqRqPVal "UNM";
BA_ "SignalLongName" SG_ 565 RegenBrkAxTrqRqPVal "Regenerative Braking Axle Torque Request Protection Value";
BA_ "VNSigAllNodes" SG_ 565 RegenBrkAxTrqRqPVal 1;
BA_ "SignalType" SG_ 565 RegenBrkAxTrqRqARC "UNM";
BA_ "SignalLongName" SG_ 565 RegenBrkAxTrqRqARC "Regenerative Braking Axle Torque Request Alive Rolling Count";
BA_ "VNSigAllNodes" SG_ 565 RegenBrkAxTrqRqARC 1;
BA_ "SignalType" SG_ 565 RegenBrkAxTorqRqst "UNM";
BA_ "SignalLongName" SG_ 565 RegenBrkAxTorqRqst "Regenerative Braking Axle Torque Request";
BA_ "VNSigAllNodes" SG_ 565 RegenBrkAxTorqRqst 1;
BA_ "SignalType" SG_ 866 CPSInfotmntMtReq "ENM";
BA_ "SignalLongName" SG_ 866 CPSInfotmntMtReq "Collision Preparation System Infotainment Mute Request";
BA_ "VNSigAllNodes" SG_ 866 CPSInfotmntMtReq 1;
BA_ "SignalType" SG_ 866 StBltTgtSetAvl "BLN";
BA_ "SignalLongName" SG_ 866 StBltTgtSetAvl "Seat Belt Tightening Settings Available";
BA_ "VNSigAllNodes" SG_ 866 StBltTgtSetAvl 1;
BA_ "SignalType" SG_ 866 StBltTgtCrtSetVal "ENM";
BA_ "SignalLongName" SG_ 866 StBltTgtCrtSetVal "Seat Belt Tightening Current Setting Value";
BA_ "VNSigAllNodes" SG_ 866 StBltTgtCrtSetVal 1;
BA_ "SignalType" SG_ 866 MotStBltUnblIO "BLN";
BA_ "SignalLongName" SG_ 866 MotStBltUnblIO "Motorized Seat Belt Unavailable Indication On";
BA_ "VNSigAllNodes" SG_ 866 MotStBltUnblIO 1;
BA_ "SignalType" SG_ 866 MotStBltFldIO "BLN";
BA_ "SignalLongName" SG_ 866 MotStBltFldIO "Motorized Seat Belt Failed Indication On";
BA_ "VNSigAllNodes" SG_ 866 MotStBltFldIO 1;
BA_ "SignalType" SG_ 866 ColPrSysWndwsReq "ENM";
BA_ "SignalLongName" SG_ 866 ColPrSysWndwsReq "Collision Preparation System Windows Request";
BA_ "VNSigAllNodes" SG_ 866 ColPrSysWndwsReq 1;
BA_ "SignalType" SG_ 866 ColPrSysSnrfReq "ENM";
BA_ "SignalLongName" SG_ 866 ColPrSysSnrfReq "Collision Preparation System Sunroof Request";
BA_ "VNSigAllNodes" SG_ 866 ColPrSysSnrfReq 1;
BA_ "SignalType" SG_ 866 ColPrSysHzrdLghtsReq "ENM";
BA_ "SignalLongName" SG_ 866 ColPrSysHzrdLghtsReq "Collision Preparation System Hazard Lights Request";
BA_ "VNSigAllNodes" SG_ 866 ColPrSysHzrdLghtsReq 1;
BA_ "SignalType" SG_ 866 ColPrSysDrsReq "ENM";
BA_ "SignalLongName" SG_ 866 ColPrSysDrsReq "Collision Preparation System Doors Request";
BA_ "VNSigAllNodes" SG_ 866 ColPrSysDrsReq 1;
BA_ "SignalType" SG_ 801 RnDgCPSCtrlBrkSysCmdRC "UNM";
BA_ "SignalLongName" SG_ 801 RnDgCPSCtrlBrkSysCmdRC "Rationality Diagnostic Collision Preparation System Braking System Command Rolling Count";
BA_ "VNSigAllNodes" SG_ 801 RnDgCPSCtrlBrkSysCmdRC 1;
BA_ "SignalType" SG_ 801 RnDgCPSCtrlBrkSysCmdPrVal "UNM";
BA_ "SignalLongName" SG_ 801 RnDgCPSCtrlBrkSysCmdPrVal "Rationality Diagnostic Collision Preparation System Braking System Command Protection Value";
BA_ "VNSigAllNodes" SG_ 801 RnDgCPSCtrlBrkSysCmdPrVal 1;
BA_ "SignalType" SG_ 801 RDCPSCBSC_CtrlAcc "SNM";
BA_ "PacketOrder" SG_ 801 RDCPSCBSC_CtrlAcc 3;
BA_ "SignalLongName" SG_ 801 RDCPSCBSC_CtrlAcc "Rationality Diagnostic Collision Preparation System Braking System Command : Control Acceleration";
BA_ "VNSigAllNodes" SG_ 801 RDCPSCBSC_CtrlAcc 1;
BA_ "SignalType" SG_ 801 RDCPSCBSC_AutoBrkReq "ENM";
BA_ "PacketOrder" SG_ 801 RDCPSCBSC_AutoBrkReq 2;
BA_ "SignalLongName" SG_ 801 RDCPSCBSC_AutoBrkReq "Rationality Diagnostic Collision Preparation System Braking System Command : Automatic Braking Requested";
BA_ "VNSigAllNodes" SG_ 801 RDCPSCBSC_AutoBrkReq 1;
BA_ "SignalType" SG_ 801 RDCPSCBSC_AutoBrkReqTyp "ENM";
BA_ "PacketOrder" SG_ 801 RDCPSCBSC_AutoBrkReqTyp 1;
BA_ "SignalLongName" SG_ 801 RDCPSCBSC_AutoBrkReqTyp "Rationality Diagnostic Collision Preparation System Braking System Command : Automatic Braking Request Type";
BA_ "VNSigAllNodes" SG_ 801 RDCPSCBSC_AutoBrkReqTyp 1;
BA_ "SignalType" SG_ 821 ElcPwrStrAvalStatPVal "UNM";
BA_ "SignalLongName" SG_ 821 ElcPwrStrAvalStatPVal "Electrical Power Steering Availability Status Protection Value";
BA_ "VNSigAllNodes" SG_ 821 ElcPwrStrAvalStatPVal 1;
BA_ "SignalType" SG_ 821 ElcPwrStrAvalStatARC "UNM";
BA_ "SignalLongName" SG_ 821 ElcPwrStrAvalStatARC "Electrical Power Steering Availability Status Alive Rolling Count";
BA_ "VNSigAllNodes" SG_ 821 ElcPwrStrAvalStatARC 1;
BA_ "SignalType" SG_ 821 DrvStrIntfrDetARC "UNM";
BA_ "SignalLongName" SG_ 821 DrvStrIntfrDetARC "Driver Steering Interference Detected Alive Rolling Count";
BA_ "VNSigAllNodes" SG_ 821 DrvStrIntfrDetARC 1;
BA_ "SignalType" SG_ 821 DrvStrIntfrDetPrtVal "UNM";
BA_ "SignalLongName" SG_ 821 DrvStrIntfrDetPrtVal "Driver Steering Interference Detected Protection Value";
BA_ "VNSigAllNodes" SG_ 821 DrvStrIntfrDetPrtVal 1;
BA_ "SignalType" SG_ 821 ElecPwrStrAvalStat "ENM";
BA_ "SignalLongName" SG_ 821 ElecPwrStrAvalStat "Electrical Power Steering Availability Status";
BA_ "VNSigAllNodes" SG_ 821 ElecPwrStrAvalStat 1;
BA_ "SignalType" SG_ 821 DrvStrIntfrDtcdV "ENM";
BA_ "SignalLongName" SG_ 821 DrvStrIntfrDtcdV "Driver Steering Intereference Detected Validity";
BA_ "VNSigAllNodes" SG_ 821 DrvStrIntfrDtcdV 1;
BA_ "SignalType" SG_ 821 DrvStrIntfrDtcd "BLN";
BA_ "SignalLongName" SG_ 821 DrvStrIntfrDtcd "Driver Steering Intereference Detected";
BA_ "VNSigAllNodes" SG_ 821 DrvStrIntfrDtcd 1;
BA_ "SignalType" SG_ 564 RrAxLckTrqRqCplRqTp "ENM";
BA_ "SignalLongName" SG_ 564 RrAxLckTrqRqCplRqTp "Rear Axle Locking Torque Request Coupling Request Type";
BA_ "VNSigAllNodes" SG_ 564 RrAxLckTrqRqCplRqTp 1;
BA_ "SignalType" SG_ 564 RrAxLkTqRqCplRqTRC "UNM";
BA_ "SignalLongName" SG_ 564 RrAxLkTqRqCplRqTRC "Rear Axle Locking Torque Request Coupling Request Type Rolling Count";
BA_ "VNSigAllNodes" SG_ 564 RrAxLkTqRqCplRqTRC 1;
BA_ "SignalType" SG_ 564 RrAxLkTqRqCplRqTPVl "UNM";
BA_ "SignalLongName" SG_ 564 RrAxLkTqRqCplRqTPVl "Rear Axle Locking Torque Request Coupling Request Type Protection Value";
BA_ "VNSigAllNodes" SG_ 564 RrAxLkTqRqCplRqTPVl 1;
BA_ "SignalType" SG_ 564 RrAxlLockTrqReqRC "UNM";
BA_ "SignalLongName" SG_ 564 RrAxlLockTrqReqRC "Rear Axle Locking Torque Request Rolling Count";
BA_ "VNSigAllNodes" SG_ 564 RrAxlLockTrqReqRC 1;
BA_ "SignalType" SG_ 564 RALTRCoplReqVal "UNM";
BA_ "PacketOrder" SG_ 564 RALTRCoplReqVal 2;
BA_ "SignalLongName" SG_ 564 RALTRCoplReqVal "Rear Axle Locking Torque Request : Coupling Request Value";
BA_ "VNSigAllNodes" SG_ 564 RALTRCoplReqVal 1;
BA_ "SignalType" SG_ 564 RALTRCplReqAtv "BLN";
BA_ "PacketOrder" SG_ 564 RALTRCplReqAtv 1;
BA_ "SignalLongName" SG_ 564 RALTRCplReqAtv "Rear Axle Locking Torque Request : Coupling Request Active";
BA_ "VNSigAllNodes" SG_ 564 RALTRCplReqAtv 1;
BA_ "SignalType" SG_ 564 RrAxlLockTrqReqVal "UNM";
BA_ "SignalLongName" SG_ 564 RrAxlLockTrqReqVal "Rear Axle Locking Torque Request Protection Value";
BA_ "VNSigAllNodes" SG_ 564 RrAxlLockTrqReqVal 1;
BA_ "VNSigSLHSSharedDiagnostic" SG_ 2015 DgnInf 1;
BA_ "SignalType" SG_ 2015 DgnInf "UNM";
BA_ "SignalLongName" SG_ 2015 DgnInf "Diagnostic Information";
BA_ "VNSigAllNodes" SG_ 2015 DgnInf 1;
BA_ "VNSigSLHSSharedDiagnostic" SG_ 2025 DgnInf 1;
BA_ "SignalType" SG_ 2025 DgnInf "UNM";
BA_ "SignalLongName" SG_ 2025 DgnInf "Diagnostic Information";
BA_ "VNSigAllNodes" SG_ 2025 DgnInf 1;
BA_ "VNSigSLHSSharedDiagnostic" SG_ 1513 DgnInf 1;
BA_ "SignalType" SG_ 1513 DgnInf "UNM";
BA_ "SignalLongName" SG_ 1513 DgnInf "Diagnostic Information";
BA_ "VNSigAllNodes" SG_ 1513 DgnInf 1;
BA_ "VNSigSLHSSharedDiagnostic" SG_ 2017 DgnInf 1;
BA_ "SignalType" SG_ 2017 DgnInf "UNM";
BA_ "SignalLongName" SG_ 2017 DgnInf "Diagnostic Information";
BA_ "VNSigAllNodes" SG_ 2017 DgnInf 1;
BA_ "SignalType" SG_ 832 BrkPedTrvlAchvd "BLN";
BA_ "PacketOrder" SG_ 832 BrkPedTrvlAchvd 1;
BA_ "SignalLongName" SG_ 832 BrkPedTrvlAchvd "Brake Pedal Initial Travel Achieved Status : Brake Pedal Initial Travel Achieved";
BA_ "VNSigAllNodes" SG_ 832 BrkPedTrvlAchvd 1;
BA_ "SignalType" SG_ 832 BrkPedTrvlAchvdV "ENM";
BA_ "PacketOrder" SG_ 832 BrkPedTrvlAchvdV 2;
BA_ "SignalLongName" SG_ 832 BrkPedTrvlAchvdV "Brake Pedal Initial Travel Achieved Status : Brake Pedal Initial Travel Achieved Validity";
BA_ "VNSigAllNodes" SG_ 832 BrkPedTrvlAchvdV 1;
BA_ "SignalType" SG_ 832 BrkPdlInTrvPrt "UNM";
BA_ "SignalLongName" SG_ 832 BrkPdlInTrvPrt "Brake Pedal Initial Travel Achieved Protection";
BA_ "VNSigAllNodes" SG_ 832 BrkPdlInTrvPrt 1;
BA_ "SignalType" SG_ 832 AccActPosV "ENM";
BA_ "SignalLongName" SG_ 832 AccActPosV "Accelerator Actual Position Validity";
BA_ "VNSigAllNodes" SG_ 832 AccActPosV 1;
BA_ "SignalType" SG_ 832 AccActPos "UNM";
BA_ "SignalLongName" SG_ 832 AccActPos "Accelerator Actual Position";
BA_ "VNSigAllNodes" SG_ 832 AccActPos 1;
BA_ "SignalType" SG_ 832 WhlDistPrRevNDrvn "UNM";
BA_ "SignalLongName" SG_ 832 WhlDistPrRevNDrvn "Wheel Distance Per Revolution Non Driven";
BA_ "VNSigAllNodes" SG_ 832 WhlDistPrRevNDrvn 1;
BA_ "SignalType" SG_ 832 WhlDistPrRevDrvn "UNM";
BA_ "SignalLongName" SG_ 832 WhlDistPrRevDrvn "Wheel Distance Per Revolution Driven";
BA_ "VNSigAllNodes" SG_ 832 WhlDistPrRevDrvn 1;
BA_ "SignalType" SG_ 462 SecAxlLkTqRqCplRqTp "ENM";
BA_ "SignalLongName" SG_ 462 SecAxlLkTqRqCplRqTp "Secondary Axle Locking Torque Request Coupling Request Type";
BA_ "VNSigAllNodes" SG_ 462 SecAxlLkTqRqCplRqTp 1;
BA_ "SignalType" SG_ 462 SecAxlTrqReqProtVal "UNM";
BA_ "SignalLongName" SG_ 462 SecAxlTrqReqProtVal "Secondary Axle Torque Request Protection Value";
BA_ "VNSigAllNodes" SG_ 462 SecAxlTrqReqProtVal 1;
BA_ "SignalType" SG_ 462 SecAxlTrqReqARollCnt "UNM";
BA_ "SignalLongName" SG_ 462 SecAxlTrqReqARollCnt "Secondary Axle Torque Request Alive Rolling Count";
BA_ "VNSigAllNodes" SG_ 462 SecAxlTrqReqARollCnt 1;
BA_ "SignalType" SG_ 462 SATRCplReqVal "UNM";
BA_ "PacketOrder" SG_ 462 SATRCplReqVal 2;
BA_ "SignalLongName" SG_ 462 SATRCplReqVal "Secondary Axle Torque Request : Coupling Request Value";
BA_ "VNSigAllNodes" SG_ 462 SATRCplReqVal 1;
BA_ "SignalType" SG_ 462 SATRCplReqAtv "BLN";
BA_ "PacketOrder" SG_ 462 SATRCplReqAtv 1;
BA_ "SignalLongName" SG_ 462 SATRCplReqAtv "Secondary Axle Torque Request : Coupling Request Active";
BA_ "VNSigAllNodes" SG_ 462 SATRCplReqAtv 1;
BA_REL_ "GenSigSuprvResp" BU_SG_REL_ EBCM_OBD_CE SG_ 532 AutEBrkAstPctPshRdPos 1;
BA_REL_ "GenSigTimeoutMsg" BU_SG_REL_ EBCM_OBD_CE SG_ 532 AutEBrkAstPctPshRdPos 532;
BA_REL_ "GenSigTimeoutTime" BU_SG_REL_ EBCM_OBD_CE SG_ 532 AutEBrkAstPctPshRdPos 250;
BA_REL_ "GenSigSuprvResp" BU_SG_REL_ EBCM_CE SG_ 532 AutEBrkAstPctPshRdPos 1;
BA_REL_ "GenSigTimeoutMsg" BU_SG_REL_ EBCM_CE SG_ 532 AutEBrkAstPctPshRdPos 532;
BA_REL_ "GenSigTimeoutTime" BU_SG_REL_ EBCM_CE SG_ 532 AutEBrkAstPctPshRdPos 250;
BA_REL_ "GenSigSuprvResp" BU_SG_REL_ EBCM_OBD_CE SG_ 532 EBrkAstOtptRdPosStat 1;
BA_REL_ "GenSigTimeoutMsg" BU_SG_REL_ EBCM_OBD_CE SG_ 532 EBrkAstOtptRdPosStat 532;
BA_REL_ "GenSigTimeoutTime" BU_SG_REL_ EBCM_OBD_CE SG_ 532 EBrkAstOtptRdPosStat 250;
BA_REL_ "GenSigSuprvResp" BU_SG_REL_ EBCM_CE SG_ 532 EBrkAstOtptRdPosStat 1;
BA_REL_ "GenSigTimeoutMsg" BU_SG_REL_ EBCM_CE SG_ 532 EBrkAstOtptRdPosStat 532;
BA_REL_ "GenSigTimeoutTime" BU_SG_REL_ EBCM_CE SG_ 532 EBrkAstOtptRdPosStat 250;
BA_REL_ "GenSigSuprvResp" BU_SG_REL_ EBCM_OBD_CE SG_ 532 EBrkAstOtptRdPos 1;
BA_REL_ "GenSigTimeoutMsg" BU_SG_REL_ EBCM_OBD_CE SG_ 532 EBrkAstOtptRdPos 532;
BA_REL_ "GenSigTimeoutTime" BU_SG_REL_ EBCM_OBD_CE SG_ 532 EBrkAstOtptRdPos 250;
BA_REL_ "GenSigSuprvResp" BU_SG_REL_ EBCM_CE SG_ 532 EBrkAstOtptRdPos 1;
BA_REL_ "GenSigTimeoutMsg" BU_SG_REL_ EBCM_CE SG_ 532 EBrkAstOtptRdPos 532;
BA_REL_ "GenSigTimeoutTime" BU_SG_REL_ EBCM_CE SG_ 532 EBrkAstOtptRdPos 250;
BA_REL_ "GenSigSuprvResp" BU_SG_REL_ EBCM_OBD_CE SG_ 532 EBrkAstPresBlndgCap 1;
BA_REL_ "GenSigTimeoutMsg" BU_SG_REL_ EBCM_OBD_CE SG_ 532 EBrkAstPresBlndgCap 532;
BA_REL_ "GenSigTimeoutTime" BU_SG_REL_ EBCM_OBD_CE SG_ 532 EBrkAstPresBlndgCap 100;
BA_REL_ "GenSigSuprvResp" BU_SG_REL_ EBCM_CE SG_ 532 EBrkAstPresBlndgCap 1;
BA_REL_ "GenSigTimeoutMsg" BU_SG_REL_ EBCM_CE SG_ 532 EBrkAstPresBlndgCap 532;
BA_REL_ "GenSigTimeoutTime" BU_SG_REL_ EBCM_CE SG_ 532 EBrkAstPresBlndgCap 100;
BA_REL_ "GenSigSuprvResp" BU_SG_REL_ SDM_CE SG_ 530 ABSFld 1;
BA_REL_ "GenSigTimeoutMsg" BU_SG_REL_ SDM_CE SG_ 530 ABSFld 530;
BA_REL_ "GenSigTimeoutTime" BU_SG_REL_ SDM_CE SG_ 530 ABSFld 250;
BA_REL_ "GenSigSuprvResp" BU_SG_REL_ MSB1_CE SG_ 530 BrkPdDrvAPrsStaPVal 1;
BA_REL_ "GenSigTimeoutMsg" BU_SG_REL_ MSB1_CE SG_ 530 BrkPdDrvAPrsStaPVal 530;
BA_REL_ "GenSigTimeoutTime" BU_SG_REL_ MSB1_CE SG_ 530 BrkPdDrvAPrsStaPVal 250;
BA_REL_ "GenSigSuprvResp" BU_SG_REL_ MSB2_CE SG_ 530 BrkPdDrvAPrsStaPVal 1;
BA_REL_ "GenSigTimeoutMsg" BU_SG_REL_ MSB2_CE SG_ 530 BrkPdDrvAPrsStaPVal 530;
BA_REL_ "GenSigTimeoutTime" BU_SG_REL_ MSB2_CE SG_ 530 BrkPdDrvAPrsStaPVal 250;
BA_REL_ "GenSigSuprvResp" BU_SG_REL_ SADS_CE SG_ 530 BPDAPS_BkPDrvApPV 1;
BA_REL_ "GenSigTimeoutMsg" BU_SG_REL_ SADS_CE SG_ 530 BPDAPS_BkPDrvApPV 530;
BA_REL_ "GenSigTimeoutTime" BU_SG_REL_ SADS_CE SG_ 530 BPDAPS_BkPDrvApPV 250;
BA_REL_ "GenSigSuprvResp" BU_SG_REL_ MSB1_CE SG_ 530 BPDAPS_BkPDrvApPV 1;
BA_REL_ "GenSigTimeoutMsg" BU_SG_REL_ MSB1_CE SG_ 530 BPDAPS_BkPDrvApPV 530;
BA_REL_ "GenSigTimeoutTime" BU_SG_REL_ MSB1_CE SG_ 530 BPDAPS_BkPDrvApPV 250;
BA_REL_ "GenSigSuprvResp" BU_SG_REL_ MSB2_CE SG_ 530 BPDAPS_BkPDrvApPV 1;
BA_REL_ "GenSigTimeoutMsg" BU_SG_REL_ MSB2_CE SG_ 530 BPDAPS_BkPDrvApPV 530;
BA_REL_ "GenSigTimeoutTime" BU_SG_REL_ MSB2_CE SG_ 530 BPDAPS_BkPDrvApPV 250;
BA_REL_ "GenSigSuprvResp" BU_SG_REL_ SADS_CE SG_ 530 BPDAPS_BkPDrvApP 1;
BA_REL_ "GenSigTimeoutMsg" BU_SG_REL_ SADS_CE SG_ 530 BPDAPS_BkPDrvApP 530;
BA_REL_ "GenSigTimeoutTime" BU_SG_REL_ SADS_CE SG_ 530 BPDAPS_BkPDrvApP 250;
BA_REL_ "GenSigSuprvResp" BU_SG_REL_ MSB1_CE SG_ 530 BPDAPS_BkPDrvApP 1;
BA_REL_ "GenSigTimeoutMsg" BU_SG_REL_ MSB1_CE SG_ 530 BPDAPS_BkPDrvApP 530;
BA_REL_ "GenSigTimeoutTime" BU_SG_REL_ MSB1_CE SG_ 530 BPDAPS_BkPDrvApP 250;
BA_REL_ "GenSigSuprvResp" BU_SG_REL_ MSB2_CE SG_ 530 BPDAPS_BkPDrvApP 1;
BA_REL_ "GenSigTimeoutMsg" BU_SG_REL_ MSB2_CE SG_ 530 BPDAPS_BkPDrvApP 530;
BA_REL_ "GenSigTimeoutTime" BU_SG_REL_ MSB2_CE SG_ 530 BPDAPS_BkPDrvApP 250;
BA_REL_ "GenSigSuprvResp" BU_SG_REL_ MSB1_CE SG_ 530 BrkPdDrvAppPrsAlRC 1;
BA_REL_ "GenSigTimeoutMsg" BU_SG_REL_ MSB1_CE SG_ 530 BrkPdDrvAppPrsAlRC 530;
BA_REL_ "GenSigTimeoutTime" BU_SG_REL_ MSB1_CE SG_ 530 BrkPdDrvAppPrsAlRC 250;
BA_REL_ "GenSigSuprvResp" BU_SG_REL_ MSB2_CE SG_ 530 BrkPdDrvAppPrsAlRC 1;
BA_REL_ "GenSigTimeoutMsg" BU_SG_REL_ MSB2_CE SG_ 530 BrkPdDrvAppPrsAlRC 530;
BA_REL_ "GenSigTimeoutTime" BU_SG_REL_ MSB2_CE SG_ 530 BrkPdDrvAppPrsAlRC 250;
BA_REL_ "GenSigSuprvResp" BU_SG_REL_ RDCM_CE SG_ 530 ABSAtv 1;
BA_REL_ "GenSigTimeoutMsg" BU_SG_REL_ RDCM_CE SG_ 530 ABSAtv 530;
BA_REL_ "GenSigTimeoutTime" BU_SG_REL_ RDCM_CE SG_ 530 ABSAtv 250;
BA_REL_ "GenSigSuprvResp" BU_SG_REL_ SDM_CE SG_ 530 ABSAtv 1;
BA_REL_ "GenSigTimeoutMsg" BU_SG_REL_ SDM_CE SG_ 530 ABSAtv 530;
BA_REL_ "GenSigTimeoutTime" BU_SG_REL_ SDM_CE SG_ 530 ABSAtv 250;
BA_REL_ "GenSigSuprvResp" BU_SG_REL_ MSB1_CE SG_ 530 ABSAtv 1;
BA_REL_ "GenSigTimeoutMsg" BU_SG_REL_ MSB1_CE SG_ 530 ABSAtv 530;
BA_REL_ "GenSigTimeoutTime" BU_SG_REL_ MSB1_CE SG_ 530 ABSAtv 250;
BA_REL_ "GenSigSuprvResp" BU_SG_REL_ MSB2_CE SG_ 530 ABSAtv 1;
BA_REL_ "GenSigTimeoutMsg" BU_SG_REL_ MSB2_CE SG_ 530 ABSAtv 530;
BA_REL_ "GenSigTimeoutTime" BU_SG_REL_ MSB2_CE SG_ 530 ABSAtv 250;
BA_REL_ "GenSigSuprvResp" BU_SG_REL_ EPS_CE SG_ 530 ABSAtv 1;
BA_REL_ "GenSigTimeoutMsg" BU_SG_REL_ EPS_CE SG_ 530 ABSAtv 530;
BA_REL_ "GenSigTimeoutTime" BU_SG_REL_ EPS_CE SG_ 530 ABSAtv 250;
BA_REL_ "GenSigSuprvResp" BU_SG_REL_ EPS_JR_CE SG_ 530 BrkPdlPosGrad 1;
BA_REL_ "GenSigTimeoutMsg" BU_SG_REL_ EPS_JR_CE SG_ 530 BrkPdlPosGrad 530;
BA_REL_ "GenSigTimeoutTime" BU_SG_REL_ EPS_JR_CE SG_ 530 BrkPdlPosGrad 250;
BA_REL_ "GenSigSuprvResp" BU_SG_REL_ EPS_JR_CE SG_ 530 BrkPdlPos 1;
BA_REL_ "GenSigTimeoutMsg" BU_SG_REL_ EPS_JR_CE SG_ 530 BrkPdlPos 530;
BA_REL_ "GenSigTimeoutTime" BU_SG_REL_ EPS_JR_CE SG_ 530 BrkPdlPos 250;
BA_REL_ "GenSigSuprvResp" BU_SG_REL_ EPS_JR_CE SG_ 530 NotEventStat 1;
BA_REL_ "GenSigTimeoutMsg" BU_SG_REL_ EPS_JR_CE SG_ 530 NotEventStat 530;
BA_REL_ "GenSigTimeoutTime" BU_SG_REL_ EPS_JR_CE SG_ 530 NotEventStat 250;
BA_REL_ "GenSigSuprvResp" BU_SG_REL_ EPS_JR_CE SG_ 530 BrkPedPosAlvRolngCnt 1;
BA_REL_ "GenSigTimeoutMsg" BU_SG_REL_ EPS_JR_CE SG_ 530 BrkPedPosAlvRolngCnt 530;
BA_REL_ "GenSigTimeoutTime" BU_SG_REL_ EPS_JR_CE SG_ 530 BrkPedPosAlvRolngCnt 250;
BA_REL_ "GenSigSuprvResp" BU_SG_REL_ ARS_CE SG_ 530 WhlRotStatTmstmpRes 1;
BA_REL_ "GenSigTimeoutMsg" BU_SG_REL_ ARS_CE SG_ 530 WhlRotStatTmstmpRes 530;
BA_REL_ "GenSigTimeoutTime" BU_SG_REL_ ARS_CE SG_ 530 WhlRotStatTmstmpRes 250;
BA_REL_ "GenSigSuprvResp" BU_SG_REL_ APA_CE SG_ 530 WhlRotStatTmstmpRes 1;
BA_REL_ "GenSigTimeoutMsg" BU_SG_REL_ APA_CE SG_ 530 WhlRotStatTmstmpRes 530;
BA_REL_ "GenSigTimeoutTime" BU_SG_REL_ APA_CE SG_ 530 WhlRotStatTmstmpRes 250;
BA_REL_ "GenSigSuprvResp" BU_SG_REL_ EPS_JR_CE SG_ 530 WhlRotStatTmstmpRes 1;
BA_REL_ "GenSigTimeoutMsg" BU_SG_REL_ EPS_JR_CE SG_ 530 WhlRotStatTmstmpRes 530;
BA_REL_ "GenSigTimeoutTime" BU_SG_REL_ EPS_JR_CE SG_ 530 WhlRotStatTmstmpRes 250;
BA_REL_ "GenSigSuprvResp" BU_SG_REL_ EBOOST_CE SG_ 530 WhlRotStatTmstmpRes 1;
BA_REL_ "GenSigTimeoutMsg" BU_SG_REL_ EBOOST_CE SG_ 530 WhlRotStatTmstmpRes 530;
BA_REL_ "GenSigTimeoutTime" BU_SG_REL_ EBOOST_CE SG_ 530 WhlRotStatTmstmpRes 250;
BA_REL_ "GenSigSuprvResp" BU_SG_REL_ EPS_JR_CE SG_ 530 BrkAppSnsrHmPosLrnd 1;
BA_REL_ "GenSigTimeoutMsg" BU_SG_REL_ EPS_JR_CE SG_ 530 BrkAppSnsrHmPosLrnd 530;
BA_REL_ "GenSigTimeoutTime" BU_SG_REL_ EPS_JR_CE SG_ 530 BrkAppSnsrHmPosLrnd 250;
BA_REL_ "GenSigSuprvResp" BU_SG_REL_ EPS_JR_CE SG_ 530 BrkPdlModTrvl 1;
BA_REL_ "GenSigTimeoutMsg" BU_SG_REL_ EPS_JR_CE SG_ 530 BrkPdlModTrvl 530;
BA_REL_ "GenSigTimeoutTime" BU_SG_REL_ EPS_JR_CE SG_ 530 BrkPdlModTrvl 250;
BA_REL_ "GenSigSuprvResp" BU_SG_REL_ EBOOST_CE SG_ 530 PrplsnSysAtv 1;
BA_REL_ "GenSigTimeoutMsg" BU_SG_REL_ EBOOST_CE SG_ 530 PrplsnSysAtv 530;
BA_REL_ "GenSigTimeoutTime" BU_SG_REL_ EBOOST_CE SG_ 530 PrplsnSysAtv 250;
BA_REL_ "GenSigSuprvResp" BU_SG_REL_ EPS_JR_CE SG_ 384 TrqOvrlARC 1;
BA_REL_ "GenSigTimeoutMsg" BU_SG_REL_ EPS_JR_CE SG_ 384 TrqOvrlARC 384;
BA_REL_ "GenSigTimeoutTime" BU_SG_REL_ EPS_JR_CE SG_ 384 TrqOvrlARC 250;
BA_REL_ "GenSigSuprvResp" BU_SG_REL_ EPS_JR_CE SG_ 384 TqOvrDltTqCmdVl 1;
BA_REL_ "GenSigTimeoutMsg" BU_SG_REL_ EPS_JR_CE SG_ 384 TqOvrDltTqCmdVl 384;
BA_REL_ "GenSigTimeoutTime" BU_SG_REL_ EPS_JR_CE SG_ 384 TqOvrDltTqCmdVl 250;
BA_REL_ "GenSigSuprvResp" BU_SG_REL_ EPS_JR_CE SG_ 384 TqOvrDltTqCmdAct 1;
BA_REL_ "GenSigTimeoutMsg" BU_SG_REL_ EPS_JR_CE SG_ 384 TqOvrDltTqCmdAct 384;
BA_REL_ "GenSigTimeoutTime" BU_SG_REL_ EPS_JR_CE SG_ 384 TqOvrDltTqCmdAct 250;
BA_REL_ "GenSigSuprvResp" BU_SG_REL_ EPS_JR_CE SG_ 384 TrqOvrlCmdChksm 1;
BA_REL_ "GenSigTimeoutMsg" BU_SG_REL_ EPS_JR_CE SG_ 384 TrqOvrlCmdChksm 384;
BA_REL_ "GenSigTimeoutTime" BU_SG_REL_ EPS_JR_CE SG_ 384 TrqOvrlCmdChksm 250;
BA_REL_ "GenSigSuprvResp" BU_SG_REL_ MSB1_CE SG_ 869 ClsnJmntLnPssd 1;
BA_REL_ "GenSigTimeoutMsg" BU_SG_REL_ MSB1_CE SG_ 869 ClsnJmntLnPssd 869;
BA_REL_ "GenSigTimeoutTime" BU_SG_REL_ MSB1_CE SG_ 869 ClsnJmntLnPssd 250;
BA_REL_ "GenSigSuprvResp" BU_SG_REL_ MSB2_CE SG_ 869 ClsnJmntLnPssd 1;
BA_REL_ "GenSigTimeoutMsg" BU_SG_REL_ MSB2_CE SG_ 869 ClsnJmntLnPssd 869;
BA_REL_ "GenSigTimeoutTime" BU_SG_REL_ MSB2_CE SG_ 869 ClsnJmntLnPssd 250;
BA_REL_ "GenSigSuprvResp" BU_SG_REL_ MSB1_CE SG_ 869 ColPrSysCrntStng 1;
BA_REL_ "GenSigTimeoutMsg" BU_SG_REL_ MSB1_CE SG_ 869 ColPrSysCrntStng 869;
BA_REL_ "GenSigTimeoutTime" BU_SG_REL_ MSB1_CE SG_ 869 ColPrSysCrntStng 250;
BA_REL_ "GenSigSuprvResp" BU_SG_REL_ MSB2_CE SG_ 869 ColPrSysCrntStng 1;
BA_REL_ "GenSigTimeoutMsg" BU_SG_REL_ MSB2_CE SG_ 869 ColPrSysCrntStng 869;
BA_REL_ "GenSigTimeoutTime" BU_SG_REL_ MSB2_CE SG_ 869 ColPrSysCrntStng 250;
BA_REL_ "GenSigSuprvResp" BU_SG_REL_ EOCM_F_CE SG_ 374 ARSOpStat 1;
BA_REL_ "GenSigTimeoutMsg" BU_SG_REL_ EOCM_F_CE SG_ 374 ARSOpStat 374;
BA_REL_ "GenSigTimeoutTime" BU_SG_REL_ EOCM_F_CE SG_ 374 ARSOpStat 120;
BA_REL_ "GenSigSuprvResp" BU_SG_REL_ MSB2_CE SG_ 374 ARSOpStat 1;
BA_REL_ "GenSigTimeoutMsg" BU_SG_REL_ MSB2_CE SG_ 374 ARSOpStat 374;
BA_REL_ "GenSigTimeoutTime" BU_SG_REL_ MSB2_CE SG_ 374 ARSOpStat 250;
BA_REL_ "GenSigSuprvResp" BU_SG_REL_ MSB1_CE SG_ 374 ARSOpStat 1;
BA_REL_ "GenSigTimeoutMsg" BU_SG_REL_ MSB1_CE SG_ 374 ARSOpStat 374;
BA_REL_ "GenSigTimeoutTime" BU_SG_REL_ MSB1_CE SG_ 374 ARSOpStat 250;
BA_REL_ "GenSigSuprvResp" BU_SG_REL_ APA_CE SG_ 374 ARSOpStat 1;
BA_REL_ "GenSigTimeoutMsg" BU_SG_REL_ APA_CE SG_ 374 ARSOpStat 374;
BA_REL_ "GenSigTimeoutTime" BU_SG_REL_ APA_CE SG_ 374 ARSOpStat 250;
BA_REL_ "GenSigSuprvResp" BU_SG_REL_ EOCM_F_CE SG_ 374 ARSAlgmtCmplt 1;
BA_REL_ "GenSigTimeoutMsg" BU_SG_REL_ EOCM_F_CE SG_ 374 ARSAlgmtCmplt 374;
BA_REL_ "GenSigTimeoutTime" BU_SG_REL_ EOCM_F_CE SG_ 374 ARSAlgmtCmplt 120;
BA_REL_ "GenSigSuprvResp" BU_SG_REL_ MSB2_CE SG_ 374 ARSAlgmtCmplt 1;
BA_REL_ "GenSigTimeoutMsg" BU_SG_REL_ MSB2_CE SG_ 374 ARSAlgmtCmplt 374;
BA_REL_ "GenSigTimeoutTime" BU_SG_REL_ MSB2_CE SG_ 374 ARSAlgmtCmplt 250;
BA_REL_ "GenSigSuprvResp" BU_SG_REL_ MSB1_CE SG_ 374 ARSAlgmtCmplt 1;
BA_REL_ "GenSigTimeoutMsg" BU_SG_REL_ MSB1_CE SG_ 374 ARSAlgmtCmplt 374;
BA_REL_ "GenSigTimeoutTime" BU_SG_REL_ MSB1_CE SG_ 374 ARSAlgmtCmplt 250;
BA_REL_ "GenSigSuprvResp" BU_SG_REL_ APA_CE SG_ 374 ARSAlgmtCmplt 1;
BA_REL_ "GenSigTimeoutMsg" BU_SG_REL_ APA_CE SG_ 374 ARSAlgmtCmplt 374;
BA_REL_ "GenSigTimeoutTime" BU_SG_REL_ APA_CE SG_ 374 ARSAlgmtCmplt 250;
BA_REL_ "GenSigSuprvResp" BU_SG_REL_ EOCM_F_CE SG_ 374 ARSActAngl 1;
BA_REL_ "GenSigTimeoutMsg" BU_SG_REL_ EOCM_F_CE SG_ 374 ARSActAngl 374;
BA_REL_ "GenSigTimeoutTime" BU_SG_REL_ EOCM_F_CE SG_ 374 ARSActAngl 120;
BA_REL_ "GenSigSuprvResp" BU_SG_REL_ MSB2_CE SG_ 374 ARSActAngl 1;
BA_REL_ "GenSigTimeoutMsg" BU_SG_REL_ MSB2_CE SG_ 374 ARSActAngl 374;
BA_REL_ "GenSigTimeoutTime" BU_SG_REL_ MSB2_CE SG_ 374 ARSActAngl 250;
BA_REL_ "GenSigSuprvResp" BU_SG_REL_ MSB1_CE SG_ 374 ARSActAngl 1;
BA_REL_ "GenSigTimeoutMsg" BU_SG_REL_ MSB1_CE SG_ 374 ARSActAngl 374;
BA_REL_ "GenSigTimeoutTime" BU_SG_REL_ MSB1_CE SG_ 374 ARSActAngl 250;
BA_REL_ "GenSigSuprvResp" BU_SG_REL_ APA_CE SG_ 374 ARSActAngl 1;
BA_REL_ "GenSigTimeoutMsg" BU_SG_REL_ APA_CE SG_ 374 ARSActAngl 374;
BA_REL_ "GenSigTimeoutTime" BU_SG_REL_ APA_CE SG_ 374 ARSActAngl 250;
BA_REL_ "GenSigSuprvResp" BU_SG_REL_ EBCM_OBD_CE SG_ 508 LonLatAccSnsValARC 1;
BA_REL_ "GenSigTimeoutMsg" BU_SG_REL_ EBCM_OBD_CE SG_ 508 LonLatAccSnsValARC 508;
BA_REL_ "GenSigTimeoutTime" BU_SG_REL_ EBCM_OBD_CE SG_ 508 LonLatAccSnsValARC 125;
BA_REL_ "GenSigSuprvResp" BU_SG_REL_ EBCM_CE SG_ 508 LonLatAccSnsValARC 1;
BA_REL_ "GenSigTimeoutMsg" BU_SG_REL_ EBCM_CE SG_ 508 LonLatAccSnsValARC 508;
BA_REL_ "GenSigTimeoutTime" BU_SG_REL_ EBCM_CE SG_ 508 LonLatAccSnsValARC 125;
BA_REL_ "GenSigSuprvResp" BU_SG_REL_ EBCM_OBD_CE SG_ 508 LonLatAccSnsChk 1;
BA_REL_ "GenSigTimeoutMsg" BU_SG_REL_ EBCM_OBD_CE SG_ 508 LonLatAccSnsChk 508;
BA_REL_ "GenSigTimeoutTime" BU_SG_REL_ EBCM_OBD_CE SG_ 508 LonLatAccSnsChk 125;
BA_REL_ "GenSigSuprvResp" BU_SG_REL_ EBCM_CE SG_ 508 LonLatAccSnsChk 1;
BA_REL_ "GenSigTimeoutMsg" BU_SG_REL_ EBCM_CE SG_ 508 LonLatAccSnsChk 508;
BA_REL_ "GenSigTimeoutTime" BU_SG_REL_ EBCM_CE SG_ 508 LonLatAccSnsChk 125;
BA_REL_ "GenSigSuprvResp" BU_SG_REL_ EBCM_OBD_CE SG_ 508 LatAccSnsVal 1;
BA_REL_ "GenSigTimeoutMsg" BU_SG_REL_ EBCM_OBD_CE SG_ 508 LatAccSnsVal 508;
BA_REL_ "GenSigTimeoutTime" BU_SG_REL_ EBCM_OBD_CE SG_ 508 LatAccSnsVal 125;
BA_REL_ "GenSigSuprvResp" BU_SG_REL_ EBCM_CE SG_ 508 LatAccSnsVal 1;
BA_REL_ "GenSigTimeoutMsg" BU_SG_REL_ EBCM_CE SG_ 508 LatAccSnsVal 508;
BA_REL_ "GenSigTimeoutTime" BU_SG_REL_ EBCM_CE SG_ 508 LatAccSnsVal 125;
BA_REL_ "GenSigSuprvResp" BU_SG_REL_ EBCM_OBD_CE SG_ 508 LonAccSnsVal 1;
BA_REL_ "GenSigTimeoutMsg" BU_SG_REL_ EBCM_OBD_CE SG_ 508 LonAccSnsVal 508;
BA_REL_ "GenSigTimeoutTime" BU_SG_REL_ EBCM_OBD_CE SG_ 508 LonAccSnsVal 125;
BA_REL_ "GenSigSuprvResp" BU_SG_REL_ EBCM_CE SG_ 508 LonAccSnsVal 1;
BA_REL_ "GenSigTimeoutMsg" BU_SG_REL_ EBCM_CE SG_ 508 LonAccSnsVal 508;
BA_REL_ "GenSigTimeoutTime" BU_SG_REL_ EBCM_CE SG_ 508 LonAccSnsVal 125;
BA_REL_ "GenSigSuprvResp" BU_SG_REL_ EBCM_OBD_CE SG_ 369 APABrkReqProtVal 1;
BA_REL_ "GenSigTimeoutMsg" BU_SG_REL_ EBCM_OBD_CE SG_ 369 APABrkReqProtVal 369;
BA_REL_ "GenSigTimeoutTime" BU_SG_REL_ EBCM_OBD_CE SG_ 369 APABrkReqProtVal 250;
BA_REL_ "GenSigSuprvResp" BU_SG_REL_ EBCM_CE SG_ 369 APABrkReqProtVal 1;
BA_REL_ "GenSigTimeoutMsg" BU_SG_REL_ EBCM_CE SG_ 369 APABrkReqProtVal 369;
BA_REL_ "GenSigTimeoutTime" BU_SG_REL_ EBCM_CE SG_ 369 APABrkReqProtVal 250;
BA_REL_ "GenSigSuprvResp" BU_SG_REL_ EBCM_OBD_CE SG_ 369 APABR_CtrlAcc 1;
BA_REL_ "GenSigTimeoutMsg" BU_SG_REL_ EBCM_OBD_CE SG_ 369 APABR_CtrlAcc 369;
BA_REL_ "GenSigTimeoutTime" BU_SG_REL_ EBCM_OBD_CE SG_ 369 APABR_CtrlAcc 250;
BA_REL_ "GenSigSuprvResp" BU_SG_REL_ EBCM_CE SG_ 369 APABR_CtrlAcc 1;
BA_REL_ "GenSigTimeoutMsg" BU_SG_REL_ EBCM_CE SG_ 369 APABR_CtrlAcc 369;
BA_REL_ "GenSigTimeoutTime" BU_SG_REL_ EBCM_CE SG_ 369 APABR_CtrlAcc 250;
BA_REL_ "GenSigSuprvResp" BU_SG_REL_ EBCM_OBD_CE SG_ 369 APABR_AutBrkRmpRt 1;
BA_REL_ "GenSigTimeoutMsg" BU_SG_REL_ EBCM_OBD_CE SG_ 369 APABR_AutBrkRmpRt 369;
BA_REL_ "GenSigTimeoutTime" BU_SG_REL_ EBCM_OBD_CE SG_ 369 APABR_AutBrkRmpRt 250;
BA_REL_ "GenSigSuprvResp" BU_SG_REL_ EBCM_CE SG_ 369 APABR_AutBrkRmpRt 1;
BA_REL_ "GenSigTimeoutMsg" BU_SG_REL_ EBCM_CE SG_ 369 APABR_AutBrkRmpRt 369;
BA_REL_ "GenSigTimeoutTime" BU_SG_REL_ EBCM_CE SG_ 369 APABR_AutBrkRmpRt 250;
BA_REL_ "GenSigSuprvResp" BU_SG_REL_ EBCM_OBD_CE SG_ 369 APABR_AutBrkRqTyp 1;
BA_REL_ "GenSigTimeoutMsg" BU_SG_REL_ EBCM_OBD_CE SG_ 369 APABR_AutBrkRqTyp 369;
BA_REL_ "GenSigTimeoutTime" BU_SG_REL_ EBCM_OBD_CE SG_ 369 APABR_AutBrkRqTyp 250;
BA_REL_ "GenSigSuprvResp" BU_SG_REL_ EBCM_CE SG_ 369 APABR_AutBrkRqTyp 1;
BA_REL_ "GenSigTimeoutMsg" BU_SG_REL_ EBCM_CE SG_ 369 APABR_AutBrkRqTyp 369;
BA_REL_ "GenSigTimeoutTime" BU_SG_REL_ EBCM_CE SG_ 369 APABR_AutBrkRqTyp 250;
BA_REL_ "GenSigSuprvResp" BU_SG_REL_ EBCM_OBD_CE SG_ 369 APABR_AutBrkRqd 1;
BA_REL_ "GenSigTimeoutMsg" BU_SG_REL_ EBCM_OBD_CE SG_ 369 APABR_AutBrkRqd 369;
BA_REL_ "GenSigTimeoutTime" BU_SG_REL_ EBCM_OBD_CE SG_ 369 APABR_AutBrkRqd 250;
BA_REL_ "GenSigSuprvResp" BU_SG_REL_ EBCM_CE SG_ 369 APABR_AutBrkRqd 1;
BA_REL_ "GenSigTimeoutMsg" BU_SG_REL_ EBCM_CE SG_ 369 APABR_AutBrkRqd 369;
BA_REL_ "GenSigTimeoutTime" BU_SG_REL_ EBCM_CE SG_ 369 APABR_AutBrkRqd 250;
BA_REL_ "GenSigSuprvResp" BU_SG_REL_ EBCM_OBD_CE SG_ 369 APABR_APA2Pstat 1;
BA_REL_ "GenSigTimeoutMsg" BU_SG_REL_ EBCM_OBD_CE SG_ 369 APABR_APA2Pstat 369;
BA_REL_ "GenSigTimeoutTime" BU_SG_REL_ EBCM_OBD_CE SG_ 369 APABR_APA2Pstat 250;
BA_REL_ "GenSigSuprvResp" BU_SG_REL_ EBCM_CE SG_ 369 APABR_APA2Pstat 1;
BA_REL_ "GenSigTimeoutMsg" BU_SG_REL_ EBCM_CE SG_ 369 APABR_APA2Pstat 369;
BA_REL_ "GenSigTimeoutTime" BU_SG_REL_ EBCM_CE SG_ 369 APABR_APA2Pstat 250;
BA_REL_ "GenSigSuprvResp" BU_SG_REL_ EBCM_OBD_CE SG_ 369 APABrkReqRC 1;
BA_REL_ "GenSigTimeoutMsg" BU_SG_REL_ EBCM_OBD_CE SG_ 369 APABrkReqRC 369;
BA_REL_ "GenSigTimeoutTime" BU_SG_REL_ EBCM_OBD_CE SG_ 369 APABrkReqRC 250;
BA_REL_ "GenSigSuprvResp" BU_SG_REL_ EBCM_CE SG_ 369 APABrkReqRC 1;
BA_REL_ "GenSigTimeoutMsg" BU_SG_REL_ EBCM_CE SG_ 369 APABrkReqRC 369;
BA_REL_ "GenSigTimeoutTime" BU_SG_REL_ EBCM_CE SG_ 369 APABrkReqRC 250;
BA_REL_ "GenSigSuprvResp" BU_SG_REL_ HCP_T_CE SG_ 197 WRSLNDWhlDisTpRC 1;
BA_REL_ "GenSigTimeoutMsg" BU_SG_REL_ HCP_T_CE SG_ 197 WRSLNDWhlDisTpRC 197;
BA_REL_ "GenSigTimeoutTime" BU_SG_REL_ HCP_T_CE SG_ 197 WRSLNDWhlDisTpRC 25;
BA_REL_ "GenSigSuprvResp" BU_SG_REL_ HCP_CE SG_ 197 WRSLNDWhlDisTpRC 1;
BA_REL_ "GenSigTimeoutMsg" BU_SG_REL_ HCP_CE SG_ 197 WRSLNDWhlDisTpRC 197;
BA_REL_ "GenSigTimeoutTime" BU_SG_REL_ HCP_CE SG_ 197 WRSLNDWhlDisTpRC 25;
BA_REL_ "GenSigSuprvResp" BU_SG_REL_ RDCM_CE SG_ 197 WRSLNDWhlDisTpRC 1;
BA_REL_ "GenSigTimeoutMsg" BU_SG_REL_ RDCM_CE SG_ 197 WRSLNDWhlDisTpRC 197;
BA_REL_ "GenSigTimeoutTime" BU_SG_REL_ RDCM_CE SG_ 197 WRSLNDWhlDisTpRC 250;
BA_REL_ "GenSigSuprvResp" BU_SG_REL_ ARS_CE SG_ 197 WRSLNDWhlDisTpRC 1;
BA_REL_ "GenSigTimeoutMsg" BU_SG_REL_ ARS_CE SG_ 197 WRSLNDWhlDisTpRC 197;
BA_REL_ "GenSigTimeoutTime" BU_SG_REL_ ARS_CE SG_ 197 WRSLNDWhlDisTpRC 250;
BA_REL_ "GenSigSuprvResp" BU_SG_REL_ EOCM_F_CE SG_ 197 WRSLNDWhlDisTpRC 1;
BA_REL_ "GenSigTimeoutMsg" BU_SG_REL_ EOCM_F_CE SG_ 197 WRSLNDWhlDisTpRC 197;
BA_REL_ "GenSigTimeoutTime" BU_SG_REL_ EOCM_F_CE SG_ 197 WRSLNDWhlDisTpRC 120;
BA_REL_ "GenSigSuprvResp" BU_SG_REL_ HCP_T_CE SG_ 197 WRSLNDWhlRotStRst 1;
BA_REL_ "GenSigTimeoutMsg" BU_SG_REL_ HCP_T_CE SG_ 197 WRSLNDWhlRotStRst 197;
BA_REL_ "GenSigTimeoutTime" BU_SG_REL_ HCP_T_CE SG_ 197 WRSLNDWhlRotStRst 25;
BA_REL_ "GenSigSuprvResp" BU_SG_REL_ HCP_CE SG_ 197 WRSLNDWhlRotStRst 1;
BA_REL_ "GenSigTimeoutMsg" BU_SG_REL_ HCP_CE SG_ 197 WRSLNDWhlRotStRst 197;
BA_REL_ "GenSigTimeoutTime" BU_SG_REL_ HCP_CE SG_ 197 WRSLNDWhlRotStRst 25;
BA_REL_ "GenSigSuprvResp" BU_SG_REL_ RDCM_CE SG_ 197 WRSLNDWhlRotStRst 1;
BA_REL_ "GenSigTimeoutMsg" BU_SG_REL_ RDCM_CE SG_ 197 WRSLNDWhlRotStRst 197;
BA_REL_ "GenSigTimeoutTime" BU_SG_REL_ RDCM_CE SG_ 197 WRSLNDWhlRotStRst 250;
BA_REL_ "GenSigSuprvResp" BU_SG_REL_ ARS_CE SG_ 197 WRSLNDWhlRotStRst 1;
BA_REL_ "GenSigTimeoutMsg" BU_SG_REL_ ARS_CE SG_ 197 WRSLNDWhlRotStRst 197;
BA_REL_ "GenSigTimeoutTime" BU_SG_REL_ ARS_CE SG_ 197 WRSLNDWhlRotStRst 250;
BA_REL_ "GenSigSuprvResp" BU_SG_REL_ EOCM_F_CE SG_ 197 WRSLNDWhlRotStRst 1;
BA_REL_ "GenSigTimeoutMsg" BU_SG_REL_ EOCM_F_CE SG_ 197 WRSLNDWhlRotStRst 197;
BA_REL_ "GenSigTimeoutTime" BU_SG_REL_ EOCM_F_CE SG_ 197 WRSLNDWhlRotStRst 120;
BA_REL_ "GenSigSuprvResp" BU_SG_REL_ HCP_T_CE SG_ 197 WRSLNDWhlDistVal 1;
BA_REL_ "GenSigTimeoutMsg" BU_SG_REL_ HCP_T_CE SG_ 197 WRSLNDWhlDistVal 197;
BA_REL_ "GenSigTimeoutTime" BU_SG_REL_ HCP_T_CE SG_ 197 WRSLNDWhlDistVal 25;
BA_REL_ "GenSigSuprvResp" BU_SG_REL_ HCP_CE SG_ 197 WRSLNDWhlDistVal 1;
BA_REL_ "GenSigTimeoutMsg" BU_SG_REL_ HCP_CE SG_ 197 WRSLNDWhlDistVal 197;
BA_REL_ "GenSigTimeoutTime" BU_SG_REL_ HCP_CE SG_ 197 WRSLNDWhlDistVal 25;
BA_REL_ "GenSigSuprvResp" BU_SG_REL_ RDCM_CE SG_ 197 WRSLNDWhlDistVal 1;
BA_REL_ "GenSigTimeoutMsg" BU_SG_REL_ RDCM_CE SG_ 197 WRSLNDWhlDistVal 197;
BA_REL_ "GenSigTimeoutTime" BU_SG_REL_ RDCM_CE SG_ 197 WRSLNDWhlDistVal 250;
BA_REL_ "GenSigSuprvResp" BU_SG_REL_ ARS_CE SG_ 197 WRSLNDWhlDistVal 1;
BA_REL_ "GenSigTimeoutMsg" BU_SG_REL_ ARS_CE SG_ 197 WRSLNDWhlDistVal 197;
BA_REL_ "GenSigTimeoutTime" BU_SG_REL_ ARS_CE SG_ 197 WRSLNDWhlDistVal 250;
BA_REL_ "GenSigSuprvResp" BU_SG_REL_ EOCM_F_CE SG_ 197 WRSLNDWhlDistVal 1;
BA_REL_ "GenSigTimeoutMsg" BU_SG_REL_ EOCM_F_CE SG_ 197 WRSLNDWhlDistVal 197;
BA_REL_ "GenSigTimeoutTime" BU_SG_REL_ EOCM_F_CE SG_ 197 WRSLNDWhlDistVal 120;
BA_REL_ "GenSigSuprvResp" BU_SG_REL_ HCP_T_CE SG_ 197 WRSLNDWhlDistTstm 1;
BA_REL_ "GenSigTimeoutMsg" BU_SG_REL_ HCP_T_CE SG_ 197 WRSLNDWhlDistTstm 197;
BA_REL_ "GenSigTimeoutTime" BU_SG_REL_ HCP_T_CE SG_ 197 WRSLNDWhlDistTstm 25;
BA_REL_ "GenSigSuprvResp" BU_SG_REL_ HCP_CE SG_ 197 WRSLNDWhlDistTstm 1;
BA_REL_ "GenSigTimeoutMsg" BU_SG_REL_ HCP_CE SG_ 197 WRSLNDWhlDistTstm 197;
BA_REL_ "GenSigTimeoutTime" BU_SG_REL_ HCP_CE SG_ 197 WRSLNDWhlDistTstm 25;
BA_REL_ "GenSigSuprvResp" BU_SG_REL_ RDCM_CE SG_ 197 WRSLNDWhlDistTstm 1;
BA_REL_ "GenSigTimeoutMsg" BU_SG_REL_ RDCM_CE SG_ 197 WRSLNDWhlDistTstm 197;
BA_REL_ "GenSigTimeoutTime" BU_SG_REL_ RDCM_CE SG_ 197 WRSLNDWhlDistTstm 250;
BA_REL_ "GenSigSuprvResp" BU_SG_REL_ ARS_CE SG_ 197 WRSLNDWhlDistTstm 1;
BA_REL_ "GenSigTimeoutMsg" BU_SG_REL_ ARS_CE SG_ 197 WRSLNDWhlDistTstm 197;
BA_REL_ "GenSigTimeoutTime" BU_SG_REL_ ARS_CE SG_ 197 WRSLNDWhlDistTstm 250;
BA_REL_ "GenSigSuprvResp" BU_SG_REL_ EOCM_F_CE SG_ 197 WRSLNDWhlDistTstm 1;
BA_REL_ "GenSigTimeoutMsg" BU_SG_REL_ EOCM_F_CE SG_ 197 WRSLNDWhlDistTstm 197;
BA_REL_ "GenSigTimeoutTime" BU_SG_REL_ EOCM_F_CE SG_ 197 WRSLNDWhlDistTstm 120;
BA_REL_ "GenSigSuprvResp" BU_SG_REL_ HCP_T_CE SG_ 197 WRSLNDWhlDistPCntr 1;
BA_REL_ "GenSigTimeoutMsg" BU_SG_REL_ HCP_T_CE SG_ 197 WRSLNDWhlDistPCntr 197;
BA_REL_ "GenSigTimeoutTime" BU_SG_REL_ HCP_T_CE SG_ 197 WRSLNDWhlDistPCntr 25;
BA_REL_ "GenSigSuprvResp" BU_SG_REL_ HCP_CE SG_ 197 WRSLNDWhlDistPCntr 1;
BA_REL_ "GenSigTimeoutMsg" BU_SG_REL_ HCP_CE SG_ 197 WRSLNDWhlDistPCntr 197;
BA_REL_ "GenSigTimeoutTime" BU_SG_REL_ HCP_CE SG_ 197 WRSLNDWhlDistPCntr 25;
BA_REL_ "GenSigSuprvResp" BU_SG_REL_ RDCM_CE SG_ 197 WRSLNDWhlDistPCntr 1;
BA_REL_ "GenSigTimeoutMsg" BU_SG_REL_ RDCM_CE SG_ 197 WRSLNDWhlDistPCntr 197;
BA_REL_ "GenSigTimeoutTime" BU_SG_REL_ RDCM_CE SG_ 197 WRSLNDWhlDistPCntr 250;
BA_REL_ "GenSigSuprvResp" BU_SG_REL_ ARS_CE SG_ 197 WRSLNDWhlDistPCntr 1;
BA_REL_ "GenSigTimeoutMsg" BU_SG_REL_ ARS_CE SG_ 197 WRSLNDWhlDistPCntr 197;
BA_REL_ "GenSigTimeoutTime" BU_SG_REL_ ARS_CE SG_ 197 WRSLNDWhlDistPCntr 250;
BA_REL_ "GenSigSuprvResp" BU_SG_REL_ EOCM_F_CE SG_ 197 WRSLNDWhlDistPCntr 1;
BA_REL_ "GenSigTimeoutMsg" BU_SG_REL_ EOCM_F_CE SG_ 197 WRSLNDWhlDistPCntr 197;
BA_REL_ "GenSigTimeoutTime" BU_SG_REL_ EOCM_F_CE SG_ 197 WRSLNDWhlDistPCntr 120;
BA_REL_ "GenSigSuprvResp" BU_SG_REL_ HCP_T_CE SG_ 197 WRSLNDSeqNum 1;
BA_REL_ "GenSigTimeoutMsg" BU_SG_REL_ HCP_T_CE SG_ 197 WRSLNDSeqNum 197;
BA_REL_ "GenSigTimeoutTime" BU_SG_REL_ HCP_T_CE SG_ 197 WRSLNDSeqNum 25;
BA_REL_ "GenSigSuprvResp" BU_SG_REL_ HCP_CE SG_ 197 WRSLNDSeqNum 1;
BA_REL_ "GenSigTimeoutMsg" BU_SG_REL_ HCP_CE SG_ 197 WRSLNDSeqNum 197;
BA_REL_ "GenSigTimeoutTime" BU_SG_REL_ HCP_CE SG_ 197 WRSLNDSeqNum 25;
BA_REL_ "GenSigSuprvResp" BU_SG_REL_ RDCM_CE SG_ 197 WRSLNDSeqNum 1;
BA_REL_ "GenSigTimeoutMsg" BU_SG_REL_ RDCM_CE SG_ 197 WRSLNDSeqNum 197;
BA_REL_ "GenSigTimeoutTime" BU_SG_REL_ RDCM_CE SG_ 197 WRSLNDSeqNum 250;
BA_REL_ "GenSigSuprvResp" BU_SG_REL_ ARS_CE SG_ 197 WRSLNDSeqNum 1;
BA_REL_ "GenSigTimeoutMsg" BU_SG_REL_ ARS_CE SG_ 197 WRSLNDSeqNum 197;
BA_REL_ "GenSigTimeoutTime" BU_SG_REL_ ARS_CE SG_ 197 WRSLNDSeqNum 250;
BA_REL_ "GenSigSuprvResp" BU_SG_REL_ EOCM_F_CE SG_ 197 WRSLNDSeqNum 1;
BA_REL_ "GenSigTimeoutMsg" BU_SG_REL_ EOCM_F_CE SG_ 197 WRSLNDSeqNum 197;
BA_REL_ "GenSigTimeoutTime" BU_SG_REL_ EOCM_F_CE SG_ 197 WRSLNDSeqNum 120;
BA_REL_ "GenSigSuprvResp" BU_SG_REL_ HCP_T_CE SG_ 197 WRSRNDWhlDisTpRC 1;
BA_REL_ "GenSigTimeoutMsg" BU_SG_REL_ HCP_T_CE SG_ 197 WRSRNDWhlDisTpRC 197;
BA_REL_ "GenSigTimeoutTime" BU_SG_REL_ HCP_T_CE SG_ 197 WRSRNDWhlDisTpRC 25;
BA_REL_ "GenSigSuprvResp" BU_SG_REL_ HCP_CE SG_ 197 WRSRNDWhlDisTpRC 1;
BA_REL_ "GenSigTimeoutMsg" BU_SG_REL_ HCP_CE SG_ 197 WRSRNDWhlDisTpRC 197;
BA_REL_ "GenSigTimeoutTime" BU_SG_REL_ HCP_CE SG_ 197 WRSRNDWhlDisTpRC 25;
BA_REL_ "GenSigTimeoutMsg" BU_SG_REL_ RDCM_CE SG_ 197 WRSRNDWhlDisTpRC 197;
BA_REL_ "GenSigTimeoutTime" BU_SG_REL_ RDCM_CE SG_ 197 WRSRNDWhlDisTpRC 250;
BA_REL_ "GenSigSuprvResp" BU_SG_REL_ ARS_CE SG_ 197 WRSRNDWhlDisTpRC 1;
BA_REL_ "GenSigTimeoutMsg" BU_SG_REL_ ARS_CE SG_ 197 WRSRNDWhlDisTpRC 197;
BA_REL_ "GenSigTimeoutTime" BU_SG_REL_ ARS_CE SG_ 197 WRSRNDWhlDisTpRC 250;
BA_REL_ "GenSigSuprvResp" BU_SG_REL_ EOCM_F_CE SG_ 197 WRSRNDWhlDisTpRC 1;
BA_REL_ "GenSigTimeoutMsg" BU_SG_REL_ EOCM_F_CE SG_ 197 WRSRNDWhlDisTpRC 197;
BA_REL_ "GenSigTimeoutTime" BU_SG_REL_ EOCM_F_CE SG_ 197 WRSRNDWhlDisTpRC 120;
BA_REL_ "GenSigSuprvResp" BU_SG_REL_ HCP_T_CE SG_ 197 WRSRNDWhlRotStRst 1;
BA_REL_ "GenSigTimeoutMsg" BU_SG_REL_ HCP_T_CE SG_ 197 WRSRNDWhlRotStRst 197;
BA_REL_ "GenSigTimeoutTime" BU_SG_REL_ HCP_T_CE SG_ 197 WRSRNDWhlRotStRst 25;
BA_REL_ "GenSigSuprvResp" BU_SG_REL_ HCP_CE SG_ 197 WRSRNDWhlRotStRst 1;
BA_REL_ "GenSigTimeoutMsg" BU_SG_REL_ HCP_CE SG_ 197 WRSRNDWhlRotStRst 197;
BA_REL_ "GenSigTimeoutTime" BU_SG_REL_ HCP_CE SG_ 197 WRSRNDWhlRotStRst 25;
BA_REL_ "GenSigTimeoutMsg" BU_SG_REL_ RDCM_CE SG_ 197 WRSRNDWhlRotStRst 197;
BA_REL_ "GenSigTimeoutTime" BU_SG_REL_ RDCM_CE SG_ 197 WRSRNDWhlRotStRst 250;
BA_REL_ "GenSigSuprvResp" BU_SG_REL_ ARS_CE SG_ 197 WRSRNDWhlRotStRst 1;
BA_REL_ "GenSigTimeoutMsg" BU_SG_REL_ ARS_CE SG_ 197 WRSRNDWhlRotStRst 197;
BA_REL_ "GenSigTimeoutTime" BU_SG_REL_ ARS_CE SG_ 197 WRSRNDWhlRotStRst 250;
BA_REL_ "GenSigSuprvResp" BU_SG_REL_ EOCM_F_CE SG_ 197 WRSRNDWhlRotStRst 1;
BA_REL_ "GenSigTimeoutMsg" BU_SG_REL_ EOCM_F_CE SG_ 197 WRSRNDWhlRotStRst 197;
BA_REL_ "GenSigTimeoutTime" BU_SG_REL_ EOCM_F_CE SG_ 197 WRSRNDWhlRotStRst 120;
BA_REL_ "GenSigSuprvResp" BU_SG_REL_ HCP_T_CE SG_ 197 WRSRNDWhlDistVal 1;
BA_REL_ "GenSigTimeoutMsg" BU_SG_REL_ HCP_T_CE SG_ 197 WRSRNDWhlDistVal 197;
BA_REL_ "GenSigTimeoutTime" BU_SG_REL_ HCP_T_CE SG_ 197 WRSRNDWhlDistVal 25;
BA_REL_ "GenSigSuprvResp" BU_SG_REL_ HCP_CE SG_ 197 WRSRNDWhlDistVal 1;
BA_REL_ "GenSigTimeoutMsg" BU_SG_REL_ HCP_CE SG_ 197 WRSRNDWhlDistVal 197;
BA_REL_ "GenSigTimeoutTime" BU_SG_REL_ HCP_CE SG_ 197 WRSRNDWhlDistVal 25;
BA_REL_ "GenSigTimeoutMsg" BU_SG_REL_ RDCM_CE SG_ 197 WRSRNDWhlDistVal 197;
BA_REL_ "GenSigTimeoutTime" BU_SG_REL_ RDCM_CE SG_ 197 WRSRNDWhlDistVal 250;
BA_REL_ "GenSigSuprvResp" BU_SG_REL_ ARS_CE SG_ 197 WRSRNDWhlDistVal 1;
BA_REL_ "GenSigTimeoutMsg" BU_SG_REL_ ARS_CE SG_ 197 WRSRNDWhlDistVal 197;
BA_REL_ "GenSigTimeoutTime" BU_SG_REL_ ARS_CE SG_ 197 WRSRNDWhlDistVal 250;
BA_REL_ "GenSigSuprvResp" BU_SG_REL_ EOCM_F_CE SG_ 197 WRSRNDWhlDistVal 1;
BA_REL_ "GenSigTimeoutMsg" BU_SG_REL_ EOCM_F_CE SG_ 197 WRSRNDWhlDistVal 197;
BA_REL_ "GenSigTimeoutTime" BU_SG_REL_ EOCM_F_CE SG_ 197 WRSRNDWhlDistVal 120;
BA_REL_ "GenSigSuprvResp" BU_SG_REL_ HCP_T_CE SG_ 197 WRSRNDWhlDistTstm 1;
BA_REL_ "GenSigTimeoutMsg" BU_SG_REL_ HCP_T_CE SG_ 197 WRSRNDWhlDistTstm 197;
BA_REL_ "GenSigTimeoutTime" BU_SG_REL_ HCP_T_CE SG_ 197 WRSRNDWhlDistTstm 25;
BA_REL_ "GenSigSuprvResp" BU_SG_REL_ HCP_CE SG_ 197 WRSRNDWhlDistTstm 1;
BA_REL_ "GenSigTimeoutMsg" BU_SG_REL_ HCP_CE SG_ 197 WRSRNDWhlDistTstm 197;
BA_REL_ "GenSigTimeoutTime" BU_SG_REL_ HCP_CE SG_ 197 WRSRNDWhlDistTstm 25;
BA_REL_ "GenSigTimeoutMsg" BU_SG_REL_ RDCM_CE SG_ 197 WRSRNDWhlDistTstm 197;
BA_REL_ "GenSigTimeoutTime" BU_SG_REL_ RDCM_CE SG_ 197 WRSRNDWhlDistTstm 250;
BA_REL_ "GenSigSuprvResp" BU_SG_REL_ ARS_CE SG_ 197 WRSRNDWhlDistTstm 1;
BA_REL_ "GenSigTimeoutMsg" BU_SG_REL_ ARS_CE SG_ 197 WRSRNDWhlDistTstm 197;
BA_REL_ "GenSigTimeoutTime" BU_SG_REL_ ARS_CE SG_ 197 WRSRNDWhlDistTstm 250;
BA_REL_ "GenSigSuprvResp" BU_SG_REL_ EOCM_F_CE SG_ 197 WRSRNDWhlDistTstm 1;
BA_REL_ "GenSigTimeoutMsg" BU_SG_REL_ EOCM_F_CE SG_ 197 WRSRNDWhlDistTstm 197;
BA_REL_ "GenSigTimeoutTime" BU_SG_REL_ EOCM_F_CE SG_ 197 WRSRNDWhlDistTstm 120;
BA_REL_ "GenSigSuprvResp" BU_SG_REL_ HCP_T_CE SG_ 197 WRSRNDWhlDistPCntr 1;
BA_REL_ "GenSigTimeoutMsg" BU_SG_REL_ HCP_T_CE SG_ 197 WRSRNDWhlDistPCntr 197;
BA_REL_ "GenSigTimeoutTime" BU_SG_REL_ HCP_T_CE SG_ 197 WRSRNDWhlDistPCntr 25;
BA_REL_ "GenSigSuprvResp" BU_SG_REL_ HCP_CE SG_ 197 WRSRNDWhlDistPCntr 1;
BA_REL_ "GenSigTimeoutMsg" BU_SG_REL_ HCP_CE SG_ 197 WRSRNDWhlDistPCntr 197;
BA_REL_ "GenSigTimeoutTime" BU_SG_REL_ HCP_CE SG_ 197 WRSRNDWhlDistPCntr 25;
BA_REL_ "GenSigTimeoutMsg" BU_SG_REL_ RDCM_CE SG_ 197 WRSRNDWhlDistPCntr 197;
BA_REL_ "GenSigTimeoutTime" BU_SG_REL_ RDCM_CE SG_ 197 WRSRNDWhlDistPCntr 250;
BA_REL_ "GenSigSuprvResp" BU_SG_REL_ ARS_CE SG_ 197 WRSRNDWhlDistPCntr 1;
BA_REL_ "GenSigTimeoutMsg" BU_SG_REL_ ARS_CE SG_ 197 WRSRNDWhlDistPCntr 197;
BA_REL_ "GenSigTimeoutTime" BU_SG_REL_ ARS_CE SG_ 197 WRSRNDWhlDistPCntr 250;
BA_REL_ "GenSigSuprvResp" BU_SG_REL_ EOCM_F_CE SG_ 197 WRSRNDWhlDistPCntr 1;
BA_REL_ "GenSigTimeoutMsg" BU_SG_REL_ EOCM_F_CE SG_ 197 WRSRNDWhlDistPCntr 197;
BA_REL_ "GenSigTimeoutTime" BU_SG_REL_ EOCM_F_CE SG_ 197 WRSRNDWhlDistPCntr 120;
BA_REL_ "GenSigSuprvResp" BU_SG_REL_ HCP_T_CE SG_ 197 WRSRNDSeqNum 1;
BA_REL_ "GenSigTimeoutMsg" BU_SG_REL_ HCP_T_CE SG_ 197 WRSRNDSeqNum 197;
BA_REL_ "GenSigTimeoutTime" BU_SG_REL_ HCP_T_CE SG_ 197 WRSRNDSeqNum 25;
BA_REL_ "GenSigSuprvResp" BU_SG_REL_ HCP_CE SG_ 197 WRSRNDSeqNum 1;
BA_REL_ "GenSigTimeoutMsg" BU_SG_REL_ HCP_CE SG_ 197 WRSRNDSeqNum 197;
BA_REL_ "GenSigTimeoutTime" BU_SG_REL_ HCP_CE SG_ 197 WRSRNDSeqNum 25;
BA_REL_ "GenSigTimeoutMsg" BU_SG_REL_ RDCM_CE SG_ 197 WRSRNDSeqNum 197;
BA_REL_ "GenSigTimeoutTime" BU_SG_REL_ RDCM_CE SG_ 197 WRSRNDSeqNum 250;
BA_REL_ "GenSigSuprvResp" BU_SG_REL_ ARS_CE SG_ 197 WRSRNDSeqNum 1;
BA_REL_ "GenSigTimeoutMsg" BU_SG_REL_ ARS_CE SG_ 197 WRSRNDSeqNum 197;
BA_REL_ "GenSigTimeoutTime" BU_SG_REL_ ARS_CE SG_ 197 WRSRNDSeqNum 250;
BA_REL_ "GenSigSuprvResp" BU_SG_REL_ EOCM_F_CE SG_ 197 WRSRNDSeqNum 1;
BA_REL_ "GenSigTimeoutMsg" BU_SG_REL_ EOCM_F_CE SG_ 197 WRSRNDSeqNum 197;
BA_REL_ "GenSigTimeoutTime" BU_SG_REL_ EOCM_F_CE SG_ 197 WRSRNDSeqNum 120;
BA_REL_ "GenSigSuprvResp" BU_SG_REL_ TRCM_CE SG_ 193 WRSLDWhlDisTpRC 1;
BA_REL_ "GenSigTimeoutMsg" BU_SG_REL_ TRCM_CE SG_ 193 WRSLDWhlDisTpRC 193;
BA_REL_ "GenSigTimeoutTime" BU_SG_REL_ TRCM_CE SG_ 193 WRSLDWhlDisTpRC 250;
BA_REL_ "GenSigSuprvResp" BU_SG_REL_ HCP_T_CE SG_ 193 WRSLDWhlDisTpRC 1;
BA_REL_ "GenSigTimeoutMsg" BU_SG_REL_ HCP_T_CE SG_ 193 WRSLDWhlDisTpRC 193;
BA_REL_ "GenSigTimeoutTime" BU_SG_REL_ HCP_T_CE SG_ 193 WRSLDWhlDisTpRC 25;
BA_REL_ "GenSigSuprvResp" BU_SG_REL_ HCP_CE SG_ 193 WRSLDWhlDisTpRC 1;
BA_REL_ "GenSigTimeoutMsg" BU_SG_REL_ HCP_CE SG_ 193 WRSLDWhlDisTpRC 193;
BA_REL_ "GenSigTimeoutTime" BU_SG_REL_ HCP_CE SG_ 193 WRSLDWhlDisTpRC 25;
BA_REL_ "GenSigSuprvResp" BU_SG_REL_ RDCM_CE SG_ 193 WRSLDWhlDisTpRC 1;
BA_REL_ "GenSigTimeoutMsg" BU_SG_REL_ RDCM_CE SG_ 193 WRSLDWhlDisTpRC 193;
BA_REL_ "GenSigTimeoutTime" BU_SG_REL_ RDCM_CE SG_ 193 WRSLDWhlDisTpRC 250;
BA_REL_ "GenSigSuprvResp" BU_SG_REL_ SDM_CE SG_ 193 WRSLDWhlDisTpRC 1;
BA_REL_ "GenSigTimeoutMsg" BU_SG_REL_ SDM_CE SG_ 193 WRSLDWhlDisTpRC 193;
BA_REL_ "GenSigTimeoutTime" BU_SG_REL_ SDM_CE SG_ 193 WRSLDWhlDisTpRC 250;
BA_REL_ "GenSigSuprvResp" BU_SG_REL_ ARS_CE SG_ 193 WRSLDWhlDisTpRC 1;
BA_REL_ "GenSigTimeoutMsg" BU_SG_REL_ ARS_CE SG_ 193 WRSLDWhlDisTpRC 193;
BA_REL_ "GenSigTimeoutTime" BU_SG_REL_ ARS_CE SG_ 193 WRSLDWhlDisTpRC 250;
BA_REL_ "GenSigSuprvResp" BU_SG_REL_ EOCM_F_CE SG_ 193 WRSLDWhlDisTpRC 1;
BA_REL_ "GenSigTimeoutMsg" BU_SG_REL_ EOCM_F_CE SG_ 193 WRSLDWhlDisTpRC 193;
BA_REL_ "GenSigTimeoutTime" BU_SG_REL_ EOCM_F_CE SG_ 193 WRSLDWhlDisTpRC 120;
BA_REL_ "GenSigSuprvResp" BU_SG_REL_ TRCM_CE SG_ 193 WRSLDSeqNum 1;
BA_REL_ "GenSigTimeoutMsg" BU_SG_REL_ TRCM_CE SG_ 193 WRSLDSeqNum 193;
BA_REL_ "GenSigTimeoutTime" BU_SG_REL_ TRCM_CE SG_ 193 WRSLDSeqNum 250;
BA_REL_ "GenSigSuprvResp" BU_SG_REL_ HCP_T_CE SG_ 193 WRSLDSeqNum 1;
BA_REL_ "GenSigTimeoutMsg" BU_SG_REL_ HCP_T_CE SG_ 193 WRSLDSeqNum 193;
BA_REL_ "GenSigTimeoutTime" BU_SG_REL_ HCP_T_CE SG_ 193 WRSLDSeqNum 25;
BA_REL_ "GenSigSuprvResp" BU_SG_REL_ HCP_CE SG_ 193 WRSLDSeqNum 1;
BA_REL_ "GenSigTimeoutMsg" BU_SG_REL_ HCP_CE SG_ 193 WRSLDSeqNum 193;
BA_REL_ "GenSigTimeoutTime" BU_SG_REL_ HCP_CE SG_ 193 WRSLDSeqNum 25;
BA_REL_ "GenSigSuprvResp" BU_SG_REL_ RDCM_CE SG_ 193 WRSLDSeqNum 1;
BA_REL_ "GenSigTimeoutMsg" BU_SG_REL_ RDCM_CE SG_ 193 WRSLDSeqNum 193;
BA_REL_ "GenSigTimeoutTime" BU_SG_REL_ RDCM_CE SG_ 193 WRSLDSeqNum 250;
BA_REL_ "GenSigSuprvResp" BU_SG_REL_ SDM_CE SG_ 193 WRSLDSeqNum 1;
BA_REL_ "GenSigTimeoutMsg" BU_SG_REL_ SDM_CE SG_ 193 WRSLDSeqNum 193;
BA_REL_ "GenSigTimeoutTime" BU_SG_REL_ SDM_CE SG_ 193 WRSLDSeqNum 250;
BA_REL_ "GenSigSuprvResp" BU_SG_REL_ ARS_CE SG_ 193 WRSLDSeqNum 1;
BA_REL_ "GenSigTimeoutMsg" BU_SG_REL_ ARS_CE SG_ 193 WRSLDSeqNum 193;
BA_REL_ "GenSigTimeoutTime" BU_SG_REL_ ARS_CE SG_ 193 WRSLDSeqNum 250;
BA_REL_ "GenSigSuprvResp" BU_SG_REL_ EOCM_F_CE SG_ 193 WRSLDSeqNum 1;
BA_REL_ "GenSigTimeoutMsg" BU_SG_REL_ EOCM_F_CE SG_ 193 WRSLDSeqNum 193;
BA_REL_ "GenSigTimeoutTime" BU_SG_REL_ EOCM_F_CE SG_ 193 WRSLDSeqNum 120;
BA_REL_ "GenSigSuprvResp" BU_SG_REL_ TRCM_CE SG_ 193 WRSLDWhlDistVal 1;
BA_REL_ "GenSigTimeoutMsg" BU_SG_REL_ TRCM_CE SG_ 193 WRSLDWhlDistVal 193;
BA_REL_ "GenSigTimeoutTime" BU_SG_REL_ TRCM_CE SG_ 193 WRSLDWhlDistVal 250;
BA_REL_ "GenSigSuprvResp" BU_SG_REL_ HCP_T_CE SG_ 193 WRSLDWhlDistVal 1;
BA_REL_ "GenSigTimeoutMsg" BU_SG_REL_ HCP_T_CE SG_ 193 WRSLDWhlDistVal 193;
BA_REL_ "GenSigTimeoutTime" BU_SG_REL_ HCP_T_CE SG_ 193 WRSLDWhlDistVal 25;
BA_REL_ "GenSigSuprvResp" BU_SG_REL_ HCP_CE SG_ 193 WRSLDWhlDistVal 1;
BA_REL_ "GenSigTimeoutMsg" BU_SG_REL_ HCP_CE SG_ 193 WRSLDWhlDistVal 193;
BA_REL_ "GenSigTimeoutTime" BU_SG_REL_ HCP_CE SG_ 193 WRSLDWhlDistVal 25;
BA_REL_ "GenSigSuprvResp" BU_SG_REL_ RDCM_CE SG_ 193 WRSLDWhlDistVal 1;
BA_REL_ "GenSigTimeoutMsg" BU_SG_REL_ RDCM_CE SG_ 193 WRSLDWhlDistVal 193;
BA_REL_ "GenSigTimeoutTime" BU_SG_REL_ RDCM_CE SG_ 193 WRSLDWhlDistVal 250;
BA_REL_ "GenSigSuprvResp" BU_SG_REL_ SDM_CE SG_ 193 WRSLDWhlDistVal 1;
BA_REL_ "GenSigTimeoutMsg" BU_SG_REL_ SDM_CE SG_ 193 WRSLDWhlDistVal 193;
BA_REL_ "GenSigTimeoutTime" BU_SG_REL_ SDM_CE SG_ 193 WRSLDWhlDistVal 250;
BA_REL_ "GenSigSuprvResp" BU_SG_REL_ ARS_CE SG_ 193 WRSLDWhlDistVal 1;
BA_REL_ "GenSigTimeoutMsg" BU_SG_REL_ ARS_CE SG_ 193 WRSLDWhlDistVal 193;
BA_REL_ "GenSigTimeoutTime" BU_SG_REL_ ARS_CE SG_ 193 WRSLDWhlDistVal 250;
BA_REL_ "GenSigSuprvResp" BU_SG_REL_ EOCM_F_CE SG_ 193 WRSLDWhlDistVal 1;
BA_REL_ "GenSigTimeoutMsg" BU_SG_REL_ EOCM_F_CE SG_ 193 WRSLDWhlDistVal 193;
BA_REL_ "GenSigTimeoutTime" BU_SG_REL_ EOCM_F_CE SG_ 193 WRSLDWhlDistVal 120;
BA_REL_ "GenSigSuprvResp" BU_SG_REL_ TRCM_CE SG_ 193 WRSLDWhlRotStatRst 1;
BA_REL_ "GenSigTimeoutMsg" BU_SG_REL_ TRCM_CE SG_ 193 WRSLDWhlRotStatRst 193;
BA_REL_ "GenSigTimeoutTime" BU_SG_REL_ TRCM_CE SG_ 193 WRSLDWhlRotStatRst 250;
BA_REL_ "GenSigSuprvResp" BU_SG_REL_ HCP_T_CE SG_ 193 WRSLDWhlRotStatRst 1;
BA_REL_ "GenSigTimeoutMsg" BU_SG_REL_ HCP_T_CE SG_ 193 WRSLDWhlRotStatRst 193;
BA_REL_ "GenSigTimeoutTime" BU_SG_REL_ HCP_T_CE SG_ 193 WRSLDWhlRotStatRst 25;
BA_REL_ "GenSigSuprvResp" BU_SG_REL_ HCP_CE SG_ 193 WRSLDWhlRotStatRst 1;
BA_REL_ "GenSigTimeoutMsg" BU_SG_REL_ HCP_CE SG_ 193 WRSLDWhlRotStatRst 193;
BA_REL_ "GenSigTimeoutTime" BU_SG_REL_ HCP_CE SG_ 193 WRSLDWhlRotStatRst 25;
BA_REL_ "GenSigSuprvResp" BU_SG_REL_ RDCM_CE SG_ 193 WRSLDWhlRotStatRst 1;
BA_REL_ "GenSigTimeoutMsg" BU_SG_REL_ RDCM_CE SG_ 193 WRSLDWhlRotStatRst 193;
BA_REL_ "GenSigTimeoutTime" BU_SG_REL_ RDCM_CE SG_ 193 WRSLDWhlRotStatRst 250;
BA_REL_ "GenSigSuprvResp" BU_SG_REL_ SDM_CE SG_ 193 WRSLDWhlRotStatRst 1;
BA_REL_ "GenSigTimeoutMsg" BU_SG_REL_ SDM_CE SG_ 193 WRSLDWhlRotStatRst 193;
BA_REL_ "GenSigTimeoutTime" BU_SG_REL_ SDM_CE SG_ 193 WRSLDWhlRotStatRst 250;
BA_REL_ "GenSigSuprvResp" BU_SG_REL_ ARS_CE SG_ 193 WRSLDWhlRotStatRst 1;
BA_REL_ "GenSigTimeoutMsg" BU_SG_REL_ ARS_CE SG_ 193 WRSLDWhlRotStatRst 193;
BA_REL_ "GenSigTimeoutTime" BU_SG_REL_ ARS_CE SG_ 193 WRSLDWhlRotStatRst 250;
BA_REL_ "GenSigSuprvResp" BU_SG_REL_ EOCM_F_CE SG_ 193 WRSLDWhlRotStatRst 1;
BA_REL_ "GenSigTimeoutMsg" BU_SG_REL_ EOCM_F_CE SG_ 193 WRSLDWhlRotStatRst 193;
BA_REL_ "GenSigTimeoutTime" BU_SG_REL_ EOCM_F_CE SG_ 193 WRSLDWhlRotStatRst 120;
BA_REL_ "GenSigSuprvResp" BU_SG_REL_ TRCM_CE SG_ 193 WRSLDWhlDistTmstm 1;
BA_REL_ "GenSigTimeoutMsg" BU_SG_REL_ TRCM_CE SG_ 193 WRSLDWhlDistTmstm 193;
BA_REL_ "GenSigTimeoutTime" BU_SG_REL_ TRCM_CE SG_ 193 WRSLDWhlDistTmstm 250;
BA_REL_ "GenSigSuprvResp" BU_SG_REL_ HCP_T_CE SG_ 193 WRSLDWhlDistTmstm 1;
BA_REL_ "GenSigTimeoutMsg" BU_SG_REL_ HCP_T_CE SG_ 193 WRSLDWhlDistTmstm 193;
BA_REL_ "GenSigTimeoutTime" BU_SG_REL_ HCP_T_CE SG_ 193 WRSLDWhlDistTmstm 25;
BA_REL_ "GenSigSuprvResp" BU_SG_REL_ HCP_CE SG_ 193 WRSLDWhlDistTmstm 1;
BA_REL_ "GenSigTimeoutMsg" BU_SG_REL_ HCP_CE SG_ 193 WRSLDWhlDistTmstm 193;
BA_REL_ "GenSigTimeoutTime" BU_SG_REL_ HCP_CE SG_ 193 WRSLDWhlDistTmstm 25;
BA_REL_ "GenSigSuprvResp" BU_SG_REL_ RDCM_CE SG_ 193 WRSLDWhlDistTmstm 1;
BA_REL_ "GenSigTimeoutMsg" BU_SG_REL_ RDCM_CE SG_ 193 WRSLDWhlDistTmstm 193;
BA_REL_ "GenSigTimeoutTime" BU_SG_REL_ RDCM_CE SG_ 193 WRSLDWhlDistTmstm 250;
BA_REL_ "GenSigSuprvResp" BU_SG_REL_ SDM_CE SG_ 193 WRSLDWhlDistTmstm 1;
BA_REL_ "GenSigTimeoutMsg" BU_SG_REL_ SDM_CE SG_ 193 WRSLDWhlDistTmstm 193;
BA_REL_ "GenSigTimeoutTime" BU_SG_REL_ SDM_CE SG_ 193 WRSLDWhlDistTmstm 250;
BA_REL_ "GenSigSuprvResp" BU_SG_REL_ ARS_CE SG_ 193 WRSLDWhlDistTmstm 1;
BA_REL_ "GenSigTimeoutMsg" BU_SG_REL_ ARS_CE SG_ 193 WRSLDWhlDistTmstm 193;
BA_REL_ "GenSigTimeoutTime" BU_SG_REL_ ARS_CE SG_ 193 WRSLDWhlDistTmstm 250;
BA_REL_ "GenSigSuprvResp" BU_SG_REL_ EOCM_F_CE SG_ 193 WRSLDWhlDistTmstm 1;
BA_REL_ "GenSigTimeoutMsg" BU_SG_REL_ EOCM_F_CE SG_ 193 WRSLDWhlDistTmstm 193;
BA_REL_ "GenSigTimeoutTime" BU_SG_REL_ EOCM_F_CE SG_ 193 WRSLDWhlDistTmstm 120;
BA_REL_ "GenSigSuprvResp" BU_SG_REL_ TRCM_CE SG_ 193 WRSLDWhlDistPlsCntr 1;
BA_REL_ "GenSigTimeoutMsg" BU_SG_REL_ TRCM_CE SG_ 193 WRSLDWhlDistPlsCntr 193;
BA_REL_ "GenSigTimeoutTime" BU_SG_REL_ TRCM_CE SG_ 193 WRSLDWhlDistPlsCntr 250;
BA_REL_ "GenSigSuprvResp" BU_SG_REL_ HCP_T_CE SG_ 193 WRSLDWhlDistPlsCntr 1;
BA_REL_ "GenSigTimeoutMsg" BU_SG_REL_ HCP_T_CE SG_ 193 WRSLDWhlDistPlsCntr 193;
BA_REL_ "GenSigTimeoutTime" BU_SG_REL_ HCP_T_CE SG_ 193 WRSLDWhlDistPlsCntr 25;
BA_REL_ "GenSigSuprvResp" BU_SG_REL_ HCP_CE SG_ 193 WRSLDWhlDistPlsCntr 1;
BA_REL_ "GenSigTimeoutMsg" BU_SG_REL_ HCP_CE SG_ 193 WRSLDWhlDistPlsCntr 193;
BA_REL_ "GenSigTimeoutTime" BU_SG_REL_ HCP_CE SG_ 193 WRSLDWhlDistPlsCntr 25;
BA_REL_ "GenSigSuprvResp" BU_SG_REL_ RDCM_CE SG_ 193 WRSLDWhlDistPlsCntr 1;
BA_REL_ "GenSigTimeoutMsg" BU_SG_REL_ RDCM_CE SG_ 193 WRSLDWhlDistPlsCntr 193;
BA_REL_ "GenSigTimeoutTime" BU_SG_REL_ RDCM_CE SG_ 193 WRSLDWhlDistPlsCntr 250;
BA_REL_ "GenSigSuprvResp" BU_SG_REL_ SDM_CE SG_ 193 WRSLDWhlDistPlsCntr 1;
BA_REL_ "GenSigTimeoutMsg" BU_SG_REL_ SDM_CE SG_ 193 WRSLDWhlDistPlsCntr 193;
BA_REL_ "GenSigTimeoutTime" BU_SG_REL_ SDM_CE SG_ 193 WRSLDWhlDistPlsCntr 250;
BA_REL_ "GenSigSuprvResp" BU_SG_REL_ ARS_CE SG_ 193 WRSLDWhlDistPlsCntr 1;
BA_REL_ "GenSigTimeoutMsg" BU_SG_REL_ ARS_CE SG_ 193 WRSLDWhlDistPlsCntr 193;
BA_REL_ "GenSigTimeoutTime" BU_SG_REL_ ARS_CE SG_ 193 WRSLDWhlDistPlsCntr 250;
BA_REL_ "GenSigSuprvResp" BU_SG_REL_ EOCM_F_CE SG_ 193 WRSLDWhlDistPlsCntr 1;
BA_REL_ "GenSigTimeoutMsg" BU_SG_REL_ EOCM_F_CE SG_ 193 WRSLDWhlDistPlsCntr 193;
BA_REL_ "GenSigTimeoutTime" BU_SG_REL_ EOCM_F_CE SG_ 193 WRSLDWhlDistPlsCntr 120;
BA_REL_ "GenSigSuprvResp" BU_SG_REL_ TRCM_CE SG_ 193 WRSRDWhlDisTpRC 1;
BA_REL_ "GenSigTimeoutMsg" BU_SG_REL_ TRCM_CE SG_ 193 WRSRDWhlDisTpRC 193;
BA_REL_ "GenSigTimeoutTime" BU_SG_REL_ TRCM_CE SG_ 193 WRSRDWhlDisTpRC 250;
BA_REL_ "GenSigSuprvResp" BU_SG_REL_ HCP_T_CE SG_ 193 WRSRDWhlDisTpRC 1;
BA_REL_ "GenSigTimeoutMsg" BU_SG_REL_ HCP_T_CE SG_ 193 WRSRDWhlDisTpRC 193;
BA_REL_ "GenSigTimeoutTime" BU_SG_REL_ HCP_T_CE SG_ 193 WRSRDWhlDisTpRC 25;
BA_REL_ "GenSigSuprvResp" BU_SG_REL_ HCP_CE SG_ 193 WRSRDWhlDisTpRC 1;
BA_REL_ "GenSigTimeoutMsg" BU_SG_REL_ HCP_CE SG_ 193 WRSRDWhlDisTpRC 193;
BA_REL_ "GenSigTimeoutTime" BU_SG_REL_ HCP_CE SG_ 193 WRSRDWhlDisTpRC 25;
BA_REL_ "GenSigSuprvResp" BU_SG_REL_ RDCM_CE SG_ 193 WRSRDWhlDisTpRC 1;
BA_REL_ "GenSigTimeoutMsg" BU_SG_REL_ RDCM_CE SG_ 193 WRSRDWhlDisTpRC 193;
BA_REL_ "GenSigTimeoutTime" BU_SG_REL_ RDCM_CE SG_ 193 WRSRDWhlDisTpRC 250;
BA_REL_ "GenSigSuprvResp" BU_SG_REL_ SDM_CE SG_ 193 WRSRDWhlDisTpRC 1;
BA_REL_ "GenSigTimeoutMsg" BU_SG_REL_ SDM_CE SG_ 193 WRSRDWhlDisTpRC 193;
BA_REL_ "GenSigTimeoutTime" BU_SG_REL_ SDM_CE SG_ 193 WRSRDWhlDisTpRC 250;
BA_REL_ "GenSigSuprvResp" BU_SG_REL_ ARS_CE SG_ 193 WRSRDWhlDisTpRC 1;
BA_REL_ "GenSigTimeoutMsg" BU_SG_REL_ ARS_CE SG_ 193 WRSRDWhlDisTpRC 193;
BA_REL_ "GenSigTimeoutTime" BU_SG_REL_ ARS_CE SG_ 193 WRSRDWhlDisTpRC 250;
BA_REL_ "GenSigSuprvResp" BU_SG_REL_ EOCM_F_CE SG_ 193 WRSRDWhlDisTpRC 1;
BA_REL_ "GenSigTimeoutMsg" BU_SG_REL_ EOCM_F_CE SG_ 193 WRSRDWhlDisTpRC 193;
BA_REL_ "GenSigTimeoutTime" BU_SG_REL_ EOCM_F_CE SG_ 193 WRSRDWhlDisTpRC 120;
BA_REL_ "GenSigSuprvResp" BU_SG_REL_ TRCM_CE SG_ 193 WRSRDSeqNum 1;
BA_REL_ "GenSigTimeoutMsg" BU_SG_REL_ TRCM_CE SG_ 193 WRSRDSeqNum 193;
BA_REL_ "GenSigTimeoutTime" BU_SG_REL_ TRCM_CE SG_ 193 WRSRDSeqNum 250;
BA_REL_ "GenSigSuprvResp" BU_SG_REL_ HCP_T_CE SG_ 193 WRSRDSeqNum 1;
BA_REL_ "GenSigTimeoutMsg" BU_SG_REL_ HCP_T_CE SG_ 193 WRSRDSeqNum 193;
BA_REL_ "GenSigTimeoutTime" BU_SG_REL_ HCP_T_CE SG_ 193 WRSRDSeqNum 25;
BA_REL_ "GenSigSuprvResp" BU_SG_REL_ HCP_CE SG_ 193 WRSRDSeqNum 1;
BA_REL_ "GenSigTimeoutMsg" BU_SG_REL_ HCP_CE SG_ 193 WRSRDSeqNum 193;
BA_REL_ "GenSigTimeoutTime" BU_SG_REL_ HCP_CE SG_ 193 WRSRDSeqNum 25;
BA_REL_ "GenSigSuprvResp" BU_SG_REL_ RDCM_CE SG_ 193 WRSRDSeqNum 1;
BA_REL_ "GenSigTimeoutMsg" BU_SG_REL_ RDCM_CE SG_ 193 WRSRDSeqNum 193;
BA_REL_ "GenSigTimeoutTime" BU_SG_REL_ RDCM_CE SG_ 193 WRSRDSeqNum 250;
BA_REL_ "GenSigSuprvResp" BU_SG_REL_ SDM_CE SG_ 193 WRSRDSeqNum 1;
BA_REL_ "GenSigTimeoutMsg" BU_SG_REL_ SDM_CE SG_ 193 WRSRDSeqNum 193;
BA_REL_ "GenSigTimeoutTime" BU_SG_REL_ SDM_CE SG_ 193 WRSRDSeqNum 250;
BA_REL_ "GenSigSuprvResp" BU_SG_REL_ ARS_CE SG_ 193 WRSRDSeqNum 1;
BA_REL_ "GenSigTimeoutMsg" BU_SG_REL_ ARS_CE SG_ 193 WRSRDSeqNum 193;
BA_REL_ "GenSigTimeoutTime" BU_SG_REL_ ARS_CE SG_ 193 WRSRDSeqNum 250;
BA_REL_ "GenSigSuprvResp" BU_SG_REL_ EOCM_F_CE SG_ 193 WRSRDSeqNum 1;
BA_REL_ "GenSigTimeoutMsg" BU_SG_REL_ EOCM_F_CE SG_ 193 WRSRDSeqNum 193;
BA_REL_ "GenSigTimeoutTime" BU_SG_REL_ EOCM_F_CE SG_ 193 WRSRDSeqNum 120;
BA_REL_ "GenSigSuprvResp" BU_SG_REL_ TRCM_CE SG_ 193 WRSRDWhlRotStatRst 1;
BA_REL_ "GenSigTimeoutMsg" BU_SG_REL_ TRCM_CE SG_ 193 WRSRDWhlRotStatRst 193;
BA_REL_ "GenSigTimeoutTime" BU_SG_REL_ TRCM_CE SG_ 193 WRSRDWhlRotStatRst 250;
BA_REL_ "GenSigSuprvResp" BU_SG_REL_ HCP_T_CE SG_ 193 WRSRDWhlRotStatRst 1;
BA_REL_ "GenSigTimeoutMsg" BU_SG_REL_ HCP_T_CE SG_ 193 WRSRDWhlRotStatRst 193;
BA_REL_ "GenSigTimeoutTime" BU_SG_REL_ HCP_T_CE SG_ 193 WRSRDWhlRotStatRst 25;
BA_REL_ "GenSigSuprvResp" BU_SG_REL_ HCP_CE SG_ 193 WRSRDWhlRotStatRst 1;
BA_REL_ "GenSigTimeoutMsg" BU_SG_REL_ HCP_CE SG_ 193 WRSRDWhlRotStatRst 193;
BA_REL_ "GenSigTimeoutTime" BU_SG_REL_ HCP_CE SG_ 193 WRSRDWhlRotStatRst 25;
BA_REL_ "GenSigSuprvResp" BU_SG_REL_ RDCM_CE SG_ 193 WRSRDWhlRotStatRst 1;
BA_REL_ "GenSigTimeoutMsg" BU_SG_REL_ RDCM_CE SG_ 193 WRSRDWhlRotStatRst 193;
BA_REL_ "GenSigTimeoutTime" BU_SG_REL_ RDCM_CE SG_ 193 WRSRDWhlRotStatRst 250;
BA_REL_ "GenSigSuprvResp" BU_SG_REL_ SDM_CE SG_ 193 WRSRDWhlRotStatRst 1;
BA_REL_ "GenSigTimeoutMsg" BU_SG_REL_ SDM_CE SG_ 193 WRSRDWhlRotStatRst 193;
BA_REL_ "GenSigTimeoutTime" BU_SG_REL_ SDM_CE SG_ 193 WRSRDWhlRotStatRst 250;
BA_REL_ "GenSigSuprvResp" BU_SG_REL_ ARS_CE SG_ 193 WRSRDWhlRotStatRst 1;
BA_REL_ "GenSigTimeoutMsg" BU_SG_REL_ ARS_CE SG_ 193 WRSRDWhlRotStatRst 193;
BA_REL_ "GenSigTimeoutTime" BU_SG_REL_ ARS_CE SG_ 193 WRSRDWhlRotStatRst 250;
BA_REL_ "GenSigSuprvResp" BU_SG_REL_ EOCM_F_CE SG_ 193 WRSRDWhlRotStatRst 1;
BA_REL_ "GenSigTimeoutMsg" BU_SG_REL_ EOCM_F_CE SG_ 193 WRSRDWhlRotStatRst 193;
BA_REL_ "GenSigTimeoutTime" BU_SG_REL_ EOCM_F_CE SG_ 193 WRSRDWhlRotStatRst 120;
BA_REL_ "GenSigSuprvResp" BU_SG_REL_ TRCM_CE SG_ 193 WRSRDWhlDistVal 1;
BA_REL_ "GenSigTimeoutMsg" BU_SG_REL_ TRCM_CE SG_ 193 WRSRDWhlDistVal 193;
BA_REL_ "GenSigTimeoutTime" BU_SG_REL_ TRCM_CE SG_ 193 WRSRDWhlDistVal 250;
BA_REL_ "GenSigSuprvResp" BU_SG_REL_ HCP_T_CE SG_ 193 WRSRDWhlDistVal 1;
BA_REL_ "GenSigTimeoutMsg" BU_SG_REL_ HCP_T_CE SG_ 193 WRSRDWhlDistVal 193;
BA_REL_ "GenSigTimeoutTime" BU_SG_REL_ HCP_T_CE SG_ 193 WRSRDWhlDistVal 25;
BA_REL_ "GenSigSuprvResp" BU_SG_REL_ HCP_CE SG_ 193 WRSRDWhlDistVal 1;
BA_REL_ "GenSigTimeoutMsg" BU_SG_REL_ HCP_CE SG_ 193 WRSRDWhlDistVal 193;
BA_REL_ "GenSigTimeoutTime" BU_SG_REL_ HCP_CE SG_ 193 WRSRDWhlDistVal 25;
BA_REL_ "GenSigSuprvResp" BU_SG_REL_ RDCM_CE SG_ 193 WRSRDWhlDistVal 1;
BA_REL_ "GenSigTimeoutMsg" BU_SG_REL_ RDCM_CE SG_ 193 WRSRDWhlDistVal 193;
BA_REL_ "GenSigTimeoutTime" BU_SG_REL_ RDCM_CE SG_ 193 WRSRDWhlDistVal 250;
BA_REL_ "GenSigSuprvResp" BU_SG_REL_ SDM_CE SG_ 193 WRSRDWhlDistVal 1;
BA_REL_ "GenSigTimeoutMsg" BU_SG_REL_ SDM_CE SG_ 193 WRSRDWhlDistVal 193;
BA_REL_ "GenSigTimeoutTime" BU_SG_REL_ SDM_CE SG_ 193 WRSRDWhlDistVal 250;
BA_REL_ "GenSigSuprvResp" BU_SG_REL_ ARS_CE SG_ 193 WRSRDWhlDistVal 1;
BA_REL_ "GenSigTimeoutMsg" BU_SG_REL_ ARS_CE SG_ 193 WRSRDWhlDistVal 193;
BA_REL_ "GenSigTimeoutTime" BU_SG_REL_ ARS_CE SG_ 193 WRSRDWhlDistVal 250;
BA_REL_ "GenSigSuprvResp" BU_SG_REL_ EOCM_F_CE SG_ 193 WRSRDWhlDistVal 1;
BA_REL_ "GenSigTimeoutMsg" BU_SG_REL_ EOCM_F_CE SG_ 193 WRSRDWhlDistVal 193;
BA_REL_ "GenSigTimeoutTime" BU_SG_REL_ EOCM_F_CE SG_ 193 WRSRDWhlDistVal 120;
BA_REL_ "GenSigSuprvResp" BU_SG_REL_ TRCM_CE SG_ 193 WRSRDWhlDistTmstm 1;
BA_REL_ "GenSigTimeoutMsg" BU_SG_REL_ TRCM_CE SG_ 193 WRSRDWhlDistTmstm 193;
BA_REL_ "GenSigTimeoutTime" BU_SG_REL_ TRCM_CE SG_ 193 WRSRDWhlDistTmstm 250;
BA_REL_ "GenSigSuprvResp" BU_SG_REL_ HCP_T_CE SG_ 193 WRSRDWhlDistTmstm 1;
BA_REL_ "GenSigTimeoutMsg" BU_SG_REL_ HCP_T_CE SG_ 193 WRSRDWhlDistTmstm 193;
BA_REL_ "GenSigTimeoutTime" BU_SG_REL_ HCP_T_CE SG_ 193 WRSRDWhlDistTmstm 25;
BA_REL_ "GenSigSuprvResp" BU_SG_REL_ HCP_CE SG_ 193 WRSRDWhlDistTmstm 1;
BA_REL_ "GenSigTimeoutMsg" BU_SG_REL_ HCP_CE SG_ 193 WRSRDWhlDistTmstm 193;
BA_REL_ "GenSigTimeoutTime" BU_SG_REL_ HCP_CE SG_ 193 WRSRDWhlDistTmstm 25;
BA_REL_ "GenSigSuprvResp" BU_SG_REL_ RDCM_CE SG_ 193 WRSRDWhlDistTmstm 1;
BA_REL_ "GenSigTimeoutMsg" BU_SG_REL_ RDCM_CE SG_ 193 WRSRDWhlDistTmstm 193;
BA_REL_ "GenSigTimeoutTime" BU_SG_REL_ RDCM_CE SG_ 193 WRSRDWhlDistTmstm 250;
BA_REL_ "GenSigSuprvResp" BU_SG_REL_ SDM_CE SG_ 193 WRSRDWhlDistTmstm 1;
BA_REL_ "GenSigTimeoutMsg" BU_SG_REL_ SDM_CE SG_ 193 WRSRDWhlDistTmstm 193;
BA_REL_ "GenSigTimeoutTime" BU_SG_REL_ SDM_CE SG_ 193 WRSRDWhlDistTmstm 250;
BA_REL_ "GenSigSuprvResp" BU_SG_REL_ ARS_CE SG_ 193 WRSRDWhlDistTmstm 1;
BA_REL_ "GenSigTimeoutMsg" BU_SG_REL_ ARS_CE SG_ 193 WRSRDWhlDistTmstm 193;
BA_REL_ "GenSigTimeoutTime" BU_SG_REL_ ARS_CE SG_ 193 WRSRDWhlDistTmstm 250;
BA_REL_ "GenSigSuprvResp" BU_SG_REL_ EOCM_F_CE SG_ 193 WRSRDWhlDistTmstm 1;
BA_REL_ "GenSigTimeoutMsg" BU_SG_REL_ EOCM_F_CE SG_ 193 WRSRDWhlDistTmstm 193;
BA_REL_ "GenSigTimeoutTime" BU_SG_REL_ EOCM_F_CE SG_ 193 WRSRDWhlDistTmstm 120;
BA_REL_ "GenSigSuprvResp" BU_SG_REL_ TRCM_CE SG_ 193 WRSRDWhlDistPlsCntr 1;
BA_REL_ "GenSigTimeoutMsg" BU_SG_REL_ TRCM_CE SG_ 193 WRSRDWhlDistPlsCntr 193;
BA_REL_ "GenSigTimeoutTime" BU_SG_REL_ TRCM_CE SG_ 193 WRSRDWhlDistPlsCntr 250;
BA_REL_ "GenSigSuprvResp" BU_SG_REL_ HCP_T_CE SG_ 193 WRSRDWhlDistPlsCntr 1;
BA_REL_ "GenSigTimeoutMsg" BU_SG_REL_ HCP_T_CE SG_ 193 WRSRDWhlDistPlsCntr 193;
BA_REL_ "GenSigTimeoutTime" BU_SG_REL_ HCP_T_CE SG_ 193 WRSRDWhlDistPlsCntr 25;
BA_REL_ "GenSigSuprvResp" BU_SG_REL_ HCP_CE SG_ 193 WRSRDWhlDistPlsCntr 1;
BA_REL_ "GenSigTimeoutMsg" BU_SG_REL_ HCP_CE SG_ 193 WRSRDWhlDistPlsCntr 193;
BA_REL_ "GenSigTimeoutTime" BU_SG_REL_ HCP_CE SG_ 193 WRSRDWhlDistPlsCntr 25;
BA_REL_ "GenSigSuprvResp" BU_SG_REL_ RDCM_CE SG_ 193 WRSRDWhlDistPlsCntr 1;
BA_REL_ "GenSigTimeoutMsg" BU_SG_REL_ RDCM_CE SG_ 193 WRSRDWhlDistPlsCntr 193;
BA_REL_ "GenSigTimeoutTime" BU_SG_REL_ RDCM_CE SG_ 193 WRSRDWhlDistPlsCntr 250;
BA_REL_ "GenSigSuprvResp" BU_SG_REL_ SDM_CE SG_ 193 WRSRDWhlDistPlsCntr 1;
BA_REL_ "GenSigTimeoutMsg" BU_SG_REL_ SDM_CE SG_ 193 WRSRDWhlDistPlsCntr 193;
BA_REL_ "GenSigTimeoutTime" BU_SG_REL_ SDM_CE SG_ 193 WRSRDWhlDistPlsCntr 250;
BA_REL_ "GenSigSuprvResp" BU_SG_REL_ ARS_CE SG_ 193 WRSRDWhlDistPlsCntr 1;
BA_REL_ "GenSigTimeoutMsg" BU_SG_REL_ ARS_CE SG_ 193 WRSRDWhlDistPlsCntr 193;
BA_REL_ "GenSigTimeoutTime" BU_SG_REL_ ARS_CE SG_ 193 WRSRDWhlDistPlsCntr 250;
BA_REL_ "GenSigSuprvResp" BU_SG_REL_ EOCM_F_CE SG_ 193 WRSRDWhlDistPlsCntr 1;
BA_REL_ "GenSigTimeoutMsg" BU_SG_REL_ EOCM_F_CE SG_ 193 WRSRDWhlDistPlsCntr 193;
BA_REL_ "GenSigTimeoutTime" BU_SG_REL_ EOCM_F_CE SG_ 193 WRSRDWhlDistPlsCntr 120;
BA_REL_ "GenSigSuprvResp" BU_SG_REL_ EPS_JR_CE SG_ 823 StrWhlTctlFdbkReqActProtVal 1;
BA_REL_ "GenSigTimeoutMsg" BU_SG_REL_ EPS_JR_CE SG_ 823 StrWhlTctlFdbkReqActProtVal 823;
BA_REL_ "GenSigTimeoutTime" BU_SG_REL_ EPS_JR_CE SG_ 823 StrWhlTctlFdbkReqActProtVal 250;
BA_REL_ "GenSigSuprvResp" BU_SG_REL_ EPS_CE SG_ 823 StrWhlTctlFdbkReqActProtVal 1;
BA_REL_ "GenSigTimeoutMsg" BU_SG_REL_ EPS_CE SG_ 823 StrWhlTctlFdbkReqActProtVal 823;
BA_REL_ "GenSigTimeoutTime" BU_SG_REL_ EPS_CE SG_ 823 StrWhlTctlFdbkReqActProtVal 250;
BA_REL_ "GenSigSuprvResp" BU_SG_REL_ EPS_JR_CE SG_ 823 StrWhlAngReqPrtVal 1;
BA_REL_ "GenSigTimeoutMsg" BU_SG_REL_ EPS_JR_CE SG_ 823 StrWhlAngReqPrtVal 823;
BA_REL_ "GenSigTimeoutTime" BU_SG_REL_ EPS_JR_CE SG_ 823 StrWhlAngReqPrtVal 250;
BA_REL_ "GenSigSuprvResp" BU_SG_REL_ EPS_CE SG_ 823 StrWhlAngReqPrtVal 1;
BA_REL_ "GenSigTimeoutMsg" BU_SG_REL_ EPS_CE SG_ 823 StrWhlAngReqPrtVal 823;
BA_REL_ "GenSigTimeoutTime" BU_SG_REL_ EPS_CE SG_ 823 StrWhlAngReqPrtVal 250;
BA_REL_ "GenSigSuprvResp" BU_SG_REL_ EPS_JR_CE SG_ 823 StrWhlAngReqARC 1;
BA_REL_ "GenSigTimeoutMsg" BU_SG_REL_ EPS_JR_CE SG_ 823 StrWhlAngReqARC 823;
BA_REL_ "GenSigTimeoutTime" BU_SG_REL_ EPS_JR_CE SG_ 823 StrWhlAngReqARC 250;
BA_REL_ "GenSigSuprvResp" BU_SG_REL_ EPS_CE SG_ 823 StrWhlAngReqARC 1;
BA_REL_ "GenSigTimeoutMsg" BU_SG_REL_ EPS_CE SG_ 823 StrWhlAngReqARC 823;
BA_REL_ "GenSigTimeoutTime" BU_SG_REL_ EPS_CE SG_ 823 StrWhlAngReqARC 250;
BA_REL_ "GenSigSuprvResp" BU_SG_REL_ EPS_JR_CE SG_ 823 SWAR_TrgtAng 1;
BA_REL_ "GenSigTimeoutMsg" BU_SG_REL_ EPS_JR_CE SG_ 823 SWAR_TrgtAng 823;
BA_REL_ "GenSigTimeoutTime" BU_SG_REL_ EPS_JR_CE SG_ 823 SWAR_TrgtAng 250;
BA_REL_ "GenSigSuprvResp" BU_SG_REL_ EPS_CE SG_ 823 SWAR_TrgtAng 1;
BA_REL_ "GenSigTimeoutMsg" BU_SG_REL_ EPS_CE SG_ 823 SWAR_TrgtAng 823;
BA_REL_ "GenSigTimeoutTime" BU_SG_REL_ EPS_CE SG_ 823 SWAR_TrgtAng 250;
BA_REL_ "GenSigSuprvResp" BU_SG_REL_ EPS_JR_CE SG_ 823 SWAR_ReqActV 1;
BA_REL_ "GenSigTimeoutMsg" BU_SG_REL_ EPS_JR_CE SG_ 823 SWAR_ReqActV 823;
BA_REL_ "GenSigTimeoutTime" BU_SG_REL_ EPS_JR_CE SG_ 823 SWAR_ReqActV 250;
BA_REL_ "GenSigSuprvResp" BU_SG_REL_ EPS_CE SG_ 823 SWAR_ReqActV 1;
BA_REL_ "GenSigTimeoutMsg" BU_SG_REL_ EPS_CE SG_ 823 SWAR_ReqActV 823;
BA_REL_ "GenSigTimeoutTime" BU_SG_REL_ EPS_CE SG_ 823 SWAR_ReqActV 250;
BA_REL_ "GenSigSuprvResp" BU_SG_REL_ EPS_JR_CE SG_ 823 SWAR_ReqAct 1;
BA_REL_ "GenSigTimeoutMsg" BU_SG_REL_ EPS_JR_CE SG_ 823 SWAR_ReqAct 823;
BA_REL_ "GenSigTimeoutTime" BU_SG_REL_ EPS_JR_CE SG_ 823 SWAR_ReqAct 250;
BA_REL_ "GenSigSuprvResp" BU_SG_REL_ EPS_CE SG_ 823 SWAR_ReqAct 1;
BA_REL_ "GenSigTimeoutMsg" BU_SG_REL_ EPS_CE SG_ 823 SWAR_ReqAct 823;
BA_REL_ "GenSigTimeoutTime" BU_SG_REL_ EPS_CE SG_ 823 SWAR_ReqAct 250;
BA_REL_ "GenSigSuprvResp" BU_SG_REL_ EPS_JR_CE SG_ 823 StrWhlTctlFdbkReqActRC 1;
BA_REL_ "GenSigTimeoutMsg" BU_SG_REL_ EPS_JR_CE SG_ 823 StrWhlTctlFdbkReqActRC 823;
BA_REL_ "GenSigTimeoutTime" BU_SG_REL_ EPS_JR_CE SG_ 823 StrWhlTctlFdbkReqActRC 250;
BA_REL_ "GenSigSuprvResp" BU_SG_REL_ EPS_JR_CE SG_ 823 StrWhlTctlFdbkReqAct 1;
BA_REL_ "GenSigTimeoutMsg" BU_SG_REL_ EPS_JR_CE SG_ 823 StrWhlTctlFdbkReqAct 823;
BA_REL_ "GenSigTimeoutTime" BU_SG_REL_ EPS_JR_CE SG_ 823 StrWhlTctlFdbkReqAct 250;
BA_REL_ "GenSigSuprvResp" BU_SG_REL_ RDCM_CE SG_ 1225 TransOilTempSensPres 1;
BA_REL_ "GenSigTimeoutMsg" BU_SG_REL_ RDCM_CE SG_ 1225 TransOilTempSensPres 1225;
BA_REL_ "GenSigTimeoutTime" BU_SG_REL_ RDCM_CE SG_ 1225 TransOilTempSensPres 1250;
BA_REL_ "GenSigSuprvResp" BU_SG_REL_ RDCM_CE SG_ 1225 TrnOilTmp 1;
BA_REL_ "GenSigTimeoutMsg" BU_SG_REL_ RDCM_CE SG_ 1225 TrnOilTmp 1225;
BA_REL_ "GenSigTimeoutTime" BU_SG_REL_ RDCM_CE SG_ 1225 TrnOilTmp 1250;
BA_REL_ "GenSigSuprvResp" BU_SG_REL_ RDCM_CE SG_ 1009 OtsAirTmpCrVal 1;
BA_REL_ "GenSigTimeoutMsg" BU_SG_REL_ RDCM_CE SG_ 1009 OtsAirTmpCrVal 1009;
BA_REL_ "GenSigTimeoutTime" BU_SG_REL_ RDCM_CE SG_ 1009 OtsAirTmpCrVal 625;
BA_REL_ "GenSigSuprvResp" BU_SG_REL_ RDCM_CE SG_ 536 VehOdo 1;
BA_REL_ "GenSigTimeoutMsg" BU_SG_REL_ RDCM_CE SG_ 536 VehOdo 536;
BA_REL_ "GenSigTimeoutTime" BU_SG_REL_ RDCM_CE SG_ 536 VehOdo 250;
BA_REL_ "GenSigSuprvResp" BU_SG_REL_ ARS_CE SG_ 1001 VehSpdAvgNDrvn 1;
BA_REL_ "GenSigTimeoutMsg" BU_SG_REL_ ARS_CE SG_ 1001 VehSpdAvgNDrvn 1001;
BA_REL_ "GenSigTimeoutTime" BU_SG_REL_ ARS_CE SG_ 1001 VehSpdAvgNDrvn 250;
BA_REL_ "GenSigSuprvResp" BU_SG_REL_ SDM_CE SG_ 1001 VehSpdAvgNDrvn 1;
BA_REL_ "GenSigTimeoutMsg" BU_SG_REL_ SDM_CE SG_ 1001 VehSpdAvgNDrvn 1001;
BA_REL_ "GenSigTimeoutTime" BU_SG_REL_ SDM_CE SG_ 1001 VehSpdAvgNDrvn 250;
BA_REL_ "GenSigSuprvResp" BU_SG_REL_ FCM_CE SG_ 1001 VehSpdAvgNDrvn 1;
BA_REL_ "GenSigTimeoutMsg" BU_SG_REL_ FCM_CE SG_ 1001 VehSpdAvgNDrvn 1001;
BA_REL_ "GenSigTimeoutTime" BU_SG_REL_ FCM_CE SG_ 1001 VehSpdAvgNDrvn 250;
BA_REL_ "GenSigSuprvResp" BU_SG_REL_ ARS_CE SG_ 1001 VehSpdAvgDrvnSrc 1;
BA_REL_ "GenSigTimeoutMsg" BU_SG_REL_ ARS_CE SG_ 1001 VehSpdAvgDrvnSrc 1001;
BA_REL_ "GenSigTimeoutTime" BU_SG_REL_ ARS_CE SG_ 1001 VehSpdAvgDrvnSrc 250;
BA_REL_ "GenSigSuprvResp" BU_SG_REL_ EPS_CE SG_ 1001 VehSpdAvgDrvnSrc 1;
BA_REL_ "GenSigTimeoutMsg" BU_SG_REL_ EPS_CE SG_ 1001 VehSpdAvgDrvnSrc 1001;
BA_REL_ "GenSigTimeoutTime" BU_SG_REL_ EPS_CE SG_ 1001 VehSpdAvgDrvnSrc 250;
BA_REL_ "GenSigSuprvResp" BU_SG_REL_ ARS_CE SG_ 1001 VehSpdAvgDrvn 1;
BA_REL_ "GenSigTimeoutMsg" BU_SG_REL_ ARS_CE SG_ 1001 VehSpdAvgDrvn 1001;
BA_REL_ "GenSigTimeoutTime" BU_SG_REL_ ARS_CE SG_ 1001 VehSpdAvgDrvn 250;
BA_REL_ "GenSigSuprvResp" BU_SG_REL_ SDM_CE SG_ 1001 VehSpdAvgDrvn 1;
BA_REL_ "GenSigTimeoutMsg" BU_SG_REL_ SDM_CE SG_ 1001 VehSpdAvgDrvn 1001;
BA_REL_ "GenSigTimeoutTime" BU_SG_REL_ SDM_CE SG_ 1001 VehSpdAvgDrvn 250;
BA_REL_ "GenSigSuprvResp" BU_SG_REL_ FCM_CE SG_ 1001 VehSpdAvgDrvn 1;
BA_REL_ "GenSigTimeoutMsg" BU_SG_REL_ FCM_CE SG_ 1001 VehSpdAvgDrvn 1001;
BA_REL_ "GenSigTimeoutTime" BU_SG_REL_ FCM_CE SG_ 1001 VehSpdAvgDrvn 250;
BA_REL_ "GenSigSuprvResp" BU_SG_REL_ EPS_CE SG_ 1001 VehSpdAvgDrvn 1;
BA_REL_ "GenSigTimeoutMsg" BU_SG_REL_ EPS_CE SG_ 1001 VehSpdAvgDrvn 1001;
BA_REL_ "GenSigTimeoutTime" BU_SG_REL_ EPS_CE SG_ 1001 VehSpdAvgDrvn 250;
BA_REL_ "GenSigSuprvResp" BU_SG_REL_ MSB1_CE SG_ 298 CrshAlrtStPrsnt 1;
BA_REL_ "GenSigTimeoutMsg" BU_SG_REL_ MSB1_CE SG_ 298 CrshAlrtStPrsnt 298;
BA_REL_ "GenSigTimeoutTime" BU_SG_REL_ MSB1_CE SG_ 298 CrshAlrtStPrsnt 250;
BA_REL_ "GenSigSuprvResp" BU_SG_REL_ MSB2_CE SG_ 298 CrshAlrtStPrsnt 1;
BA_REL_ "GenSigTimeoutMsg" BU_SG_REL_ MSB2_CE SG_ 298 CrshAlrtStPrsnt 298;
BA_REL_ "GenSigTimeoutTime" BU_SG_REL_ MSB2_CE SG_ 298 CrshAlrtStPrsnt 250;
BA_REL_ "GenSigSuprvResp" BU_SG_REL_ MSB1_CE SG_ 298 StBltTgtCSRq 1;
BA_REL_ "GenSigTimeoutMsg" BU_SG_REL_ MSB1_CE SG_ 298 StBltTgtCSRq 298;
BA_REL_ "GenSigTimeoutTime" BU_SG_REL_ MSB1_CE SG_ 298 StBltTgtCSRq 250;
BA_REL_ "GenSigSuprvResp" BU_SG_REL_ MSB2_CE SG_ 298 StBltTgtCSRq 1;
BA_REL_ "GenSigTimeoutMsg" BU_SG_REL_ MSB2_CE SG_ 298 StBltTgtCSRq 298;
BA_REL_ "GenSigTimeoutTime" BU_SG_REL_ MSB2_CE SG_ 298 StBltTgtCSRq 250;
BA_REL_ "GenSigSuprvResp" BU_SG_REL_ EBCM_OBD_CE SG_ 460 SecAxlThrmlCapPRqAt 1;
BA_REL_ "GenSigTimeoutMsg" BU_SG_REL_ EBCM_OBD_CE SG_ 460 SecAxlThrmlCapPRqAt 460;
BA_REL_ "GenSigTimeoutTime" BU_SG_REL_ EBCM_OBD_CE SG_ 460 SecAxlThrmlCapPRqAt 250;
BA_REL_ "GenSigSuprvResp" BU_SG_REL_ EBCM_CE SG_ 460 SecAxlThrmlCapPRqAt 1;
BA_REL_ "GenSigTimeoutMsg" BU_SG_REL_ EBCM_CE SG_ 460 SecAxlThrmlCapPRqAt 460;
BA_REL_ "GenSigTimeoutTime" BU_SG_REL_ EBCM_CE SG_ 460 SecAxlThrmlCapPRqAt 250;
BA_REL_ "GenSigSuprvResp" BU_SG_REL_ EBCM_OBD_CE SG_ 460 SecAxlThrmlCap 1;
BA_REL_ "GenSigTimeoutMsg" BU_SG_REL_ EBCM_OBD_CE SG_ 460 SecAxlThrmlCap 460;
BA_REL_ "GenSigTimeoutTime" BU_SG_REL_ EBCM_OBD_CE SG_ 460 SecAxlThrmlCap 250;
BA_REL_ "GenSigSuprvResp" BU_SG_REL_ EBCM_CE SG_ 460 SecAxlThrmlCap 1;
BA_REL_ "GenSigTimeoutMsg" BU_SG_REL_ EBCM_CE SG_ 460 SecAxlThrmlCap 460;
BA_REL_ "GenSigTimeoutTime" BU_SG_REL_ EBCM_CE SG_ 460 SecAxlThrmlCap 250;
BA_REL_ "GenSigSuprvResp" BU_SG_REL_ EBCM_OBD_CE SG_ 560 RegenBrkAxTrqAch 1;
BA_REL_ "GenSigTimeoutMsg" BU_SG_REL_ EBCM_OBD_CE SG_ 560 RegenBrkAxTrqAch 560;
BA_REL_ "GenSigTimeoutTime" BU_SG_REL_ EBCM_OBD_CE SG_ 560 RegenBrkAxTrqAch 250;
BA_REL_ "GenSigSuprvResp" BU_SG_REL_ EBCM_CE SG_ 560 RegenBrkAxTrqAch 1;
BA_REL_ "GenSigTimeoutMsg" BU_SG_REL_ EBCM_CE SG_ 560 RegenBrkAxTrqAch 560;
BA_REL_ "GenSigTimeoutTime" BU_SG_REL_ EBCM_CE SG_ 560 RegenBrkAxTrqAch 250;
BA_REL_ "GenSigSuprvResp" BU_SG_REL_ EPS_JR_CE SG_ 565 BrkPdlDrvApplPres 1;
BA_REL_ "GenSigTimeoutMsg" BU_SG_REL_ EPS_JR_CE SG_ 565 BrkPdlDrvApplPres 565;
BA_REL_ "GenSigTimeoutTime" BU_SG_REL_ EPS_JR_CE SG_ 565 BrkPdlDrvApplPres 250;
BA_REL_ "GenSigSuprvResp" BU_SG_REL_ EBCM_OBD_CE SG_ 866 CPSInfotmntMtReq 1;
BA_REL_ "GenSigTimeoutMsg" BU_SG_REL_ EBCM_OBD_CE SG_ 866 CPSInfotmntMtReq 866;
BA_REL_ "GenSigTimeoutTime" BU_SG_REL_ EBCM_OBD_CE SG_ 866 CPSInfotmntMtReq 250;
BA_REL_ "GenSigSuprvResp" BU_SG_REL_ EBCM_CE SG_ 866 CPSInfotmntMtReq 1;
BA_REL_ "GenSigTimeoutMsg" BU_SG_REL_ EBCM_CE SG_ 866 CPSInfotmntMtReq 866;
BA_REL_ "GenSigTimeoutTime" BU_SG_REL_ EBCM_CE SG_ 866 CPSInfotmntMtReq 250;
BA_REL_ "GenSigSuprvResp" BU_SG_REL_ EBCM_OBD_CE SG_ 866 StBltTgtSetAvl 1;
BA_REL_ "GenSigTimeoutMsg" BU_SG_REL_ EBCM_OBD_CE SG_ 866 StBltTgtSetAvl 866;
BA_REL_ "GenSigTimeoutTime" BU_SG_REL_ EBCM_OBD_CE SG_ 866 StBltTgtSetAvl 250;
BA_REL_ "GenSigSuprvResp" BU_SG_REL_ EBCM_CE SG_ 866 StBltTgtSetAvl 1;
BA_REL_ "GenSigTimeoutMsg" BU_SG_REL_ EBCM_CE SG_ 866 StBltTgtSetAvl 866;
BA_REL_ "GenSigTimeoutTime" BU_SG_REL_ EBCM_CE SG_ 866 StBltTgtSetAvl 250;
BA_REL_ "GenSigSuprvResp" BU_SG_REL_ EBCM_OBD_CE SG_ 866 StBltTgtCrtSetVal 1;
BA_REL_ "GenSigTimeoutMsg" BU_SG_REL_ EBCM_OBD_CE SG_ 866 StBltTgtCrtSetVal 866;
BA_REL_ "GenSigTimeoutTime" BU_SG_REL_ EBCM_OBD_CE SG_ 866 StBltTgtCrtSetVal 250;
BA_REL_ "GenSigSuprvResp" BU_SG_REL_ EBCM_CE SG_ 866 StBltTgtCrtSetVal 1;
BA_REL_ "GenSigTimeoutMsg" BU_SG_REL_ EBCM_CE SG_ 866 StBltTgtCrtSetVal 866;
BA_REL_ "GenSigTimeoutTime" BU_SG_REL_ EBCM_CE SG_ 866 StBltTgtCrtSetVal 250;
BA_REL_ "GenSigSuprvResp" BU_SG_REL_ EBCM_OBD_CE SG_ 866 MotStBltUnblIO 1;
BA_REL_ "GenSigTimeoutMsg" BU_SG_REL_ EBCM_OBD_CE SG_ 866 MotStBltUnblIO 866;
BA_REL_ "GenSigTimeoutTime" BU_SG_REL_ EBCM_OBD_CE SG_ 866 MotStBltUnblIO 250;
BA_REL_ "GenSigSuprvResp" BU_SG_REL_ EBCM_CE SG_ 866 MotStBltUnblIO 1;
BA_REL_ "GenSigTimeoutMsg" BU_SG_REL_ EBCM_CE SG_ 866 MotStBltUnblIO 866;
BA_REL_ "GenSigTimeoutTime" BU_SG_REL_ EBCM_CE SG_ 866 MotStBltUnblIO 250;
BA_REL_ "GenSigSuprvResp" BU_SG_REL_ EBCM_OBD_CE SG_ 866 MotStBltFldIO 1;
BA_REL_ "GenSigTimeoutMsg" BU_SG_REL_ EBCM_OBD_CE SG_ 866 MotStBltFldIO 866;
BA_REL_ "GenSigTimeoutTime" BU_SG_REL_ EBCM_OBD_CE SG_ 866 MotStBltFldIO 250;
BA_REL_ "GenSigSuprvResp" BU_SG_REL_ EBCM_CE SG_ 866 MotStBltFldIO 1;
BA_REL_ "GenSigTimeoutMsg" BU_SG_REL_ EBCM_CE SG_ 866 MotStBltFldIO 866;
BA_REL_ "GenSigTimeoutTime" BU_SG_REL_ EBCM_CE SG_ 866 MotStBltFldIO 250;
BA_REL_ "GenSigSuprvResp" BU_SG_REL_ EBCM_OBD_CE SG_ 866 ColPrSysWndwsReq 1;
BA_REL_ "GenSigTimeoutMsg" BU_SG_REL_ EBCM_OBD_CE SG_ 866 ColPrSysWndwsReq 866;
BA_REL_ "GenSigTimeoutTime" BU_SG_REL_ EBCM_OBD_CE SG_ 866 ColPrSysWndwsReq 250;
BA_REL_ "GenSigSuprvResp" BU_SG_REL_ EBCM_CE SG_ 866 ColPrSysWndwsReq 1;
BA_REL_ "GenSigTimeoutMsg" BU_SG_REL_ EBCM_CE SG_ 866 ColPrSysWndwsReq 866;
BA_REL_ "GenSigTimeoutTime" BU_SG_REL_ EBCM_CE SG_ 866 ColPrSysWndwsReq 250;
BA_REL_ "GenSigSuprvResp" BU_SG_REL_ EBCM_OBD_CE SG_ 866 ColPrSysSnrfReq 1;
BA_REL_ "GenSigTimeoutMsg" BU_SG_REL_ EBCM_OBD_CE SG_ 866 ColPrSysSnrfReq 866;
BA_REL_ "GenSigTimeoutTime" BU_SG_REL_ EBCM_OBD_CE SG_ 866 ColPrSysSnrfReq 250;
BA_REL_ "GenSigSuprvResp" BU_SG_REL_ EBCM_CE SG_ 866 ColPrSysSnrfReq 1;
BA_REL_ "GenSigTimeoutMsg" BU_SG_REL_ EBCM_CE SG_ 866 ColPrSysSnrfReq 866;
BA_REL_ "GenSigTimeoutTime" BU_SG_REL_ EBCM_CE SG_ 866 ColPrSysSnrfReq 250;
BA_REL_ "GenSigSuprvResp" BU_SG_REL_ EBCM_OBD_CE SG_ 866 ColPrSysHzrdLghtsReq 1;
BA_REL_ "GenSigTimeoutMsg" BU_SG_REL_ EBCM_OBD_CE SG_ 866 ColPrSysHzrdLghtsReq 866;
BA_REL_ "GenSigTimeoutTime" BU_SG_REL_ EBCM_OBD_CE SG_ 866 ColPrSysHzrdLghtsReq 250;
BA_REL_ "GenSigSuprvResp" BU_SG_REL_ EBCM_CE SG_ 866 ColPrSysHzrdLghtsReq 1;
BA_REL_ "GenSigTimeoutMsg" BU_SG_REL_ EBCM_CE SG_ 866 ColPrSysHzrdLghtsReq 866;
BA_REL_ "GenSigTimeoutTime" BU_SG_REL_ EBCM_CE SG_ 866 ColPrSysHzrdLghtsReq 250;
BA_REL_ "GenSigSuprvResp" BU_SG_REL_ EBCM_OBD_CE SG_ 866 ColPrSysDrsReq 1;
BA_REL_ "GenSigTimeoutMsg" BU_SG_REL_ EBCM_OBD_CE SG_ 866 ColPrSysDrsReq 866;
BA_REL_ "GenSigTimeoutTime" BU_SG_REL_ EBCM_OBD_CE SG_ 866 ColPrSysDrsReq 250;
BA_REL_ "GenSigSuprvResp" BU_SG_REL_ EBCM_CE SG_ 866 ColPrSysDrsReq 1;
BA_REL_ "GenSigTimeoutMsg" BU_SG_REL_ EBCM_CE SG_ 866 ColPrSysDrsReq 866;
BA_REL_ "GenSigTimeoutTime" BU_SG_REL_ EBCM_CE SG_ 866 ColPrSysDrsReq 250;
BA_REL_ "GenSigSuprvResp" BU_SG_REL_ APA_CE SG_ 821 ElcPwrStrAvalStatPVal 1;
BA_REL_ "GenSigTimeoutMsg" BU_SG_REL_ APA_CE SG_ 821 ElcPwrStrAvalStatPVal 821;
BA_REL_ "GenSigTimeoutTime" BU_SG_REL_ APA_CE SG_ 821 ElcPwrStrAvalStatPVal 250;
BA_REL_ "GenSigSuprvResp" BU_SG_REL_ APA_CE SG_ 821 ElcPwrStrAvalStatARC 1;
BA_REL_ "GenSigTimeoutMsg" BU_SG_REL_ APA_CE SG_ 821 ElcPwrStrAvalStatARC 821;
BA_REL_ "GenSigTimeoutTime" BU_SG_REL_ APA_CE SG_ 821 ElcPwrStrAvalStatARC 250;
BA_REL_ "GenSigSuprvResp" BU_SG_REL_ APA_CE SG_ 821 DrvStrIntfrDetARC 1;
BA_REL_ "GenSigTimeoutMsg" BU_SG_REL_ APA_CE SG_ 821 DrvStrIntfrDetARC 821;
BA_REL_ "GenSigTimeoutTime" BU_SG_REL_ APA_CE SG_ 821 DrvStrIntfrDetARC 250;
BA_REL_ "GenSigSuprvResp" BU_SG_REL_ APA_CE SG_ 821 DrvStrIntfrDetPrtVal 1;
BA_REL_ "GenSigTimeoutMsg" BU_SG_REL_ APA_CE SG_ 821 DrvStrIntfrDetPrtVal 821;
BA_REL_ "GenSigTimeoutTime" BU_SG_REL_ APA_CE SG_ 821 DrvStrIntfrDetPrtVal 250;
BA_REL_ "GenSigSuprvResp" BU_SG_REL_ ICCM_CE SG_ 564 RrAxLckTrqRqCplRqTp 1;
BA_REL_ "GenSigTimeoutMsg" BU_SG_REL_ ICCM_CE SG_ 564 RrAxLckTrqRqCplRqTp 564;
BA_REL_ "GenSigTimeoutTime" BU_SG_REL_ ICCM_CE SG_ 564 RrAxLckTrqRqCplRqTp 250;
BA_REL_ "GenSigSuprvResp" BU_SG_REL_ RDCM_CE SG_ 564 RrAxLckTrqRqCplRqTp 1;
BA_REL_ "GenSigTimeoutMsg" BU_SG_REL_ RDCM_CE SG_ 564 RrAxLckTrqRqCplRqTp 564;
BA_REL_ "GenSigTimeoutTime" BU_SG_REL_ RDCM_CE SG_ 564 RrAxLckTrqRqCplRqTp 250;
BA_REL_ "GenSigSuprvResp" BU_SG_REL_ ICCM_CE SG_ 564 RrAxLkTqRqCplRqTRC 1;
BA_REL_ "GenSigTimeoutMsg" BU_SG_REL_ ICCM_CE SG_ 564 RrAxLkTqRqCplRqTRC 564;
BA_REL_ "GenSigTimeoutTime" BU_SG_REL_ ICCM_CE SG_ 564 RrAxLkTqRqCplRqTRC 250;
BA_REL_ "GenSigSuprvResp" BU_SG_REL_ RDCM_CE SG_ 564 RrAxLkTqRqCplRqTRC 1;
BA_REL_ "GenSigTimeoutMsg" BU_SG_REL_ RDCM_CE SG_ 564 RrAxLkTqRqCplRqTRC 564;
BA_REL_ "GenSigTimeoutTime" BU_SG_REL_ RDCM_CE SG_ 564 RrAxLkTqRqCplRqTRC 250;
BA_REL_ "GenSigSuprvResp" BU_SG_REL_ ICCM_CE SG_ 564 RrAxLkTqRqCplRqTPVl 1;
BA_REL_ "GenSigTimeoutMsg" BU_SG_REL_ ICCM_CE SG_ 564 RrAxLkTqRqCplRqTPVl 564;
BA_REL_ "GenSigTimeoutTime" BU_SG_REL_ ICCM_CE SG_ 564 RrAxLkTqRqCplRqTPVl 250;
BA_REL_ "GenSigSuprvResp" BU_SG_REL_ RDCM_CE SG_ 564 RrAxLkTqRqCplRqTPVl 1;
BA_REL_ "GenSigTimeoutMsg" BU_SG_REL_ RDCM_CE SG_ 564 RrAxLkTqRqCplRqTPVl 564;
BA_REL_ "GenSigTimeoutTime" BU_SG_REL_ RDCM_CE SG_ 564 RrAxLkTqRqCplRqTPVl 250;
BA_REL_ "GenSigSuprvResp" BU_SG_REL_ RDCM_CE SG_ 564 RALTRCoplReqVal 1;
BA_REL_ "GenSigTimeoutMsg" BU_SG_REL_ RDCM_CE SG_ 564 RALTRCoplReqVal 564;
BA_REL_ "GenSigTimeoutTime" BU_SG_REL_ RDCM_CE SG_ 564 RALTRCoplReqVal 250;
BA_REL_ "GenSigSuprvResp" BU_SG_REL_ RDCM_CE SG_ 564 RALTRCplReqAtv 1;
BA_REL_ "GenSigTimeoutMsg" BU_SG_REL_ RDCM_CE SG_ 564 RALTRCplReqAtv 564;
BA_REL_ "GenSigTimeoutTime" BU_SG_REL_ RDCM_CE SG_ 564 RALTRCplReqAtv 250;
BA_REL_ "GenSigSuprvResp" BU_SG_REL_ SDM_CE SG_ 832 BrkPedTrvlAchvd 1;
BA_REL_ "GenSigTimeoutMsg" BU_SG_REL_ SDM_CE SG_ 832 BrkPedTrvlAchvd 832;
BA_REL_ "GenSigTimeoutTime" BU_SG_REL_ SDM_CE SG_ 832 BrkPedTrvlAchvd 250;
BA_REL_ "GenSigSuprvResp" BU_SG_REL_ MSB1_CE SG_ 832 BrkPedTrvlAchvd 1;
BA_REL_ "GenSigTimeoutMsg" BU_SG_REL_ MSB1_CE SG_ 832 BrkPedTrvlAchvd 832;
BA_REL_ "GenSigTimeoutTime" BU_SG_REL_ MSB1_CE SG_ 832 BrkPedTrvlAchvd 250;
BA_REL_ "GenSigSuprvResp" BU_SG_REL_ MSB2_CE SG_ 832 BrkPedTrvlAchvd 1;
BA_REL_ "GenSigTimeoutMsg" BU_SG_REL_ MSB2_CE SG_ 832 BrkPedTrvlAchvd 832;
BA_REL_ "GenSigTimeoutTime" BU_SG_REL_ MSB2_CE SG_ 832 BrkPedTrvlAchvd 250;
BA_REL_ "GenSigSuprvResp" BU_SG_REL_ EPS_JR_CE SG_ 832 BrkPedTrvlAchvd 1;
BA_REL_ "GenSigTimeoutMsg" BU_SG_REL_ EPS_JR_CE SG_ 832 BrkPedTrvlAchvd 832;
BA_REL_ "GenSigTimeoutTime" BU_SG_REL_ EPS_JR_CE SG_ 832 BrkPedTrvlAchvd 250;
BA_REL_ "GenSigSuprvResp" BU_SG_REL_ SDM_CE SG_ 832 BrkPedTrvlAchvdV 1;
BA_REL_ "GenSigTimeoutMsg" BU_SG_REL_ SDM_CE SG_ 832 BrkPedTrvlAchvdV 832;
BA_REL_ "GenSigTimeoutTime" BU_SG_REL_ SDM_CE SG_ 832 BrkPedTrvlAchvdV 250;
BA_REL_ "GenSigSuprvResp" BU_SG_REL_ MSB1_CE SG_ 832 BrkPedTrvlAchvdV 1;
BA_REL_ "GenSigTimeoutMsg" BU_SG_REL_ MSB1_CE SG_ 832 BrkPedTrvlAchvdV 832;
BA_REL_ "GenSigTimeoutTime" BU_SG_REL_ MSB1_CE SG_ 832 BrkPedTrvlAchvdV 250;
BA_REL_ "GenSigSuprvResp" BU_SG_REL_ MSB2_CE SG_ 832 BrkPedTrvlAchvdV 1;
BA_REL_ "GenSigTimeoutMsg" BU_SG_REL_ MSB2_CE SG_ 832 BrkPedTrvlAchvdV 832;
BA_REL_ "GenSigTimeoutTime" BU_SG_REL_ MSB2_CE SG_ 832 BrkPedTrvlAchvdV 250;
BA_REL_ "GenSigSuprvResp" BU_SG_REL_ EPS_JR_CE SG_ 832 BrkPedTrvlAchvdV 1;
BA_REL_ "GenSigTimeoutMsg" BU_SG_REL_ EPS_JR_CE SG_ 832 BrkPedTrvlAchvdV 832;
BA_REL_ "GenSigTimeoutTime" BU_SG_REL_ EPS_JR_CE SG_ 832 BrkPedTrvlAchvdV 250;
BA_REL_ "GenSigSuprvResp" BU_SG_REL_ EPS_JR_CE SG_ 832 BrkPdlInTrvPrt 1;
BA_REL_ "GenSigTimeoutMsg" BU_SG_REL_ EPS_JR_CE SG_ 832 BrkPdlInTrvPrt 832;
BA_REL_ "GenSigTimeoutTime" BU_SG_REL_ EPS_JR_CE SG_ 832 BrkPdlInTrvPrt 250;
BA_REL_ "GenSigSuprvResp" BU_SG_REL_ FCM_CE SG_ 832 AccActPos 1;
BA_REL_ "GenSigTimeoutMsg" BU_SG_REL_ FCM_CE SG_ 832 AccActPos 832;
BA_REL_ "GenSigTimeoutTime" BU_SG_REL_ FCM_CE SG_ 832 AccActPos 250;
BA_REL_ "GenSigSuprvResp" BU_SG_REL_ MSB1_CE SG_ 832 AccActPos 1;
BA_REL_ "GenSigTimeoutMsg" BU_SG_REL_ MSB1_CE SG_ 832 AccActPos 832;
BA_REL_ "GenSigTimeoutTime" BU_SG_REL_ MSB1_CE SG_ 832 AccActPos 250;
BA_REL_ "GenSigSuprvResp" BU_SG_REL_ MSB2_CE SG_ 832 AccActPos 1;
BA_REL_ "GenSigTimeoutMsg" BU_SG_REL_ MSB2_CE SG_ 832 AccActPos 832;
BA_REL_ "GenSigTimeoutTime" BU_SG_REL_ MSB2_CE SG_ 832 AccActPos 250;
BA_REL_ "GenSigSuprvResp" BU_SG_REL_ ARS_CE SG_ 832 WhlDistPrRevNDrvn 1;
BA_REL_ "GenSigTimeoutMsg" BU_SG_REL_ ARS_CE SG_ 832 WhlDistPrRevNDrvn 832;
BA_REL_ "GenSigTimeoutTime" BU_SG_REL_ ARS_CE SG_ 832 WhlDistPrRevNDrvn 250;
BA_REL_ "GenSigSuprvResp" BU_SG_REL_ EPS_CE SG_ 832 WhlDistPrRevNDrvn 1;
BA_REL_ "GenSigTimeoutMsg" BU_SG_REL_ EPS_CE SG_ 832 WhlDistPrRevNDrvn 832;
BA_REL_ "GenSigTimeoutTime" BU_SG_REL_ EPS_CE SG_ 832 WhlDistPrRevNDrvn 250;
BA_REL_ "GenSigSuprvResp" BU_SG_REL_ EPS_JR_CE SG_ 832 WhlDistPrRevNDrvn 1;
BA_REL_ "GenSigTimeoutMsg" BU_SG_REL_ EPS_JR_CE SG_ 832 WhlDistPrRevNDrvn 832;
BA_REL_ "GenSigTimeoutTime" BU_SG_REL_ EPS_JR_CE SG_ 832 WhlDistPrRevNDrvn 250;
BA_REL_ "GenSigSuprvResp" BU_SG_REL_ ARS_CE SG_ 832 WhlDistPrRevDrvn 1;
BA_REL_ "GenSigTimeoutMsg" BU_SG_REL_ ARS_CE SG_ 832 WhlDistPrRevDrvn 832;
BA_REL_ "GenSigTimeoutTime" BU_SG_REL_ ARS_CE SG_ 832 WhlDistPrRevDrvn 250;
BA_REL_ "GenSigSuprvResp" BU_SG_REL_ EPS_JR_CE SG_ 832 WhlDistPrRevDrvn 1;
BA_REL_ "GenSigTimeoutMsg" BU_SG_REL_ EPS_JR_CE SG_ 832 WhlDistPrRevDrvn 832;
BA_REL_ "GenSigTimeoutTime" BU_SG_REL_ EPS_JR_CE SG_ 832 WhlDistPrRevDrvn 250;
BA_REL_ "GenSigSuprvResp" BU_SG_REL_ EPS_CE SG_ 832 WhlDistPrRevDrvn 1;
BA_REL_ "GenSigTimeoutMsg" BU_SG_REL_ EPS_CE SG_ 832 WhlDistPrRevDrvn 832;
BA_REL_ "GenSigTimeoutTime" BU_SG_REL_ EPS_CE SG_ 832 WhlDistPrRevDrvn 250;
BA_REL_ "GenSigSuprvResp" BU_SG_REL_ RDCM_CE SG_ 462 SecAxlLkTqRqCplRqTp 1;
BA_REL_ "GenSigTimeoutMsg" BU_SG_REL_ RDCM_CE SG_ 462 SecAxlLkTqRqCplRqTp 462;
BA_REL_ "GenSigTimeoutTime" BU_SG_REL_ RDCM_CE SG_ 462 SecAxlLkTqRqCplRqTp 250;
BA_REL_ "GenSigSuprvResp" BU_SG_REL_ RDCM_CE SG_ 462 SATRCplReqVal 1;
BA_REL_ "GenSigTimeoutMsg" BU_SG_REL_ RDCM_CE SG_ 462 SATRCplReqVal 462;
BA_REL_ "GenSigTimeoutTime" BU_SG_REL_ RDCM_CE SG_ 462 SATRCplReqVal 250;
BA_REL_ "GenSigSuprvResp" BU_SG_REL_ RDCM_CE SG_ 462 SATRCplReqAtv 1;
BA_REL_ "GenSigTimeoutMsg" BU_SG_REL_ RDCM_CE SG_ 462 SATRCplReqAtv 462;
BA_REL_ "GenSigTimeoutTime" BU_SG_REL_ RDCM_CE SG_ 462 SATRCplReqAtv 250;
VAL_ 532 EBrkAstOtptRdPosStat 2 "Faulted" 1 "Not Initialized" 0 "Normal" ;
VAL_ 532 EBrkAstPresBlndgCapV 1 "Invalid" 0 "Valid" ;
VAL_ 530 ABSFld 1 "true" 0 "false" ;
VAL_ 530 BPDAPS_BkPDrvApPV 1 "Invalid" 0 "Valid" ;
VAL_ 530 ABSAtv 1 "true" 0 "false" ;
VAL_ 530 NotEventStat 2 "Pretensioner Deployment Event" 1 "Near Deployment Event" 0 "No Event" 3 "Airbag Deployment Event" ;
VAL_ 530 BrkAppSnsrHmPosLrnd 1 "true" 0 "false" ;
VAL_ 530 BrkPdlModTrvlV 1 "Invalid" 0 "Valid" ;
VAL_ 530 BrkPdlModTrvl 1 "true" 0 "false" ;
VAL_ 530 PrplsnSysAtv 1 "true" 0 "false" ;
VAL_ 384 TqOvrDltTqCmdAct 0 "Inactive" 1 "Active" ;
VAL_ 869 ClsnJmntLnPssdV 1 "Invalid" 0 "Valid" ;
VAL_ 869 ClsnJmntLnPssd 1 "true" 0 "false" ;
VAL_ 869 ColPrSysCrntStng 0 "No Action" 1 "Off" 2 "Alert" 3 "Alert and Brake" ;
VAL_ 370 ARSAnglCmdAct 3 "Active" 2 "Unused" 1 "Inactive with Energy Saving" 0 "Inactive" ;
VAL_ 374 ARSOpStat 0 "Normal" 1 "

Temporarily Unavailable" 2 "Reduced Performance" 3 "Failed" ;
VAL_ 374 ARSAlgmtCmplt 1 "true" 0 "false" ;
VAL_ 374 ARSActAnglV 1 "Invalid" 0 "Valid" ;
VAL_ 369 APABR_AutBrkRmpRt 2 "Full" 1 "Light" 0 "None" ;
VAL_ 369 APABR_AutBrkRqTyp 8 "Object Detected/Confirmation" 7 "Reserved" 6 "Reserved" 5 "Hold" 4 "Apply Park Brake" 3 "Brake Per Requested Decel" 2 "Reserved" 1 "Prefill" 0 "None" ;
VAL_ 369 APABR_AutBrkRqd 1 "true" 0 "false" ;
VAL_ 369 APABR_APA2Pstat 4 "Active" 3 "Enabled" 2 "Standby enabled" 1 "Disabled" 0 "Off" ;
VAL_ 197 WRSLNDWhlRotStRst 1 "true" 0 "false" ;
VAL_ 197 WRSLNDWhlDistVal 1 "Invalid" 0 "Valid" ;
VAL_ 197 WRSRNDWhlRotStRst 1 "true" 0 "false" ;
VAL_ 197 WRSRNDWhlDistVal 1 "Invalid" 0 "Valid" ;
VAL_ 193 WRSLDWhlDistVal 1 "Invalid" 0 "Valid" ;
VAL_ 193 WRSLDWhlRotStatRst 1 "true" 0 "false" ;
VAL_ 193 WRSRDWhlRotStatRst 1 "true" 0 "false" ;
VAL_ 193 WRSRDWhlDistVal 1 "Invalid" 0 "Valid" ;
VAL_ 823 SWAR_ReqActV 1 "Invalid" 0 "Valid" ;
VAL_ 823 SWAR_ReqAct 1 "true" 0 "false" ;
VAL_ 823 StrWhlTctlFdbkReqAct 1 "true" 0 "false" ;
VAL_ 1225 TrnsVDA 1 "VirtualDeviceAvailable" 0 "VirtualDeviceUnavailable" ;
VAL_ 1225 TrnOilTmpV 1 "Invalid" 0 "Valid" ;
VAL_ 1225 TransOilTempSensPres 1 "true" 0 "false" ;
VAL_ 1009 OutAirTempVDA 1 "VirtualDeviceAvailable" 0 "VirtualDeviceUnavailable" ;
VAL_ 1009 OtsAirTmpCrValV 1 "Invalid" 0 "Valid" ;
VAL_ 1009 OtsAirTmpCrValMsk 0 "Don't Use Data" 1 "Use Data" ;
VAL_ 536 VehOdoV 1 "Invalid" 0 "Valid" ;
VAL_ 1003 DstRolCntAvgNonDrvnV 1 "Invalid" 0 "Valid" ;
VAL_ 1003 DstRolCntAvNDrRstOc 1 "true" 0 "false" ;
VAL_ 1003 DistRollCntAvgDrvnV 1 "Invalid" 0 "Valid" ;
VAL_ 1003 DistRollCntAvgDrvnSrc 1 "Wheel Speed" 0 "Transmission Output Speed" ;
VAL_ 1003 DstRolCntAvgDrnRstOc 1 "true" 0 "false" ;
VAL_ 1003 DistRollCntAvgDrvnM 1 "Use Data" 0 "Don't Use Data" ;
VAL_ 1001 VehSpdAvgNDrvnV 1 "Invalid" 0 "Valid" ;
VAL_ 1001 VehSpdAvgDrvnV 1 "Invalid" 0 "Valid" ;
VAL_ 1001 VehSpdAvgDrvnSrc 1 "Wheel Speed" 0 "Transmission Output Speed" ;
VAL_ 298 CrshAlrtStPrsnt 1 "true" 0 "false" ;
VAL_ 298 StBltTgtCSRq 0 "No Action" 1 "Low" 2 "Normal" 3 "Performance" 4 "Locked" ;
VAL_ 298 PsSbltAtcV 1 "Invalid" 0 "Valid" ;
VAL_ 298 PsSbltAtc 1 "true" 0 "false" ;
VAL_ 298 DrSbltAtcV 1 "Invalid" 0 "Valid" ;
VAL_ 298 DrSbltAtc 1 "true" 0 "false" ;
VAL_ 298 CrshAlrtDrvrSlctdType 0 "Chime" 1 "Seat" ;
VAL_ 789 ACCBSCE_AutBrkTp 0 "ACC Initialization" 1 "No Braking" 2 "Brake Per Decel Request" 3 "Open Loop Brake to Stop" 4 "Apply Park Brake" 5 "Hold" ;
VAL_ 789 ACCBSCE_ACCAct 1 "true" 0 "false" ;
VAL_ 800 ColPrSysFwdLkngBrkAstSReqTyp 0 "Use Base Panic Brake Assist" 1 "Brake Assist Entrance Reduction" 2 "Brake Assist Entrance Increase" ;
VAL_ 800 ColPrSysMinStopReqActV 1 "Invalid" 0 "Valid" ;
VAL_ 800 ColPrSysMinStopReqAct 1 "true" 0 "false" ;
VAL_ 800 CPSCBSC_AutoBrkReq 1 "true" 0 "false" ;
VAL_ 800 CPSCBSC_AutoBrkReqTyp 0 "None" 1 "Light" 2 "Virtual Bumper" 3 "Full" 4 "Integrated Brake Assist" 5 "Hold" ;
VAL_ 800 ColPrSysBrkPrfReq 1 "true" 0 "false" ;
VAL_ 465 RrAxlCtrlMod 1 "External" 0 "Internal" ;
VAL_ 465 RAMDVLAtv 1 "true" 0 "false" ;
VAL_ 465 RrAxlOpeMod 3 "Unknown" 2 "Locked" 1 "Active" 0 "Open" ;
VAL_ 465 RrAxlEstTrqV 1 "Invalid" 0 "Valid" ;
VAL_ 465 RrAxlStat 3 "Permanently Failed" 2 "Temporary Limited" 1 "Temporary Inhibit" 0 "Normal" ;
VAL_ 460 SecAxlThrmlCapV 1 "Invalid" 0 "Valid" ;
VAL_ 460 SecAxlThrmlCapPRqAt 1 "true" 0 "false" ;
VAL_ 460 SecAxlStat 3 "Permanently Failed" 2 "Temporary Limited" 1 "Temporary Inhibit" 0 "Normal" ;
VAL_ 460 SecAxlEstTrqV 1 "Invalid" 0 "Valid" ;
VAL_ 460 SecAxlCtrlMod 1 "External" 0 "Internal" ;
VAL_ 460 SAMDVLAtv 1 "true" 0 "false" ;
VAL_ 565 BrkPdlDrvApplPresV 1 "Invalid" 0 "Valid" ;
VAL_ 565 ChsSysTrnsShfBhvRq 7 "Upshift" 6 "Downshift" 5 "Minimum Inertia" 4 "Immediate Mode" 3 "Inhibit Shift" 2 "Inhibit Upshift" 1 "Inhibit Downshift" 0 "No Action" ;
VAL_ 866 CPSInfotmntMtReq 0 "No Mute" 1 "Unused and Reserved 1" 2 "Unused and Reserved 2" 3 "Mute" ;
VAL_ 866 StBltTgtSetAvl 1 "true" 0 "false" ;
VAL_ 866 StBltTgtCrtSetVal 0 "No Action" 1 "Low" 2 "Normal" 3 "Performance" 4 "Locked" ;
VAL_ 866 MotStBltUnblIO 1 "true" 0 "false" ;
VAL_ 866 MotStBltFldIO 1 "true" 0 "false" ;
VAL_ 866 ColPrSysWndwsReq 0 "No Action" 1 "Close" 2 "Open" 3 "Reserved" ;
VAL_ 866 ColPrSysSnrfReq 0 "No Action" 1 "Close" 2 "Open" 3 "Reserved" ;
VAL_ 866 ColPrSysHzrdLghtsReq 0 "No Action" 1 "Activate" 2 "Deactivate" 3 "Reserved" ;
VAL_ 866 ColPrSysDrsReq 0 "No Action" 1 "Lock All" 2 "Unlock All" 3 "Reserved" ;
VAL_ 801 RDCPSCBSC_AutoBrkReq 0 "True" 1 "False" ;
VAL_ 801 RDCPSCBSC_AutoBrkReqTyp 5 "Hold" 0 "None" 1 "Light" 2 "Virtual Bumper" 3 "Full" 4 "Integrated Brake Assist" ;
VAL_ 821 ElecPwrStrAvalStat 0 "Temp inhibit" 1 "Available for control" 2 "Active" 3 "Permanently failed" ;
VAL_ 821 DrvStrIntfrDtcdV 1 "Invalid" 0 "Valid" ;
VAL_ 821 DrvStrIntfrDtcd 1 "true" 0 "false" ;
VAL_ 564 RrAxLckTrqRqCplRqTp 0 "No Action" 1 "Maximum Allowed Torque" 2 "Minimum Allowed Torque" 3 "Control To Requested Torque" ;
VAL_ 564 RALTRCplReqAtv 1 "true" 0 "false" ;
VAL_ 832 BrkPedTrvlAchvd 1 "true" 0 "false" ;
VAL_ 832 BrkPedTrvlAchvdV 1 "Invalid" 0 "Valid" ;
VAL_ 832 AccActPosV 1 "Invalid" 0 "Valid" ;
VAL_ 462 SecAxlLkTqRqCplRqTp 0 "No Action" 1 "Maximum Allowed Torque" 2 "Minimum Allowed Torque" 3 "Control To Requested Torque" ;
VAL_ 462 SATRCplReqAtv 1 "true" 0 "false" ;
SIG_GROUP_ 530 BrkPdDrvAppPrsStat 1 : BPDAPS_BkPDrvApPV BPDAPS_BkPDrvApP;
SIG_GROUP_ 369 APABrkReq 1 : APABR_CtrlAcc APABR_AutBrkRmpRt APABR_AutBrkRqTyp APABR_AutBrkRqd APABR_APA2Pstat;
SIG_GROUP_ 197 WhlRotStatLftNDrvn 1 : WRSLNDWhlDisTpRC WRSLNDWhlRotStRst WRSLNDWhlDistVal WRSLNDWhlDistTstm WRSLNDWhlDistPCntr WRSLNDSeqNum;
SIG_GROUP_ 197 WhlRotStatRghtNDrvn 1 : WRSRNDWhlDisTpRC WRSRNDWhlRotStRst WRSRNDWhlDistVal WRSRNDWhlDistTstm WRSRNDWhlDistPCntr WRSRNDSeqNum;
SIG_GROUP_ 193 WhlRotatStatLftDrvn 1 : WRSLDWhlDisTpRC WRSLDSeqNum WRSLDWhlDistVal WRSLDWhlRotStatRst WRSLDWhlDistTmstm WRSLDWhlDistPlsCntr;
SIG_GROUP_ 193 WhlRotatStatRtDrvn 1 : WRSRDWhlDisTpRC WRSRDSeqNum WRSRDWhlRotStatRst WRSRDWhlDistVal WRSRDWhlDistTmstm WRSRDWhlDistPlsCntr;
SIG_GROUP_ 823 StrWhlAngReq 1 : SWAR_TrgtAng SWAR_ReqActV SWAR_ReqAct;
SIG_GROUP_ 789 ACCBrkSysCmmndExt 1 : ACCBSCE_AutBrkTp ACCBSCE_ACCAct ACCBSCE_ACCAccl;
SIG_GROUP_ 800 ColPrSysCtrlBrkSysCmd 1 : CPSCBSC_CtrlAcc CPSCBSC_AutoBrkReq CPSCBSC_AutoBrkReqTyp;
SIG_GROUP_ 465 RrAxlMaxDifVelLm 1 : RAMDVLReqVal RAMDVLAtv;
SIG_GROUP_ 460 SecAxlMaxDifVelLm 1 : SAMDVLReqVal SAMDVLAtv;
SIG_GROUP_ 801 RnDgCPSCtrlBrkSysCmd 1 : RDCPSCBSC_CtrlAcc RDCPSCBSC_AutoBrkReq RDCPSCBSC_AutoBrkReqTyp;
SIG_GROUP_ 564 RrAxlLockTrqReq 1 : RALTRCoplReqVal RALTRCplReqAtv;
SIG_GROUP_ 832 BrkPedInitTrvlAchvdStat 1 : BrkPedTrvlAchvd BrkPedTrvlAchvdV;
SIG_GROUP_ 462 SecAxlTrqReq 1 : SATRCplReqVal SATRCplReqAtv;
